VERSION ""

NS_ :

BS_:

BU_: Turbocharger OnBoardDataLogger OffBoardDiagnosticTool2 OffBoardDiagnosticTool1 FileServer ParkingBrakeController SeatControl2 FanDriveController SteeringColumnUnit CommunicationUnitRadio CommunicationUnitSatellite CommunicationUnitCellular PropulsionBatteryCharger ChassisController2 ChassisController1 EngineValveControl AuxiliaryHeater2 AuxiliaryHeater1 ClutchUnit RampControl InformationSystem1 SuspensionSystemController2 OilSensor VehicleDynamicStability ExhaustEmissionController TransmissionDisplay2 TransmissionDisplay1 ClimateControl2 WaterPumpController RearAxleSteeringController LightingOperatorControl SeatController1 IgnitionController2 IgnitionController1 TirePressureController CabController2 CabController1 PneumaticSystemController SuspensionSystemController1 HydraulicPumpController EnduranceBrakingSystem RetarderExhaustEngine2 OnBoardDiagnosticUnit HeadwayController RetarderExhaustEngine1 CabDisplay1 ManagementComputer VirtualTerminal OffVehicleGateway PowerTakeOffFront HitchControl AuxiliaryValveControl BodyController TractorTrailerBridge1 StarterSystem ElectricalSystem VehicleSecurity VehicleNavigation AerodynamicControl ElectricalChargingSystem ClimateControl1 TripRecorder InstrumentCluster SuspensionDriveAxle2 SuspensionDriveAxle1 SuspensionSteerAxle SteeringController FuelSystem CruiseControl RetarderDriveline RetarderEngine BrakesDriveAxle2 BrakesDriveAxle1 BrakesSystemController BrakesSteerAxle AxleDrive2 AxleDrive1 AxleSteering PowerTakeOff ShiftConsoleSecondary ShiftConsolePrimary Transmission2 Transmission1 Engine2 Engine1

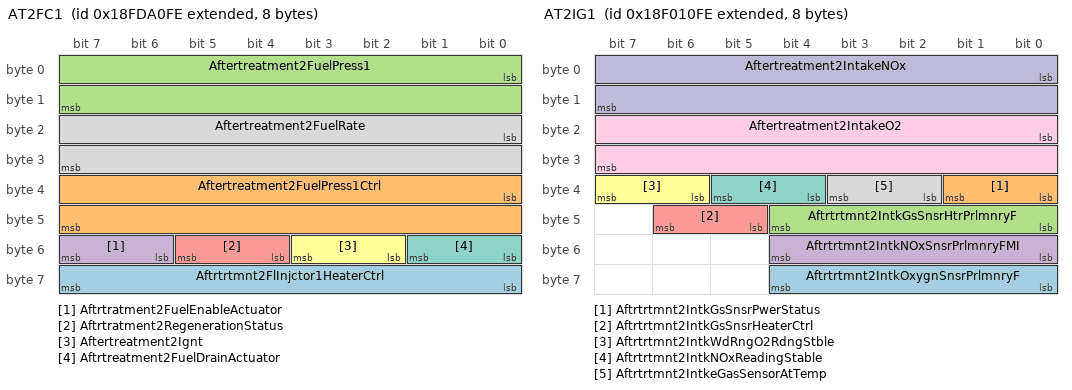
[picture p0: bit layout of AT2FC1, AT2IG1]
BO_ 2566758654 AT2FC1: 8 Vector__XXX
 SG_ Aftrtrtmnt2FlInjctor1HeaterCtrl : 56|8@1+ (0.4,0) [0|100] "%" Vector__XXX
 SG_ Aftertreatment2FuelPress1Ctrl : 32|16@1+ (0.0025,0) [0|160.6375] "%" Vector__XXX
 SG_ Aftertreatment2FuelPress1 : 0|16@1+ (0.1,0) [0|6425.5] "kPa" Vector__XXX
 SG_ Aftrtratment2FuelEnableActuator : 54|2@1+ (1,0) [0|3] "" Vector__XXX
 SG_ Aftrtratment2RegenerationStatus : 52|2@1+ (1,0) [0|3] "" Vector__XXX
 SG_ Aftertreatment2Ignt : 50|2@1+ (1,0) [0|3] "" Vector__XXX
 SG_ Aftrtreatment2FuelDrainActuator : 48|2@1+ (1,0) [0|3] "" Vector__XXX
 SG_ Aftertreatment2FuelRate : 16|16@1+ (0.05,0) [0|3212.75] "L/h" Vector__XXX

BO_ 2566753278 AT2GP: 8 Vector__XXX
 SG_ DslPrticulateFilterOutletPress2 : 16|16@1+ (0.1,0) [0|6425.5] "kPa" Vector__XXX
 SG_ DslPrticulateFilterIntakePress2 : 0|16@1+ (0.1,0) [0|6425.5] "kPa" Vector__XXX

BO_ 2566756862 AT2HI: 36 Vector__XXX
 SG_ Aftrtrtmnt2TtlNmbrOfActvRgnrtnMn : 224|32@1+ (1,0) [0|4294967295] "counts" Vector__XXX
 SG_ Aftrtrtmnt2TtlNmbrOfActvRgnrtnIn : 192|32@1+ (1,0) [0|4294967295] "counts" Vector__XXX
 SG_ Aftrtrtmnt2AvrgTmBtwnActvRgnrtns : 256|32@1+ (1,0) [0|4211081215] "s" Vector__XXX
 SG_ Aftrtrtmnt2TtlNmbrOfPssvRgnrtns : 160|32@1+ (1,0) [0|4294967295] "counts" Vector__XXX
 SG_ Aftrtrtmnt2TtlPssvRgnrationTime : 128|32@1+ (1,0) [0|4211081215] "s" Vector__XXX
 SG_ Aftrtrtmnt2TtlNmbrOfActvRgnrtns : 96|32@1+ (1,0) [0|4294967295] "counts" Vector__XXX
 SG_ Aftrtreatment2TotalDisabledTime : 64|32@1+ (1,0) [0|4211081215] "s" Vector__XXX
 SG_ Aftrtrtmnt2TtalRegenerationTime : 32|32@1+ (1,0) [0|4211081215] "s" Vector__XXX
 SG_ Aftertreatment2TotalFuelUsed : 0|32@1+ (0.5,0) [0|2105540607.5] "L" Vector__XXX

BO_ 2565869822 AT2IG1: 8 Vector__XXX
 SG_ Aftrtrtmnt2IntkOxygnSnsrPrlmnryF : 56|5@1+ (1,0) [0|31] "" Vector__XXX
 SG_ Aftrtrtmnt2IntkGsSnsrPwerStatus : 32|2@1+ (1,0) [0|3] "" Vector__XXX
 SG_ Aftrtrtmnt2IntkGsSnsrHtrPrlmnryF : 40|5@1+ (1,0) [0|31] "" Vector__XXX
 SG_ Aftrtrtmnt2IntkNOxSnsrPrlmnryFMI : 48|5@1+ (1,0) [0|31] "" Vector__XXX
 SG_ Aftrtrtmnt2IntkGsSnsrHeaterCtrl : 45|2@1+ (1,0) [0|3] "" Vector__XXX
 SG_ Aftrtrtmnt2IntkWdRngO2RdngStble : 38|2@1+ (1,0) [0|3] "" Vector__XXX
 SG_ Aftrtrtmnt2IntkNOxReadingStable : 36|2@1+ (1,0) [0|3] "" Vector__XXX
 SG_ Aftrtrtmnt2IntkeGasSensorAtTemp : 34|2@1+ (1,0) [0|3] "" Vector__XXX
 SG_ Aftertreatment2IntakeO2 : 16|16@1+ (0.000514,-12) [-12|21] "%" Vector__XXX
 SG_ Aftertreatment2IntakeNOx : 0|16@1+ (0.05,-200) [-200|3012.75] "ppm" Vector__XXX

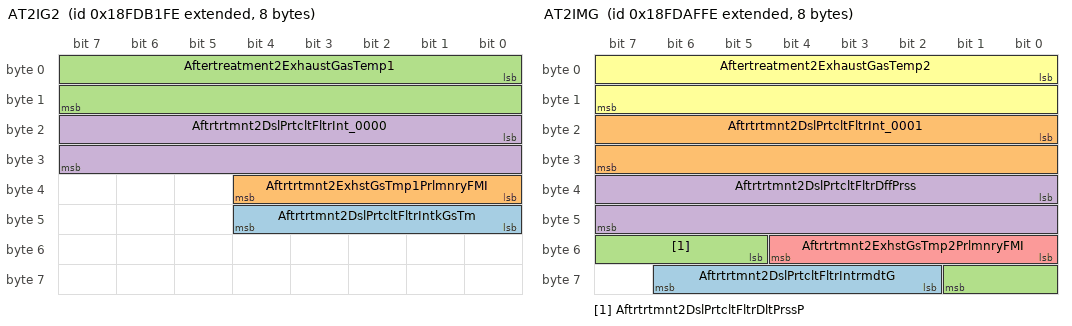
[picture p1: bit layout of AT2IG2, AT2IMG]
BO_ 2566763006 AT2IG2: 8 Vector__XXX
 SG_ Aftrtrtmnt2DslPrtcltFltrIntkGsTm : 40|5@1+ (1,0) [0|31] "" Vector__XXX
 SG_ Aftrtrtmnt2ExhstGsTmp1PrlmnryFMI : 32|5@1+ (1,0) [0|31] "" Vector__XXX
 SG_ Aftertreatment2ExhaustGasTemp1 : 0|16@1+ (0.03125,-273) [-273|1734.96875] "deg C" Vector__XXX
 SG_ Aftrtrtmnt2DslPrtcltFltrInt_0000 : 16|16@1+ (0.03125,-273) [-273|1734.96875] "deg C" Vector__XXX

BO_ 2566762494 AT2IMG: 8 Vector__XXX
 SG_ Aftrtrtmnt2DslPrtcltFltrIntrmdtG : 58|5@1+ (1,0) [0|31] "" Vector__XXX
 SG_ Aftrtrtmnt2DslPrtcltFltrInt_0001 : 16|16@1+ (0.03125,-273) [-273|1734.96875] "deg C" Vector__XXX
 SG_ Aftrtrtmnt2DslPrtcltFltrDltPrssP : 53|5@1+ (1,0) [0|31] "" Vector__XXX
 SG_ Aftrtrtmnt2DslPrtcltFltrDffPrss : 32|16@1+ (0.1,0) [0|6425.5] "kPa" Vector__XXX
 SG_ Aftrtrtmnt2ExhstGsTmp2PrlmnryFMI : 48|5@1+ (1,0) [0|31] "" Vector__XXX
 SG_ Aftertreatment2ExhaustGasTemp2 : 0|16@1+ (0.03125,-273) [-273|1734.96875] "deg C" Vector__XXX

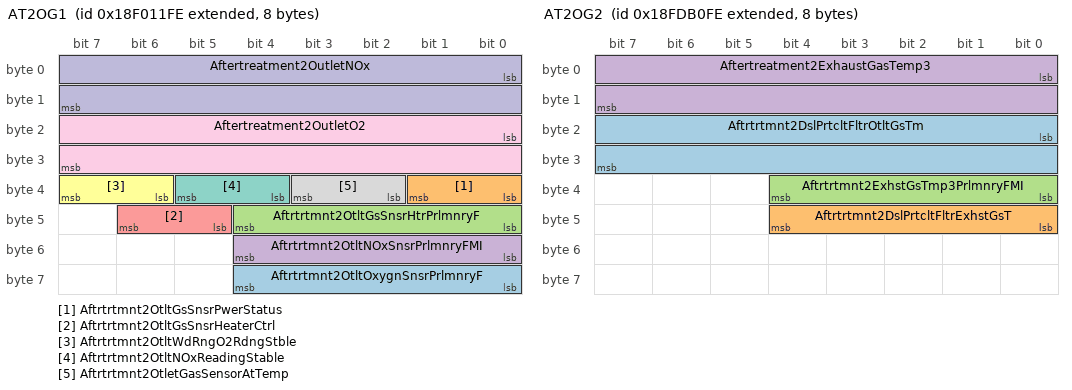
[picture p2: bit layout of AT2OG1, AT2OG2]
BO_ 2565870078 AT2OG1: 8 Vector__XXX
 SG_ Aftrtrtmnt2OtltOxygnSnsrPrlmnryF : 56|5@1+ (1,0) [0|31] "" Vector__XXX
 SG_ Aftrtrtmnt2OtltGsSnsrPwerStatus : 32|2@1+ (1,0) [0|3] "" Vector__XXX
 SG_ Aftrtrtmnt2OtltGsSnsrHtrPrlmnryF : 40|5@1+ (1,0) [0|31] "" Vector__XXX
 SG_ Aftrtrtmnt2OtltNOxSnsrPrlmnryFMI : 48|5@1+ (1,0) [0|31] "" Vector__XXX
 SG_ Aftrtrtmnt2OtltGsSnsrHeaterCtrl : 45|2@1+ (1,0) [0|3] "" Vector__XXX
 SG_ Aftrtrtmnt2OtltWdRngO2RdngStble : 38|2@1+ (1,0) [0|3] "" Vector__XXX
 SG_ Aftrtrtmnt2OtltNOxReadingStable : 36|2@1+ (1,0) [0|3] "" Vector__XXX
 SG_ Aftrtrtmnt2OtletGasSensorAtTemp : 34|2@1+ (1,0) [0|3] "" Vector__XXX
 SG_ Aftertreatment2OutletO2 : 16|16@1+ (0.000514,-12) [-12|21] "%" Vector__XXX
 SG_ Aftertreatment2OutletNOx : 0|16@1+ (0.05,-200) [-200|3012.75] "ppm" Vector__XXX

BO_ 2566762750 AT2OG2: 8 Vector__XXX
 SG_ Aftrtrtmnt2DslPrtcltFltrOtltGsTm : 16|16@1+ (0.03125,-273) [-273|1734.96875] "deg C" Vector__XXX
 SG_ Aftrtrtmnt2DslPrtcltFltrExhstGsT : 40|5@1+ (1,0) [0|31] "" Vector__XXX
 SG_ Aftrtrtmnt2ExhstGsTmp3PrlmnryFMI : 32|5@1+ (1,0) [0|31] "" Vector__XXX
 SG_ Aftertreatment2ExhaustGasTemp3 : 0|16@1+ (0.03125,-273) [-273|1734.96875] "deg C" Vector__XXX

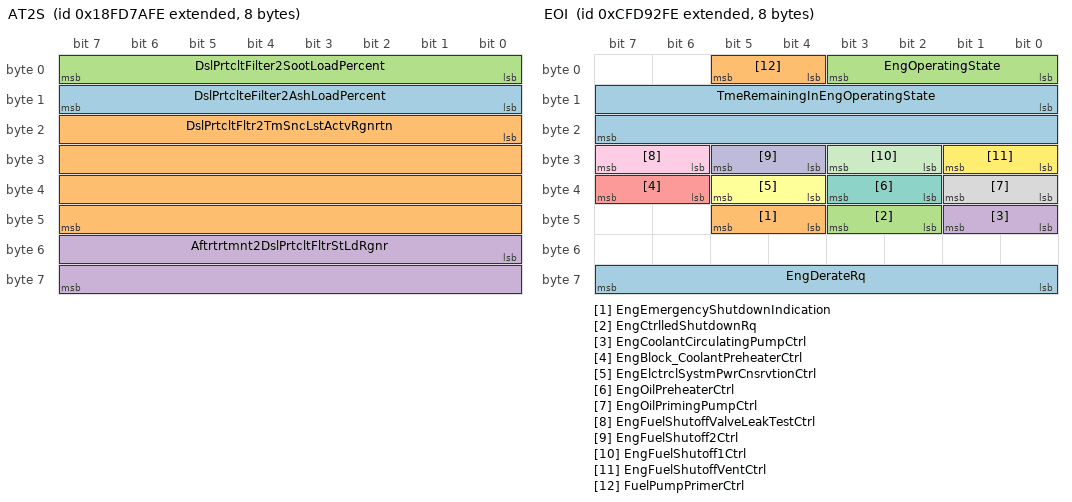
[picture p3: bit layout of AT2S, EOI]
BO_ 2566748926 AT2S: 8 Vector__XXX
 SG_ DslPrtclteFilter2AshLoadPercent : 8|8@1+ (1,0) [0|250] "%" Vector__XXX
 SG_ DslPrtcltFltr2TmSncLstActvRgnrtn : 16|32@1+ (1,0) [0|4211081215] "s" Vector__XXX
 SG_ DslPrtcltFilter2SootLoadPercent : 0|8@1+ (1,0) [0|250] "%" Vector__XXX
 SG_ Aftrtrtmnt2DslPrtcltFltrStLdRgnr : 48|16@1+ (0.0025,0) [0|160.6375] "%" Vector__XXX

BO_ 2566748414 AT2TI: 32 Vector__XXX
 SG_ Aftrtrtmnt2TrpNmbrOfActvRgnrtnMn : 224|32@1+ (1,0) [0|4294967295] "counts" Vector__XXX
 SG_ Aftrtrtmnt2TrpNmbrOfActvRgnrtnIn : 192|32@1+ (1,0) [0|4294967295] "counts" Vector__XXX
 SG_ Aftrtrtmnt2TrpNmbrOfPssvRgnrtns : 160|32@1+ (1,0) [0|4294967295] "counts" Vector__XXX
 SG_ Aftrtrtmnt2TrpPssvRgnrationTime : 128|32@1+ (1,0) [0|4211081215] "s" Vector__XXX
 SG_ Aftrtrtmnt2TrpNmbrOfActvRgnrtns : 96|32@1+ (1,0) [0|4294967295] "counts" Vector__XXX
 SG_ Aftertreatment2TripDisabledTime : 64|32@1+ (1,0) [0|4211081215] "s" Vector__XXX
 SG_ Aftrtrtmnt2TrpActvRgnrationTime : 32|32@1+ (1,0) [0|4211081215] "s" Vector__XXX
 SG_ Aftertreatment2TripFuelUsed : 0|32@1+ (0.5,0) [0|2105540607.5] "L" Vector__XXX

BO_ 2365428478 EOI: 8 Vector__XXX
 SG_ EngDerateRq : 56|8@1+ (0.4,0) [0|100] "%" Vector__XXX
 SG_ EngEmergencyShutdownIndication : 44|2@1+ (1,0) [0|3] "" Vector__XXX
 SG_ EngCtrlledShutdownRq : 42|2@1+ (1,0) [0|3] "" Vector__XXX
 SG_ EngCoolantCirculatingPumpCtrl : 40|2@1+ (1,0) [0|3] "" Vector__XXX
 SG_ EngBlock_CoolantPreheaterCtrl : 38|2@1+ (1,0) [0|3] "" Vector__XXX
 SG_ EngElctrclSystmPwrCnsrvtionCtrl : 36|2@1+ (1,0) [0|3] "" Vector__XXX
 SG_ EngOilPreheaterCtrl : 34|2@1+ (1,0) [0|3] "" Vector__XXX
 SG_ EngOilPrimingPumpCtrl : 32|2@1+ (1,0) [0|3] "" Vector__XXX
 SG_ EngFuelShutoffValveLeakTestCtrl : 30|2@1+ (1,0) [0|3] "" Vector__XXX
 SG_ EngFuelShutoff2Ctrl : 28|2@1+ (1,0) [0|3] "" Vector__XXX
 SG_ EngFuelShutoff1Ctrl : 26|2@1+ (1,0) [0|3] "" Vector__XXX
 SG_ EngFuelShutoffVentCtrl : 24|2@1+ (1,0) [0|3] "" Vector__XXX
 SG_ TmeRemainingInEngOperatingState : 8|16@1+ (1,0) [0|64255] "s" Vector__XXX
 SG_ FuelPumpPrimerCtrl : 4|2@1+ (1,0) [0|3] "" Vector__XXX
 SG_ EngOperatingState : 0|4@1+ (1,0) [0|15] "" Vector__XXX

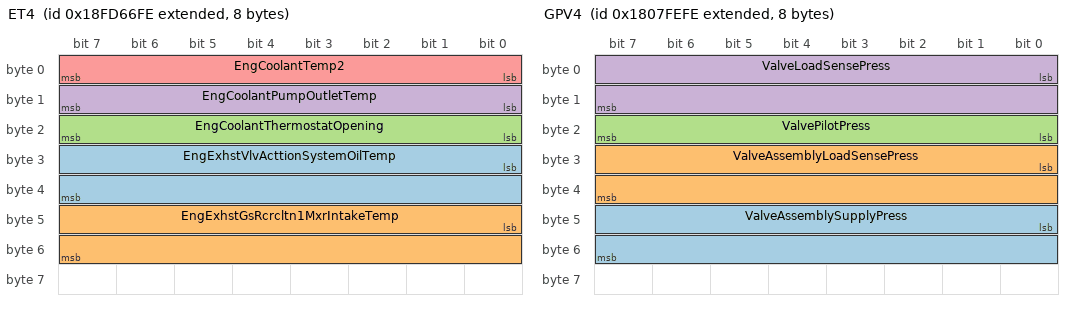
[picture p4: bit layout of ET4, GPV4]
BO_ 2566743806 ET4: 8 Vector__XXX
 SG_ EngExhstVlvActtionSystemOilTemp : 24|16@1+ (0.03125,-273) [-273|1734.96875] "deg C" Vector__XXX
 SG_ EngExhstGsRcrcltn1MxrIntakeTemp : 40|16@1+ (0.03125,-273) [-273|1734.96875] "deg C" Vector__XXX
 SG_ EngCoolantThermostatOpening : 16|8@1+ (0.4,0) [0|100] "%" Vector__XXX
 SG_ EngCoolantPumpOutletTemp : 8|8@1+ (1,-40) [-40|210] "deg C" Vector__XXX
 SG_ EngCoolantTemp2 : 0|8@1+ (1,-40) [-40|210] "deg C" Vector__XXX

BO_ 2499635454 GCVW: 8 Vector__XXX
 SG_ NetVehicleWeightChange : 24|24@1+ (2,-16449535) [-16449535|16449535] "kg" Vector__XXX
 SG_ GrossCombinationWeight : 0|24@1+ (2,0) [0|32899070] "kg" Vector__XXX

BO_ 2550660862 GPV4: 8 Vector__XXX
 SG_ ValveAssemblySupplyPress : 40|16@1+ (5,0) [0|321275] "kPa" Vector__XXX
 SG_ ValveAssemblyLoadSensePress : 24|16@1+ (5,0) [0|321275] "kPa" Vector__XXX
 SG_ ValvePilotPress : 16|8@1+ (16,0) [0|4000] "kPa" Vector__XXX
 SG_ ValveLoadSensePress : 0|16@1+ (5,0) [0|321275] "kPa" Vector__XXX

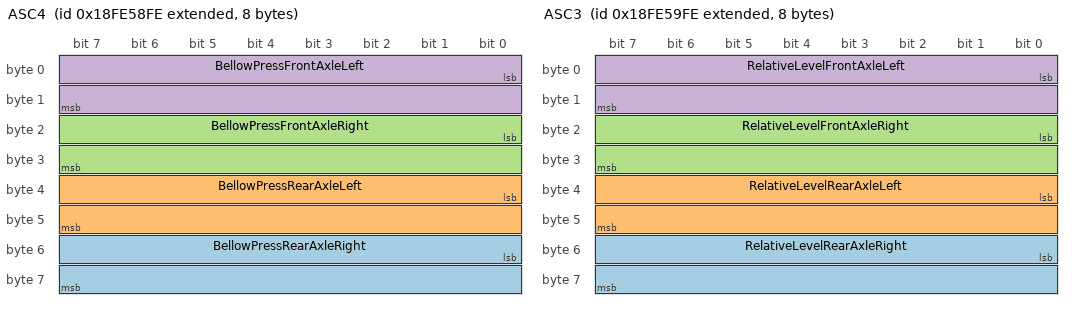
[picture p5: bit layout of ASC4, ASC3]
BO_ 2566805758 ASC4: 8 Vector__XXX
 SG_ BellowPressRearAxleRight : 48|16@1+ (0.1,0) [0|6425.5] "kPa" Vector__XXX
 SG_ BellowPressRearAxleLeft : 32|16@1+ (0.1,0) [0|6425.5] "kPa" Vector__XXX
 SG_ BellowPressFrontAxleRight : 16|16@1+ (0.1,0) [0|6425.5] "kPa" Vector__XXX
 SG_ BellowPressFrontAxleLeft : 0|16@1+ (0.1,0) [0|6425.5] "kPa" Vector__XXX

BO_ 2566806014 ASC3: 8 Vector__XXX
 SG_ RelativeLevelRearAxleRight : 48|16@1+ (0.1,-3200) [-3200|3225.5] "mm" Vector__XXX
 SG_ RelativeLevelRearAxleLeft : 32|16@1+ (0.1,-3200) [-3200|3225.5] "mm" Vector__XXX
 SG_ RelativeLevelFrontAxleRight : 16|16@1+ (0.1,-3200) [-3200|3225.5] "mm" Vector__XXX
 SG_ RelativeLevelFrontAxleLeft : 0|16@1+ (0.1,-3200) [-3200|3225.5] "mm" Vector__XXX

BO_ 2362638078 ASC2: 8 Vector__XXX
 SG_ SpeedDependentLevelCtrlRq : 56|2@1+ (1,0) [0|3] "" Vector__XXX
 SG_ PrhbtAutomaticAirSuspensionCtrl : 58|2@1+ (1,0) [0|3] "" Vector__XXX
 SG_ MemoryLevelRq : 60|4@1+ (1,0) [0|15] "" Vector__XXX
 SG_ AllowLevelCtrlDuringBrakingCmd : 54|2@1+ (1,0) [0|3] "" Vector__XXX
 SG_ ProhibitAirSuspensionCtrl : 52|2@1+ (1,0) [0|3] "" Vector__XXX
 SG_ KneelingCmdRearAxle : 50|2@1+ (1,0) [0|3] "" Vector__XXX
 SG_ KneelingCmdFrontAxle : 48|2@1+ (1,0) [0|3] "" Vector__XXX
 SG_ DamperStiffnessRqLift_TagAxle : 40|8@1+ (0.4,0) [0|100] "%" Vector__XXX
 SG_ DamperStiffnessRqRearAxle : 32|8@1+ (0.4,0) [0|100] "%" Vector__XXX
 SG_ DamperStiffnessRqFrontAxle : 24|8@1+ (0.4,0) [0|100] "%" Vector__XXX
 SG_ LevelCtrlModeRq : 16|4@1+ (1,0) [0|15] "" Vector__XXX
 SG_ NominalLevelRqRearAxle : 12|4@1+ (1,0) [0|15] "" Vector__XXX
 SG_ NominalLevelRqFrontAxle : 8|4@1+ (1,0) [0|15] "" Vector__XXX
 SG_ KneelingCtrlModeRq : 6|2@1+ (1,0) [0|3] "" Vector__XXX
 SG_ KneelingRqRightSide : 4|2@1+ (1,0) [0|3] "" Vector__XXX
 SG_ KneelingRqLeftSide : 2|2@1+ (1,0) [0|3] "" Vector__XXX
 SG_ AutomaticTractionHelp : 0|2@1+ (1,0) [0|3] "" Vector__XXX
 SG_ LiftAxle2PosCmd : 22|2@1+ (1,0) [0|3] "" Vector__XXX
 SG_ LiftAxle1PosCmd : 20|2@1+ (1,0) [0|3] "" Vector__XXX

BO_ 2365479678 ASC1: 8 Vector__XXX
 SG_ SpeedDependantLevelCtrlStatus : 54|2@1+ (1,0) [0|3] "" Vector__XXX
 SG_ MemoryLevel : 60|4@1+ (1,0) [0|15] "" Vector__XXX
 SG_ AllwLvelCtrlDuringBrakingStatus : 52|2@1+ (1,0) [0|3] "" Vector__XXX
 SG_ SspensionCtrlRefusalInformation : 56|4@1+ (1,0) [0|15] "" Vector__XXX
 SG_ SuspensionRemoteCtrl2 : 50|2@1+ (1,0) [0|3] "" Vector__XXX
 SG_ SuspensionRemoteCtrl1 : 48|2@1+ (1,0) [0|3] "" Vector__XXX
 SG_ RearAxleInBumperRange : 42|2@1+ (1,0) [0|3] "" Vector__XXX
 SG_ FrontAxleInBumperRange : 40|2@1+ (1,0) [0|3] "" Vector__XXX
 SG_ DoorRelease : 36|2@1+ (1,0) [0|3] "" Vector__XXX
 SG_ VehicleMotionInhibit : 34|2@1+ (1,0) [0|3] "" Vector__XXX
 SG_ SecurityDevice : 32|2@1+ (1,0) [0|3] "" Vector__XXX
 SG_ LevelCtrlMode : 28|4@1+ (1,0) [0|15] "" Vector__XXX
 SG_ KneelingInformation : 24|4@1+ (1,0) [0|15] "" Vector__XXX
 SG_ LiftingCtrlModeRearAxle : 22|2@1+ (1,0) [0|3] "" Vector__XXX
 SG_ LiftingCtrlModeFrontAxle : 20|2@1+ (1,0) [0|3] "" Vector__XXX
 SG_ LoweringCtrlModeRearAxle : 18|2@1+ (1,0) [0|3] "" Vector__XXX
 SG_ LoweringCtrlModeFrontAxle : 16|2@1+ (1,0) [0|3] "" Vector__XXX
 SG_ AboveNominalLevelRearAxle : 14|2@1+ (1,0) [0|3] "" Vector__XXX
 SG_ AboveNominalLevelFrontAxle : 12|2@1+ (1,0) [0|3] "" Vector__XXX
 SG_ BelowNominalLevelRearAxle : 10|2@1+ (1,0) [0|3] "" Vector__XXX
 SG_ BelowNominalLevelFrontAxle : 8|2@1+ (1,0) [0|3] "" Vector__XXX
 SG_ NominalLevelRearAxle : 4|4@1+ (1,0) [0|15] "" Vector__XXX
 SG_ NominalLevelFrontAxle : 0|4@1+ (1,0) [0|15] "" Vector__XXX
 SG_ LiftAxle2Pos : 46|2@1+ (1,0) [0|3] "" Vector__XXX
 SG_ LiftAxle1Pos : 38|2@1+ (1,0) [0|3] "" Vector__XXX

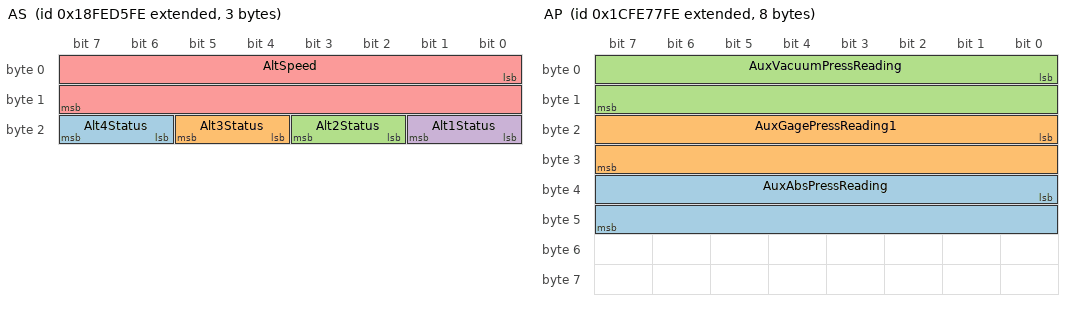
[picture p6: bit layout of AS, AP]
BO_ 2566837758 AS: 3 Vector__XXX
 SG_ Alt4Status : 22|2@1+ (1,0) [0|3] "" Vector__XXX
 SG_ Alt3Status : 20|2@1+ (1,0) [0|3] "" Vector__XXX
 SG_ Alt2Status : 18|2@1+ (1,0) [0|3] "" Vector__XXX
 SG_ Alt1Status : 16|2@1+ (1,0) [0|3] "" Vector__XXX
 SG_ AltSpeed : 0|16@1+ (0.5,0) [0|32127.5] "rpm" Vector__XXX

BO_ 2633922558 AP: 8 Vector__XXX
 SG_ AuxAbsPressReading : 32|16@1+ (0.5,0) [0|32127.5] "kPa" Vector__XXX
 SG_ AuxGagePressReading1 : 16|16@1+ (0.5,0) [0|32127.5] "kPa" Vector__XXX
 SG_ AuxVacuumPressReading : 0|16@1+ (0.5,0) [0|32127.5] "kPa" Vector__XXX

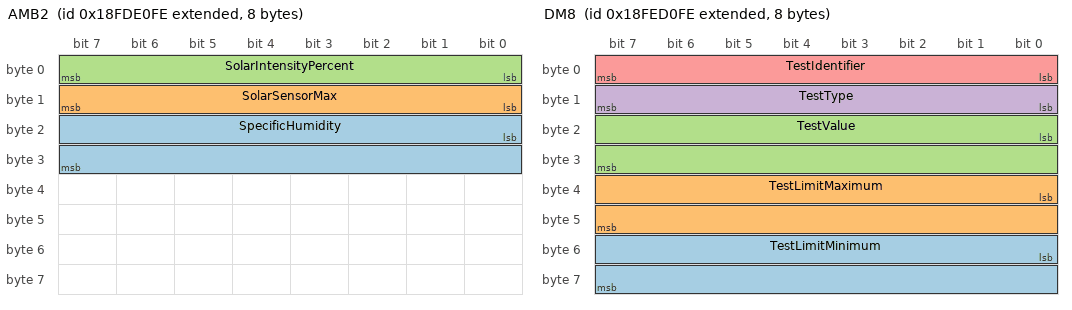
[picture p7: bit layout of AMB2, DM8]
BO_ 2566775038 AMB2: 8 Vector__XXX
 SG_ SpecificHumidity : 16|16@1+ (0.01,0) [0|642.55] "g/kg" Vector__XXX
 SG_ SolarSensorMax : 8|8@1+ (0.4,0) [0|100] "mW/cm/cm" Vector__XXX
 SG_ SolarIntensityPercent : 0|8@1+ (0.4,0) [0|100] "%" Vector__XXX

BO_ 2566836478 DM8: 8 Vector__XXX
 SG_ TestLimitMinimum : 48|16@1+ (1,0) [0|64255] "" Vector__XXX
 SG_ TestLimitMaximum : 32|16@1+ (1,0) [0|64255] "" Vector__XXX
 SG_ TestValue : 16|16@1+ (1,0) [0|64255] "" Vector__XXX
 SG_ TestType : 8|8@1+ (1,0) [1|64] "" Vector__XXX
 SG_ TestIdentifier : 0|8@1+ (1,0) [1|64] "" Vector__XXX

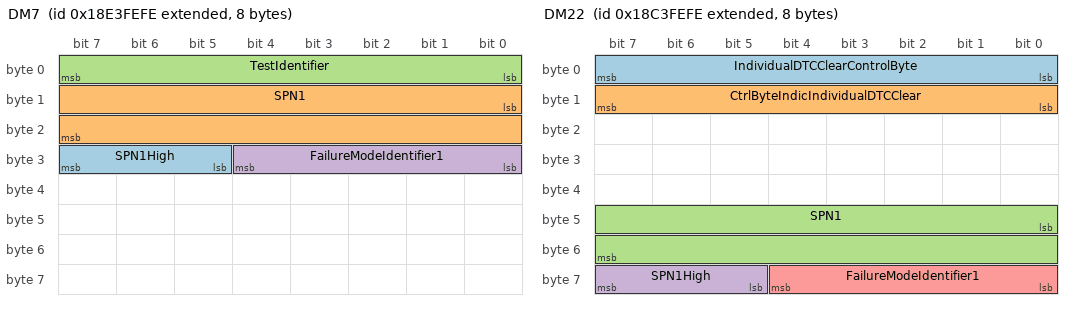
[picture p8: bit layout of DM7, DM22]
BO_ 2565078782 DM7: 8 Vector__XXX
 SG_ SPN1High : 29|3@1+ (1,0) [0|7] "" Vector__XXX
 SG_ SPN1 : 8|16@1+ (1,0) [0|65536] "" Vector__XXX
 SG_ TestIdentifier : 0|8@1+ (1,0) [1|64] "" Vector__XXX
 SG_ FailureModeIdentifier1 : 24|5@1+ (1,0) [0|0] "" Vector__XXX

BO_ 2566836222 DM6: 22 Vector__XXX
 SG_ FlashRedStopLamp : 12|2@1+ (1,0) [0|3] "" Vector__XXX
 SG_ FlashProtectLamp : 8|2@1+ (1,0) [0|3] "" Vector__XXX
 SG_ FlashMalfuncIndicatorLamp : 14|2@1+ (1,0) [0|3] "" Vector__XXX
 SG_ FlashAmberWarningLamp : 10|2@1+ (1,0) [0|3] "" Vector__XXX
 SG_ MalfunctionIndicatorLampStatus : 6|2@1+ (1,0) [0|3] "" Vector__XXX
 SG_ RedStopLampState : 4|2@1+ (1,0) [0|3] "" Vector__XXX
 SG_ AmberWarningLampStatus : 2|2@1+ (1,0) [0|3] "" Vector__XXX
 SG_ ProtectLampStatus : 0|2@1+ (1,0) [0|3] "" Vector__XXX
 SG_ DTC5 : 144|32@1+ (1,0) [0|4294967295] "" Vector__XXX
 SG_ DTC4 : 112|32@1+ (1,0) [0|4294967295] "" Vector__XXX
 SG_ DTC3 : 80|32@1+ (1,0) [0|4294967295] "" Vector__XXX
 SG_ DTC2 : 48|32@1+ (1,0) [0|4294967295] "" Vector__XXX
 SG_ DTC1 : 16|32@1+ (1,0) [0|4294967295] "" Vector__XXX

BO_ 2566835966 DM5: 8 Vector__XXX
 SG_ BoostPressureControlSystemStatus : 57|1@1- (1,0) [0|0] "" Vector__XXX
 SG_ DieselParticulateFilterStatus : 58|1@1- (1,0) [0|0] "" Vector__XXX
 SG_ NOxConvertingCatalystAdsorberSta : 59|1@1- (1,0) [0|0] "" Vector__XXX
 SG_ NMHCConvertingCatalystStatus : 60|1@1- (1,0) [0|0] "" Vector__XXX
 SG_ BoostPressureControlSystemSuppor : 41|1@1- (1,0) [0|0] "" Vector__XXX
 SG_ DieselParticulateFilterSupport : 42|1@1- (1,0) [0|0] "" Vector__XXX
 SG_ NOxConvertingCatalystAdsorberSup : 43|1@1- (1,0) [0|0] "" Vector__XXX
 SG_ NMHCConvertingCatalystSupport : 44|1@1- (1,0) [0|0] "" Vector__XXX
 SG_ MisfireMonitoringSupport : 24|1@1+ (1,0) [0|0] "" Vector__XXX
 SG_ OBDCompliance : 16|8@1+ (1,0) [0|240] "" Vector__XXX
 SG_ PreviouslyActiveTroubleCodes : 8|8@1+ (1,0) [0|240] "" Vector__XXX
 SG_ ActiveTroubleCodes : 0|8@1+ (1,0) [0|240] "" Vector__XXX
 SG_ SecondAirSystemMonStatus : 51|1@1+ (1,0) [0|1] "" Vector__XXX
 SG_ EvaporativeSystemMonStatus : 50|1@1+ (1,0) [0|1] "" Vector__XXX
 SG_ ACSystemRefrigerantMonStatus : 52|1@1+ (1,0) [0|1] "" Vector__XXX
 SG_ OxygenSensorHeaterMonStatus : 54|1@1+ (1,0) [0|1] "" Vector__XXX
 SG_ OxygenSensorMonStatus : 53|1@1+ (1,0) [0|1] "" Vector__XXX
 SG_ EGRSystemMonitoringStatus : 55|1@1+ (1,0) [0|1] "" Vector__XXX
 SG_ CatalystMonStatus : 48|1@1+ (1,0) [0|1] "" Vector__XXX
 SG_ ColdStartAidSystemMonStatus : 56|1@1+ (1,0) [0|1] "" Vector__XXX
 SG_ HeatedCatalystMonStatus : 49|1@1+ (1,0) [0|0] "" Vector__XXX
 SG_ CatalystMonSupp : 32|1@1+ (1,0) [0|1] "" Vector__XXX
 SG_ ColdStartAidSystemMonSupp : 40|1@1+ (1,0) [0|1] "" Vector__XXX
 SG_ HeatedCatalystMonSupp : 33|1@1+ (1,0) [0|0] "" Vector__XXX
 SG_ EvaporativeSystemMonSupp : 34|1@1+ (1,0) [0|1] "" Vector__XXX
 SG_ SecondAirSystemMonSupp : 35|1@1+ (1,0) [0|1] "" Vector__XXX
 SG_ ACSystemRefrigerantMonSupp : 36|1@1+ (1,0) [0|1] "" Vector__XXX
 SG_ OxygenSensorMonSupp : 37|1@1+ (1,0) [0|1] "" Vector__XXX
 SG_ OxygenSensorHeaterMonSupp : 38|1@1+ (1,0) [0|1] "" Vector__XXX
 SG_ EGRSystemMonitoringSupp : 39|1@1+ (1,0) [0|1] "" Vector__XXX
 SG_ MisfireMonitoringStatus : 28|1@1+ (1,0) [0|0] "" Vector__XXX
 SG_ ComprehensiveCompMonStatus : 30|1@1+ (1,0) [0|1] "" Vector__XXX
 SG_ FuelSystemMonitoringStatus : 29|1@1+ (1,0) [0|1] "" Vector__XXX
 SG_ ComprehensiveComponentMonSupp : 26|1@1+ (1,0) [0|0] "" Vector__XXX
 SG_ FuelSystemMonitoringSupport : 25|1@1+ (1,0) [0|1] "" Vector__XXX

BO_ 2566835710 DM4: 13 Vector__XXX
 SG_ EngIntakeManifold1Press : 48|8@1+ (2,0) [0|500] "kPa" Vector__XXX
 SG_ FreezeFrameLength : 0|8@1+ (1,0) [0|255] "Byte" Vector__XXX
 SG_ EngSpeed : 56|16@1+ (0.125,0) [0|8031.875] "rpm" Vector__XXX
 SG_ EngTorqueMode : 40|4@1+ (1,0) [0|15] "" Vector__XXX
 SG_ WheelBasedVehicleSpeed : 88|16@1+ (0.00390625,0) [0|250.996] "km/h" Vector__XXX
 SG_ EngPercentLoadAtCurrentSpeed : 72|8@1+ (1,0) [0|250] "%" Vector__XXX
 SG_ EngineCoolantTemperature : 80|8@1+ (1,-40) [-40|210] "deg C" Vector__XXX
 SG_ DTC1 : 8|32@1+ (1,0) [0|4294967295] "" Vector__XXX

BO_ 2566835454 DM3: 0 Vector__XXX

BO_ 2566764542 DM25: 13 Vector__XXX
 SG_ ExpandedFreezeFrameLength : 0|8@1+ (1,0) [0|255] "Byte" Vector__XXX
 SG_ DTC1 : 8|32@1+ (1,0) [0|4294967295] "" Vector__XXX

BO_ 2566764286 DM24: 12 Vector__XXX
 SG_ SPNSupported1High : 21|3@1+ (1,0) [0|7] "" Vector__XXX
 SG_ SPNSupportTypeSTR3 : 82|1@1+ (1,0) [0|1] "" Vector__XXX
 SG_ SPNSupportTypeSTR2 : 81|1@1+ (1,0) [0|1] "" Vector__XXX
 SG_ SPNSupportTypeEFF3 : 80|1@1+ (1,0) [0|1] "" Vector__XXX
 SG_ SPNSupportTypeEFF2 : 48|1@1+ (1,0) [0|1] "" Vector__XXX
 SG_ SPNSupportTypeDS3 : 50|1@1+ (1,0) [0|1] "" Vector__XXX
 SG_ SPNSupportTypeDS2 : 49|1@1+ (1,0) [0|1] "" Vector__XXX
 SG_ SPNSupported3High : 85|3@1+ (1,0) [0|7] "" Vector__XXX
 SG_ SPNSupported2High : 53|3@1+ (1,0) [0|7] "" Vector__XXX
 SG_ SPNSupported3 : 64|16@1+ (1,0) [0|65535] "" Vector__XXX
 SG_ SPNSupported2 : 32|16@1+ (1,0) [0|65535] "" Vector__XXX
 SG_ SPNDataLength3 : 88|8@1+ (1,0) [0|240] "" Vector__XXX
 SG_ SPNSupportTypeSTR1 : 18|1@1+ (1,0) [0|1] "" Vector__XXX
 SG_ SPNSupportTypeDS1 : 17|1@1+ (1,0) [0|1] "" Vector__XXX
 SG_ SPNSupportTypeEFF1 : 16|1@1+ (1,0) [0|1] "" Vector__XXX
 SG_ SPNDataLength2 : 56|8@1+ (1,0) [0|240] "" Vector__XXX
 SG_ SPNDataLength1 : 24|8@1+ (1,0) [0|240] "" Vector__XXX
 SG_ SPNSupported1 : 0|16@1+ (1,0) [0|65535] "" Vector__XXX

BO_ 2566764030 DM23: 22 Vector__XXX
 SG_ FlashRedStopLamp : 12|2@1+ (1,0) [0|3] "" Vector__XXX
 SG_ FlashProtectLamp : 8|2@1+ (1,0) [0|3] "" Vector__XXX
 SG_ FlashMalfuncIndicatorLamp : 14|2@1+ (1,0) [0|3] "" Vector__XXX
 SG_ FlashAmberWarningLamp : 10|2@1+ (1,0) [0|3] "" Vector__XXX
 SG_ MalfunctionIndicatorLampStatus : 6|2@1+ (1,0) [0|3] "" Vector__XXX
 SG_ RedStopLampState : 4|2@1+ (1,0) [0|3] "" Vector__XXX
 SG_ AmberWarningLampStatus : 2|2@1+ (1,0) [0|3] "" Vector__XXX
 SG_ ProtectLampStatus : 0|2@1+ (1,0) [0|3] "" Vector__XXX
 SG_ DTC5 : 144|32@1+ (1,0) [0|4294967295] "" Vector__XXX
 SG_ DTC4 : 112|32@1+ (1,0) [0|4294967295] "" Vector__XXX
 SG_ DTC3 : 80|32@1+ (1,0) [0|4294967295] "" Vector__XXX
 SG_ DTC2 : 48|32@1+ (1,0) [0|4294967295] "" Vector__XXX
 SG_ DTC1 : 16|32@1+ (1,0) [0|4294967295] "" Vector__XXX

BO_ 2562981630 DM22: 8 Vector__XXX
 SG_ IndividualDTCClearControlByte : 0|8@1+ (1,0) [0|255] "" Vector__XXX
 SG_ CtrlByteIndicIndividualDTCClear : 8|8@1+ (1,0) [0|255] "" Vector__XXX
 SG_ SPN1 : 40|16@1+ (1,0) [0|65536] "" Vector__XXX
 SG_ SPN1High : 61|3@1+ (1,0) [0|7] "" Vector__XXX
 SG_ FailureModeIdentifier1 : 56|5@1+ (1,0) [0|0] "" Vector__XXX

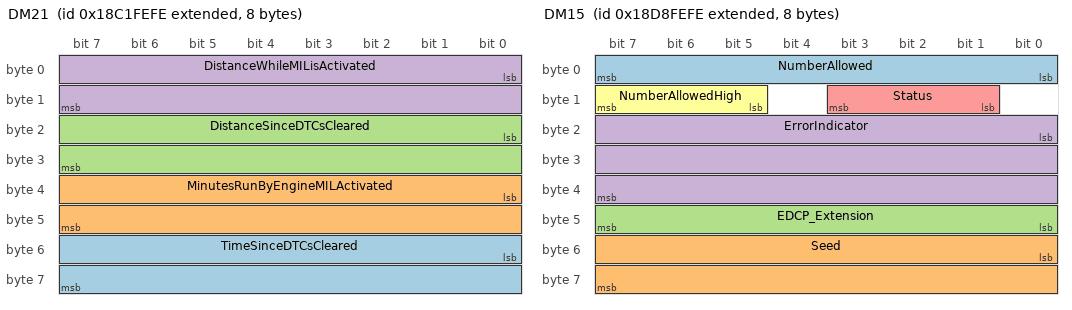
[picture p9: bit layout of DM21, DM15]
BO_ 2562850558 DM21: 8 Vector__XXX
 SG_ TimeSinceDTCsCleared : 48|16@1+ (1,0) [0|64255] "mins" Vector__XXX
 SG_ MinutesRunByEngineMILActivated : 32|16@1+ (1,0) [0|64255] "mins" Vector__XXX
 SG_ DistanceSinceDTCsCleared : 16|16@1+ (1,0) [0|64255] "km" Vector__XXX
 SG_ DistanceWhileMILisActivated : 0|16@1+ (1,0) [0|64255] "km" Vector__XXX

BO_ 2562916094 DM20: 11 Vector__XXX
 SG_ ApplSysMonitorDenominator : 72|16@1+ (1,0) [0|65535] "" Vector__XXX
 SG_ ApplSysMonitorNumerator : 56|16@1+ (1,0) [0|65535] "" Vector__XXX
 SG_ SPNofApplSysMonitor : 32|24@1+ (1,0) [0|524287] "" Vector__XXX
 SG_ OBDMonitoringCondEncountered : 16|16@1+ (1,0) [0|65535] "" Vector__XXX
 SG_ IgnitionCycleCounter : 0|16@1+ (1,0) [0|65535] "" Vector__XXX

BO_ 2566835198 DM2: 22 Vector__XXX
 SG_ MalfunctionIndicatorLampStatus : 6|2@1+ (1,0) [0|3] "" Vector__XXX
 SG_ RedStopLampState : 4|2@1+ (1,0) [0|3] "" Vector__XXX
 SG_ AmberWarningLampStatus : 2|2@1+ (1,0) [0|3] "" Vector__XXX
 SG_ ProtectLampStatus : 0|2@1+ (1,0) [0|3] "" Vector__XXX
 SG_ FlashRedStopLamp : 12|2@1+ (1,0) [0|3] "" Vector__XXX
 SG_ FlashProtectLamp : 8|2@1+ (1,0) [0|3] "" Vector__XXX
 SG_ FlashMalfuncIndicatorLamp : 14|2@1+ (1,0) [0|3] "" Vector__XXX
 SG_ FlashAmberWarningLamp : 10|2@1+ (1,0) [0|3] "" Vector__XXX
 SG_ DTC5 : 144|32@1+ (1,0) [0|4294967295] "" Vector__XXX
 SG_ DTC4 : 112|32@1+ (1,0) [0|4294967295] "" Vector__XXX
 SG_ DTC3 : 80|32@1+ (1,0) [0|4294967295] "" Vector__XXX
 SG_ DTC2 : 48|32@1+ (1,0) [0|4294967295] "" Vector__XXX
 SG_ DTC1 : 16|32@1+ (1,0) [0|4294967295] "" Vector__XXX

BO_ 2564030206 DM19: 20 Vector__XXX
 SG_ CalibrationID4 : 128|32@1+ (1,0) [0|4294967295] "" Vector__XXX
 SG_ CalibrationID3 : 96|32@1+ (1,0) [0|4294967295] "" Vector__XXX
 SG_ CalibrationID2 : 64|32@1+ (1,0) [0|4294967295] "" Vector__XXX
 SG_ CalibrationID1 : 32|32@1+ (1,0) [0|4294967295] "" Vector__XXX
 SG_ CalibrationVerificationNumber : 0|32@1+ (1,0) [0|4294967295] "" Vector__XXX

BO_ 2564226814 DM17: 1 Vector__XXX
 SG_ BootLoadData : 0|8@1- (1,0) [0|0] "" Vector__XXX

BO_ 2564292350 DM16: 2 Vector__XXX
 SG_ RawBinaryData : 8|8@1- (1,0) [0|0] "" Vector__XXX
 SG_ NumberOfOccurance : 0|8@1+ (1,0) [0|0] "" Vector__XXX

BO_ 2564357886 DM15: 8 Vector__XXX
 SG_ NumberAllowed : 0|8@1+ (1,0) [0|2047] "" Vector__XXX
 SG_ Seed : 48|16@1+ (1,0) [0|65535] "" Vector__XXX
 SG_ EDCP_Extension : 40|8@1+ (1,0) [0|255] "" Vector__XXX
 SG_ ErrorIndicator : 16|24@1+ (1,0) [0|16777215] "" Vector__XXX
 SG_ Status : 9|3@1+ (1,0) [0|7] "" Vector__XXX
 SG_ NumberAllowedHigh : 13|3@1+ (1,0) [0|7] "" Vector__XXX

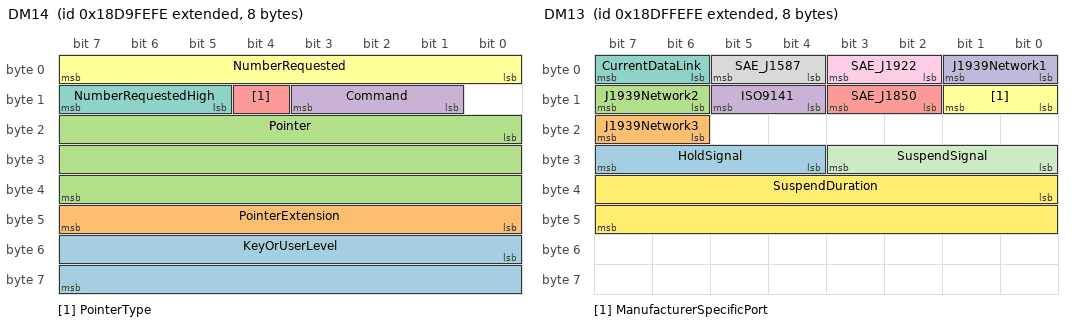
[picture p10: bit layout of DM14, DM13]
BO_ 2564423422 DM14: 8 Vector__XXX
 SG_ KeyOrUserLevel : 48|16@1+ (1,0) [0|65535] "" Vector__XXX
 SG_ PointerExtension : 40|8@1+ (1,0) [0|255] "" Vector__XXX
 SG_ Pointer : 16|24@1+ (1,0) [0|16777215] "" Vector__XXX
 SG_ Command : 9|3@1+ (1,0) [0|7] "" Vector__XXX
 SG_ PointerType : 12|1@1+ (1,0) [0|1] "" Vector__XXX
 SG_ NumberRequested : 0|8@1+ (1,0) [0|2047] "" Vector__XXX
 SG_ NumberRequestedHigh : 13|3@1+ (1,0) [0|7] "" Vector__XXX

BO_ 2564816638 DM13: 8 Vector__XXX
 SG_ HoldSignal : 28|4@1+ (1,0) [0|15] "" Vector__XXX
 SG_ J1939Network3 : 22|2@1+ (1,0) [0|3] "" Vector__XXX
 SG_ J1939Network2 : 14|2@1+ (1,0) [0|3] "" Vector__XXX
 SG_ ISO9141 : 12|2@1+ (1,0) [0|3] "" Vector__XXX
 SG_ SAE_J1850 : 10|2@1+ (1,0) [0|3] "" Vector__XXX
 SG_ ManufacturerSpecificPort : 8|2@1+ (1,0) [0|3] "" Vector__XXX
 SG_ CurrentDataLink : 6|2@1+ (1,0) [0|3] "" Vector__XXX
 SG_ SAE_J1587 : 4|2@1+ (1,0) [0|3] "" Vector__XXX
 SG_ SAE_J1922 : 2|2@1+ (1,0) [0|3] "" Vector__XXX
 SG_ J1939Network1 : 0|2@1+ (1,0) [0|3] "" Vector__XXX
 SG_ SuspendSignal : 24|4@1+ (1,0) [0|15] "" Vector__XXX
 SG_ SuspendDuration : 32|16@1+ (1,0) [0|64255] "sec" Vector__XXX

BO_ 2566837502 DM12: 22 Vector__XXX
 SG_ FlashRedStopLamp : 12|2@1+ (1,0) [0|3] "" Vector__XXX
 SG_ FlashProtectLamp : 8|2@1+ (1,0) [0|3] "" Vector__XXX
 SG_ MalfunctionIndicatorLampStatus : 6|2@1+ (1,0) [0|3] "" Vector__XXX
 SG_ RedStopLampState : 4|2@1+ (1,0) [0|3] "" Vector__XXX
 SG_ AmberWarningLampStatus : 2|2@1+ (1,0) [0|3] "" Vector__XXX
 SG_ ProtectLampStatus : 0|2@1+ (1,0) [0|3] "" Vector__XXX
 SG_ FlashMalfuncIndicatorLamp : 14|2@1+ (1,0) [0|3] "" Vector__XXX
 SG_ FlashAmberWarningLamp : 10|2@1+ (1,0) [0|3] "" Vector__XXX
 SG_ DTC5 : 144|32@1+ (1,0) [0|4294967295] "" Vector__XXX
 SG_ DTC4 : 112|32@1+ (1,0) [0|4294967295] "" Vector__XXX
 SG_ DTC3 : 80|32@1+ (1,0) [0|4294967295] "" Vector__XXX
 SG_ DTC2 : 48|32@1+ (1,0) [0|4294967295] "" Vector__XXX
 SG_ DTC1 : 16|32@1+ (1,0) [0|4294967295] "" Vector__XXX

BO_ 2566837246 DM11: 0 Vector__XXX

BO_ 2566836990 DM10: 8 Vector__XXX
 SG_ TestIdentifierSupported : 0|64@1+ (1,0) [1|1.844674407371E+019] "" Vector__XXX

BO_ 2566834942 DM1: 22 Vector__XXX
 SG_ FlashRedStopLamp : 12|2@1+ (1,0) [0|3] "" Vector__XXX
 SG_ FlashProtectLamp : 8|2@1+ (1,0) [0|3] "" Vector__XXX
 SG_ FlashMalfuncIndicatorLamp : 14|2@1+ (1,0) [0|3] "" Vector__XXX
 SG_ FlashAmberWarningLamp : 10|2@1+ (1,0) [0|3] "" Vector__XXX
 SG_ MalfunctionIndicatorLampStatus : 6|2@1+ (1,0) [0|3] "" Vector__XXX
 SG_ AmberWarningLampStatus : 2|2@1+ (1,0) [0|3] "" Vector__XXX
 SG_ RedStopLampState : 4|2@1+ (1,0) [0|3] "" Vector__XXX
 SG_ ProtectLampStatus : 0|2@1+ (1,0) [0|3] "" Vector__XXX
 SG_ DTC5 : 144|32@1+ (1,0) [0|4294967295] "" Vector__XXX
 SG_ DTC4 : 112|32@1+ (1,0) [0|4294967295] "" Vector__XXX
 SG_ DTC3 : 80|32@1+ (1,0) [0|4294967295] "" Vector__XXX
 SG_ DTC2 : 48|32@1+ (1,0) [0|4294967295] "" Vector__XXX
 SG_ DTC1 : 16|32@1+ (1,0) [0|4294967295] "" Vector__XXX

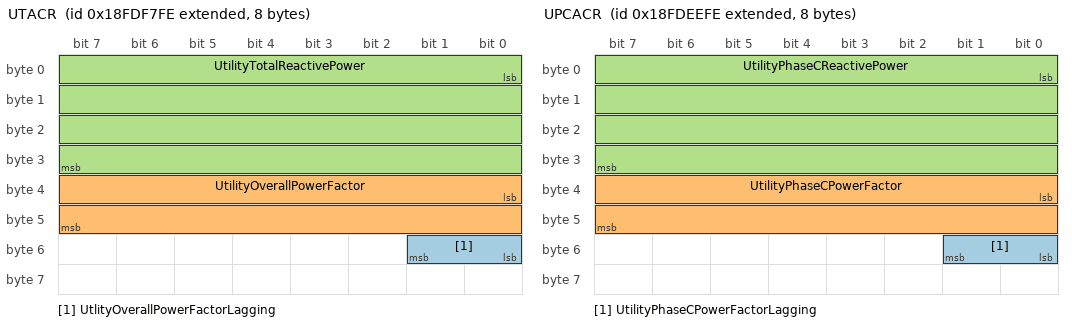
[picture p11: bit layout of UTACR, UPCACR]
BO_ 2566780926 UTACR: 8 Vector__XXX
 SG_ UtlityOverallPowerFactorLagging : 48|2@1+ (1,0) [0|3] "" Vector__XXX
 SG_ UtilityOverallPowerFactor : 32|16@1+ (1,-1) [-1|2.92181] "" Vector__XXX
 SG_ UtilityTotalReactivePower : 0|32@1+ (1,-2000000000) [-2000000000|2211081215] "VAr" Vector__XXX

BO_ 2566781182 UTACP: 8 Vector__XXX
 SG_ UtilityTotalApparentPower : 32|32@1+ (1,-2000000000) [-2000000000|2211081215] "VA" Vector__XXX
 SG_ UtilityTotalRealPower : 0|32@1+ (1,-2000000000) [-2000000000|2211081215] "W" Vector__XXX

BO_ 2566778366 UTACE: 8 Vector__XXX
 SG_ UtilityTotalKWHoursImport : 32|32@1+ (1,0) [0|4211081215] "kWh" Vector__XXX
 SG_ UtilityTotalKWHoursExport : 0|32@1+ (1,0) [0|4211081215] "kWh" Vector__XXX

BO_ 2566778622 UPCACR: 8 Vector__XXX
 SG_ UtilityPhaseCPowerFactorLagging : 48|2@1+ (1,0) [0|3] "" Vector__XXX
 SG_ UtilityPhaseCPowerFactor : 32|16@1+ (1,-1) [-1|2.92181] "" Vector__XXX
 SG_ UtilityPhaseCReactivePower : 0|32@1+ (1,-2000000000) [-2000000000|2211081215] "VAr" Vector__XXX

BO_ 2566778878 UPCACP: 8 Vector__XXX
 SG_ UtilityPhaseCApparentPower : 32|32@1+ (1,-2000000000) [-2000000000|2211081215] "VA" Vector__XXX
 SG_ UtilityPhaseCRealPower : 0|32@1+ (1,-2000000000) [-2000000000|2211081215] "W" Vector__XXX

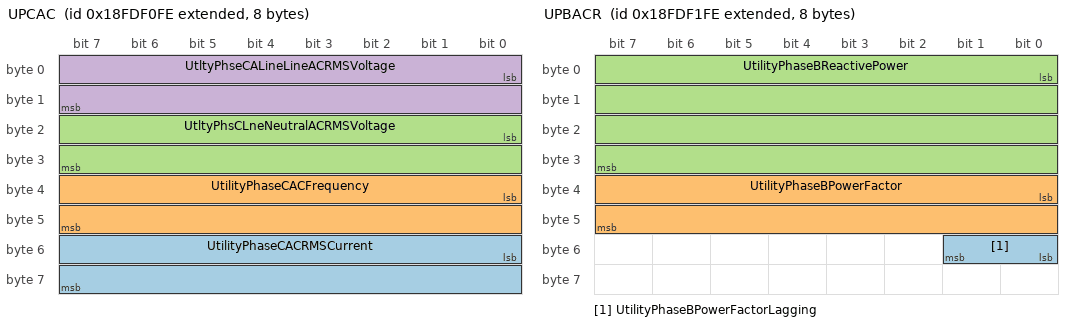
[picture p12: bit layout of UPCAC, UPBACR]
BO_ 2566779134 UPCAC: 8 Vector__XXX
 SG_ UtilityPhaseCACRMSCurrent : 48|16@1+ (1,0) [0|64255] "A" Vector__XXX
 SG_ UtilityPhaseCACFrequency : 32|16@1+ (1,0) [0|501.9921875] "Hz" Vector__XXX
 SG_ UtltyPhsCLneNeutralACRMSVoltage : 16|16@1+ (1,0) [0|64255] "V" Vector__XXX
 SG_ UtltyPhseCALineLineACRMSVoltage : 0|16@1+ (1,0) [0|64255] "V" Vector__XXX

BO_ 2566779390 UPBACR: 8 Vector__XXX
 SG_ UtilityPhaseBPowerFactorLagging : 48|2@1+ (1,0) [0|3] "" Vector__XXX
 SG_ UtilityPhaseBPowerFactor : 32|16@1+ (1,-1) [-1|2.92181] "" Vector__XXX
 SG_ UtilityPhaseBReactivePower : 0|32@1+ (1,-2000000000) [-2000000000|2211081215] "VAr" Vector__XXX

BO_ 2566779646 UPBACP: 8 Vector__XXX
 SG_ UtilityPhaseBApparentPower : 32|32@1+ (1,-2000000000) [-2000000000|2211081215] "VA" Vector__XXX
 SG_ UtilityPhaseBRealPower : 0|32@1+ (1,-2000000000) [-2000000000|2211081215] "W" Vector__XXX

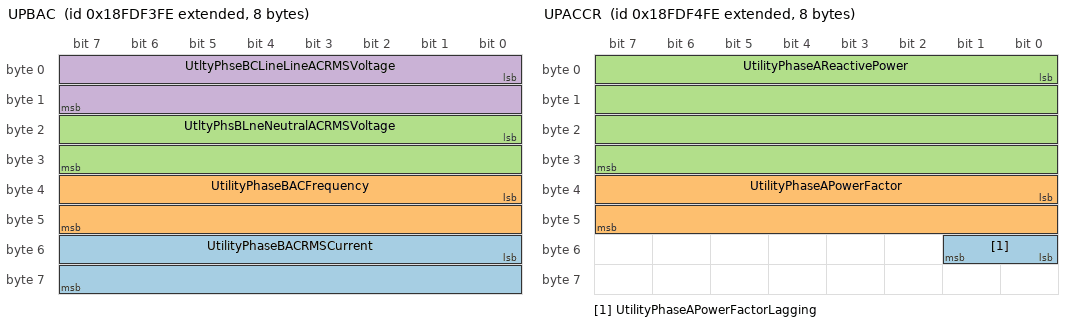
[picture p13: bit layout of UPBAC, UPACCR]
BO_ 2566779902 UPBAC: 8 Vector__XXX
 SG_ UtilityPhaseBACRMSCurrent : 48|16@1+ (1,0) [0|64255] "A" Vector__XXX
 SG_ UtilityPhaseBACFrequency : 32|16@1+ (1,0) [0|501.9921875] "Hz" Vector__XXX
 SG_ UtltyPhsBLneNeutralACRMSVoltage : 16|16@1+ (1,0) [0|64255] "V" Vector__XXX
 SG_ UtltyPhseBCLineLineACRMSVoltage : 0|16@1+ (1,0) [0|64255] "V" Vector__XXX

BO_ 2566780158 UPACCR: 8 Vector__XXX
 SG_ UtilityPhaseAPowerFactorLagging : 48|2@1+ (1,0) [0|3] "" Vector__XXX
 SG_ UtilityPhaseAPowerFactor : 32|16@1+ (1,-1) [-1|2.92181] "" Vector__XXX
 SG_ UtilityPhaseAReactivePower : 0|32@1+ (1,-2000000000) [-2000000000|2211081215] "VAr" Vector__XXX

BO_ 2566780414 UPAACP: 8 Vector__XXX
 SG_ UtilityPhaseAApparentPower : 32|32@1+ (1,-2000000000) [-2000000000|2211081215] "VA" Vector__XXX
 SG_ UtilityPhaseARealPower : 0|32@1+ (1,-2000000000) [-2000000000|2211081215] "W" Vector__XXX

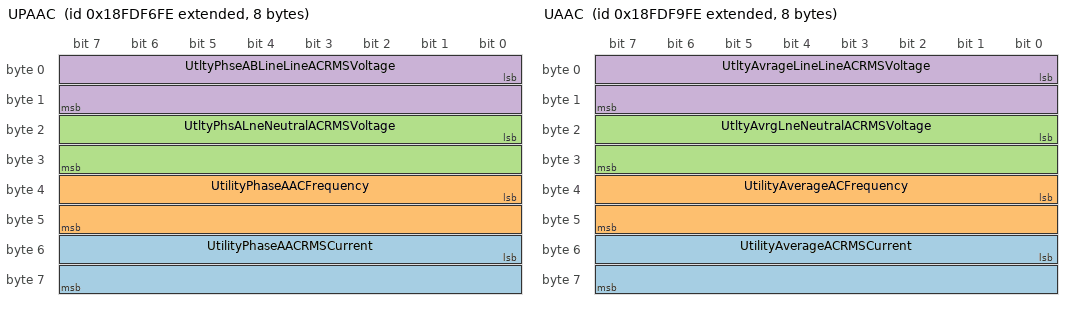
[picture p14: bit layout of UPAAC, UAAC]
BO_ 2566780670 UPAAC: 8 Vector__XXX
 SG_ UtilityPhaseAACRMSCurrent : 48|16@1+ (1,0) [0|64255] "A" Vector__XXX
 SG_ UtilityPhaseAACFrequency : 32|16@1+ (1,0) [0|501.9921875] "Hz" Vector__XXX
 SG_ UtltyPhsALneNeutralACRMSVoltage : 16|16@1+ (1,0) [0|64255] "V" Vector__XXX
 SG_ UtltyPhseABLineLineACRMSVoltage : 0|16@1+ (1,0) [0|64255] "V" Vector__XXX

BO_ 2566781438 UAAC: 8 Vector__XXX
 SG_ UtilityAverageACRMSCurrent : 48|16@1+ (1,0) [0|64255] "A" Vector__XXX
 SG_ UtilityAverageACFrequency : 32|16@1+ (1,0) [0|501.9921875] "Hz" Vector__XXX
 SG_ UtltyAvrgLneNeutralACRMSVoltage : 16|16@1+ (1,0) [0|64255] "V" Vector__XXX
 SG_ UtltyAvrageLineLineACRMSVoltage : 0|16@1+ (1,0) [0|64255] "V" Vector__XXX

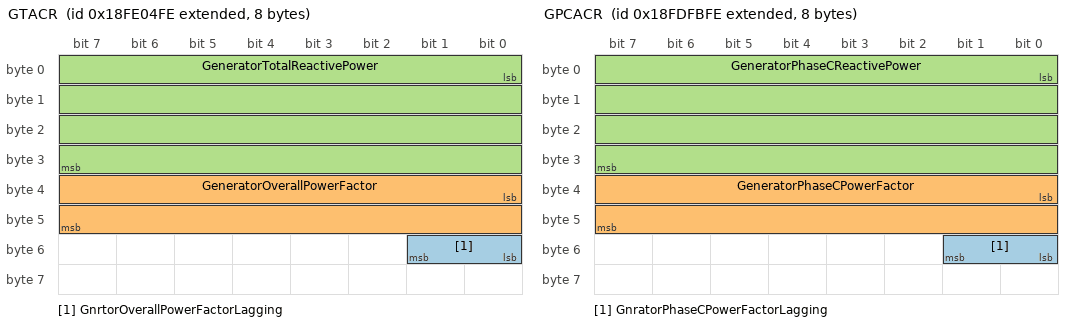
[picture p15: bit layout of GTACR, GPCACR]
BO_ 2566784254 GTACR: 8 Vector__XXX
 SG_ GnrtorOverallPowerFactorLagging : 48|2@1+ (1,0) [0|3] "" Vector__XXX
 SG_ GeneratorOverallPowerFactor : 32|16@1+ (1,-1) [-1|2.92181] "" Vector__XXX
 SG_ GeneratorTotalReactivePower : 0|32@1+ (1,-2000000000) [-2000000000|2211081215] "VAr" Vector__XXX

BO_ 2566784510 GTACP: 8 Vector__XXX
 SG_ GeneratorTotalApparentPower : 32|32@1+ (1,-2000000000) [-2000000000|2211081215] "VA" Vector__XXX
 SG_ GeneratorTotalRealPower : 0|32@1+ (1,-2000000000) [-2000000000|2211081215] "W" Vector__XXX

BO_ 2566781694 GTACE: 8 Vector__XXX
 SG_ GeneratorTotalKWHoursImport : 32|32@1+ (1,0) [0|4211081215] "kWh" Vector__XXX
 SG_ GeneratorTotalKWHoursExport : 0|32@1+ (1,0) [0|4211081215] "kWh" Vector__XXX

BO_ 2566781950 GPCACR: 8 Vector__XXX
 SG_ GnratorPhaseCPowerFactorLagging : 48|2@1+ (1,0) [0|3] "" Vector__XXX
 SG_ GeneratorPhaseCPowerFactor : 32|16@1+ (1,-1) [-1|2.92181] "" Vector__XXX
 SG_ GeneratorPhaseCReactivePower : 0|32@1+ (1,-2000000000) [-2000000000|2211081215] "VAr" Vector__XXX

BO_ 2566782206 GPCACP: 8 Vector__XXX
 SG_ GeneratorPhaseCApparentPower : 32|32@1+ (1,-2000000000) [-2000000000|2211081215] "VA" Vector__XXX
 SG_ GeneratorPhaseCRealPower : 0|32@1+ (1,-2000000000) [-2000000000|2211081215] "W" Vector__XXX

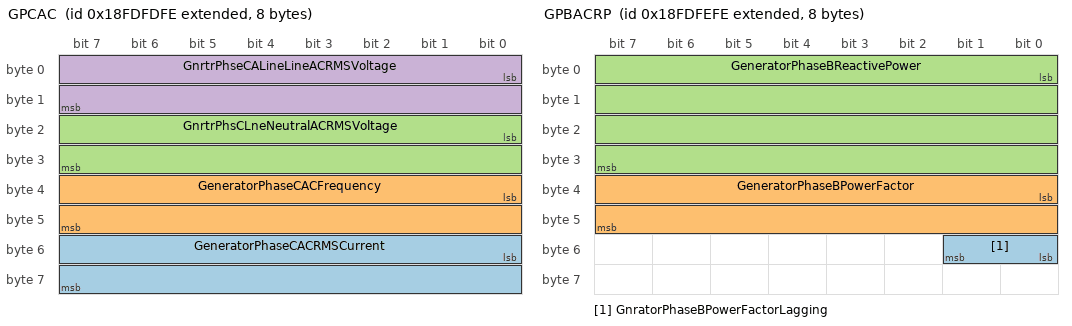
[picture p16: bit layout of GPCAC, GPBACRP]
BO_ 2566782462 GPCAC: 8 Vector__XXX
 SG_ GeneratorPhaseCACRMSCurrent : 48|16@1+ (1,0) [0|64255] "A" Vector__XXX
 SG_ GeneratorPhaseCACFrequency : 32|16@1+ (1,0) [0|501.9921875] "Hz" Vector__XXX
 SG_ GnrtrPhsCLneNeutralACRMSVoltage : 16|16@1+ (1,0) [0|64255] "V" Vector__XXX
 SG_ GnrtrPhseCALineLineACRMSVoltage : 0|16@1+ (1,0) [0|64255] "V" Vector__XXX

BO_ 2566782718 GPBACRP: 8 Vector__XXX
 SG_ GnratorPhaseBPowerFactorLagging : 48|2@1+ (1,0) [0|3] "" Vector__XXX
 SG_ GeneratorPhaseBPowerFactor : 32|16@1+ (1,-1) [-1|2.92181] "" Vector__XXX
 SG_ GeneratorPhaseBReactivePower : 0|32@1+ (1,-2000000000) [-2000000000|2211081215] "VAr" Vector__XXX

BO_ 2566782974 GPBACP: 8 Vector__XXX
 SG_ GeneratorPhaseBApparentPower : 32|32@1+ (1,-2000000000) [-2000000000|2211081215] "VA" Vector__XXX
 SG_ GeneratorPhaseBRealPower : 0|32@1+ (1,-2000000000) [-2000000000|2211081215] "W" Vector__XXX

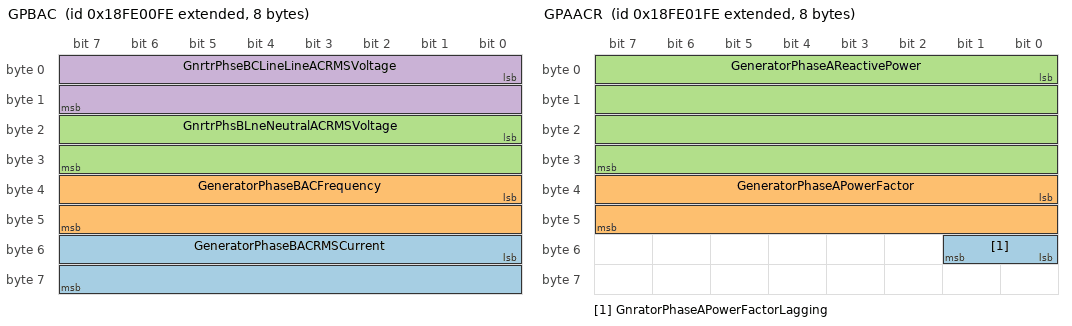
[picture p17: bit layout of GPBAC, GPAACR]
BO_ 2566783230 GPBAC: 8 Vector__XXX
 SG_ GeneratorPhaseBACRMSCurrent : 48|16@1+ (1,0) [0|64255] "A" Vector__XXX
 SG_ GeneratorPhaseBACFrequency : 32|16@1+ (1,0) [0|501.9921875] "Hz" Vector__XXX
 SG_ GnrtrPhsBLneNeutralACRMSVoltage : 16|16@1+ (1,0) [0|64255] "V" Vector__XXX
 SG_ GnrtrPhseBCLineLineACRMSVoltage : 0|16@1+ (1,0) [0|64255] "V" Vector__XXX

BO_ 2566783486 GPAACR: 8 Vector__XXX
 SG_ GnratorPhaseAPowerFactorLagging : 48|2@1+ (1,0) [0|3] "" Vector__XXX
 SG_ GeneratorPhaseAPowerFactor : 32|16@1+ (1,-1) [-1|2.92181] "" Vector__XXX
 SG_ GeneratorPhaseAReactivePower : 0|32@1+ (1,-2000000000) [-2000000000|2211081215] "VAr" Vector__XXX

BO_ 2566783742 GPAACP: 8 Vector__XXX
 SG_ GeneratorPhaseAApparentPower : 32|32@1+ (1,-2000000000) [-2000000000|2211081215] "VA" Vector__XXX
 SG_ GeneratorPhaseARealPower : 0|32@1+ (1,-2000000000) [-2000000000|2211081215] "W" Vector__XXX

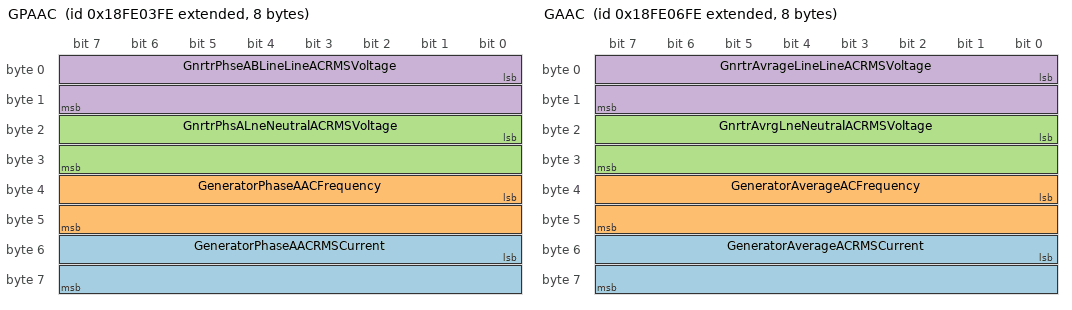
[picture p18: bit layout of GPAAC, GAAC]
BO_ 2566783998 GPAAC: 8 Vector__XXX
 SG_ GeneratorPhaseAACRMSCurrent : 48|16@1+ (1,0) [0|64255] "A" Vector__XXX
 SG_ GeneratorPhaseAACFrequency : 32|16@1+ (1,0) [0|501.9921875] "Hz" Vector__XXX
 SG_ GnrtrPhsALneNeutralACRMSVoltage : 16|16@1+ (1,0) [0|64255] "V" Vector__XXX
 SG_ GnrtrPhseABLineLineACRMSVoltage : 0|16@1+ (1,0) [0|64255] "V" Vector__XXX

BO_ 2566784766 GAAC: 8 Vector__XXX
 SG_ GeneratorAverageACRMSCurrent : 48|16@1+ (1,0) [0|64255] "A" Vector__XXX
 SG_ GeneratorAverageACFrequency : 32|16@1+ (1,0) [0|501.9921875] "Hz" Vector__XXX
 SG_ GnrtrAvrgLneNeutralACRMSVoltage : 16|16@1+ (1,0) [0|64255] "V" Vector__XXX
 SG_ GnrtrAvrageLineLineACRMSVoltage : 0|16@1+ (1,0) [0|64255] "V" Vector__XXX

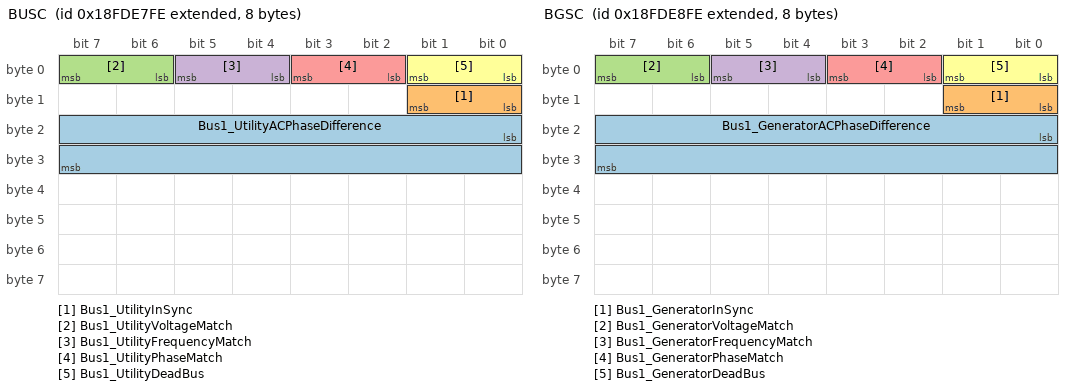
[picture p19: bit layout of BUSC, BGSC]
BO_ 2566776830 BUSC: 8 Vector__XXX
 SG_ Bus1_UtilityACPhaseDifference : 16|16@1+ (1,-200) [-200|301.99] "deg" Vector__XXX
 SG_ Bus1_UtilityInSync : 8|2@1+ (1,0) [0|3] "" Vector__XXX
 SG_ Bus1_UtilityVoltageMatch : 6|2@1+ (1,0) [0|3] "" Vector__XXX
 SG_ Bus1_UtilityFrequencyMatch : 4|2@1+ (1,0) [0|3] "" Vector__XXX
 SG_ Bus1_UtilityPhaseMatch : 2|2@1+ (1,0) [0|3] "" Vector__XXX
 SG_ Bus1_UtilityDeadBus : 0|2@1+ (1,0) [0|3] "" Vector__XXX

BO_ 2566777342 BPCAC: 8 Vector__XXX
 SG_ Bus1PhaseCACFrequency : 32|16@1+ (1,0) [0|501.9921875] "Hz" Vector__XXX
 SG_ Bs1PhseCLineNeutralACRMSVoltage : 16|16@1+ (1,0) [0|64255] "V" Vector__XXX
 SG_ Bus1PhaseCALineLineACRMSVoltage : 0|16@1+ (1,0) [0|64255] "V" Vector__XXX

BO_ 2566777598 BPBAC: 8 Vector__XXX
 SG_ Bus1PhaseBACFrequency : 32|16@1+ (1,0) [0|501.9921875] "Hz" Vector__XXX
 SG_ Bs1PhseBLineNeutralACRMSVoltage : 16|16@1+ (1,0) [0|64255] "V" Vector__XXX
 SG_ Bus1PhaseBCLineLineACRMSVoltage : 0|16@1+ (1,0) [0|64255] "V" Vector__XXX

BO_ 2566777854 BPAAC: 8 Vector__XXX
 SG_ Bus1PhaseAACFrequency : 32|16@1+ (1,0) [0|501.9921875] "Hz" Vector__XXX
 SG_ Bs1PhseALineNeutralACRMSVoltage : 16|16@1+ (1,0) [0|64255] "V" Vector__XXX
 SG_ Bus1PhaseABLineLineACRMSVoltage : 0|16@1+ (1,0) [0|64255] "V" Vector__XXX

BO_ 2566777086 BGSC: 8 Vector__XXX
 SG_ Bus1_GeneratorACPhaseDifference : 16|16@1+ (1,-200) [-200|301.99] "deg" Vector__XXX
 SG_ Bus1_GeneratorInSync : 8|2@1+ (1,0) [0|3] "" Vector__XXX
 SG_ Bus1_GeneratorVoltageMatch : 6|2@1+ (1,0) [0|3] "" Vector__XXX
 SG_ Bus1_GeneratorFrequencyMatch : 4|2@1+ (1,0) [0|3] "" Vector__XXX
 SG_ Bus1_GeneratorPhaseMatch : 2|2@1+ (1,0) [0|3] "" Vector__XXX
 SG_ Bus1_GeneratorDeadBus : 0|2@1+ (1,0) [0|3] "" Vector__XXX

BO_ 2566778110 BAAC: 8 Vector__XXX
 SG_ Bus1AverageACFrequency : 32|16@1+ (1,0) [0|501.9921875] "Hz" Vector__XXX
 SG_ Bs1AvrgeLineNeutralACRMSVoltage : 16|16@1+ (1,0) [0|64255] "V" Vector__XXX
 SG_ Bus1AverageLineLineACRMSVoltage : 0|16@1+ (1,0) [0|64255] "V" Vector__XXX

BO_ 2633895422 WSMSTR: 8 Vector__XXX
 SG_ NumberOfMembers : 0|8@1+ (1,0) [0|0] "" Vector__XXX

BO_ 2566838526 CA: 9 Vector__XXX
 SG_ AddressAssignment : 64|8@1+ (1,0) [0|255] "" Vector__XXX
 SG_ ArbitraryAddressCapable : 63|1@1+ (1,0) [0|1] "" Vector__XXX
 SG_ IndustryGroup M : 60|3@1+ (1,0) [0|7] "" Vector__XXX
 SG_ VehicleSystemInstance : 56|4@1+ (1,0) [0|15] "" Vector__XXX
 SG_ Function : 40|8@1+ (1,0) [0|255] "" Vector__XXX
 SG_ VehicleSystem m0 : 49|7@1+ (1,0) [0|127] "" Vector__XXX
 SG_ FunctionInstance : 35|5@1+ (1,0) [0|31] "" Vector__XXX
 SG_ ECUInstance : 32|3@1+ (1,0) [0|7] "" Vector__XXX
 SG_ ManufacturerCode : 21|11@1+ (1,0) [0|2047] "" Vector__XXX
 SG_ IdentityNumber : 0|21@1+ (1,0) [0|2097152] "" Vector__XXX
 SG_ VehicleSystem5 m5 : 49|7@1+ (1,0) [0|127] "" Vector__XXX
 SG_ VehicleSystem4 m4 : 49|7@1+ (1,0) [0|127] "" Vector__XXX
 SG_ VehicleSystem3 m3 : 49|7@1+ (1,0) [0|127] "" Vector__XXX
 SG_ VehicleSystem2 m2 : 49|7@1+ (1,0) [0|127] "" Vector__XXX
 SG_ VehicleSystem1 m1 : 49|7@1+ (1,0) [0|127] "" Vector__XXX

BO_ 2565799678 ACL: 8 Vector__XXX
 SG_ ArbitraryAddressCapable : 63|1@1+ (1,0) [0|1] "" Vector__XXX
 SG_ IndustryGroup M : 60|3@1+ (1,0) [0|7] "" Vector__XXX
 SG_ VehicleSystemInstance : 56|4@1+ (1,0) [0|15] "" Vector__XXX
 SG_ Function : 40|8@1+ (1,0) [0|255] "" Vector__XXX
 SG_ FunctionInstance : 35|5@1+ (1,0) [0|31] "" Vector__XXX
 SG_ ECUInstance : 32|3@1+ (1,0) [0|7] "" Vector__XXX
 SG_ ManufacturerCode : 21|11@1+ (1,0) [0|2047] "" Vector__XXX
 SG_ IdentityNumber : 0|21@1+ (1,0) [0|2097152] "" Vector__XXX
 SG_ VehicleSystem m0 : 49|7@1+ (1,0) [0|127] "" Vector__XXX
 SG_ VehicleSystem5 m5 : 49|7@1+ (1,0) [0|127] "" Vector__XXX
 SG_ VehicleSystem4 m4 : 49|7@1+ (1,0) [0|127] "" Vector__XXX
 SG_ VehicleSystem3 m3 : 49|7@1+ (1,0) [0|127] "" Vector__XXX
 SG_ VehicleSystem2 m2 : 49|7@1+ (1,0) [0|127] "" Vector__XXX
 SG_ VehicleSystem1 m1 : 49|7@1+ (1,0) [0|127] "" Vector__XXX

BO_ 2563440382 XFER: 8 Vector__XXX
 SG_ ShrtNameOfActualReportingDevice : 32|32@1+ (1,0) [0|0] "(2^32 - 1)" Vector__XXX
 SG_ LengthOfDataForTheReportedPGN : 24|8@1+ (1,0) [0|255] "" Vector__XXX
 SG_ PGNofRequstedInformation : 0|24@1+ (1,0) [0|16777215] "" Vector__XXX

BO_ 2632711934 TPDT: 8 Vector__XXX
 SG_ SequenceNumber : 0|8@1+ (1,0) [0|255] "" Vector__XXX

BO_ 2632777470 TPCM: 8 Vector__XXX
 SG_ TotalNumberOfPacketsEoMA m19 : 24|8@1+ (1,0) [0|255] "" Vector__XXX
 SG_ TotalMessageSizeEoMA m19 : 8|16@1+ (1,0) [0|64255] "counts" Vector__XXX
 SG_ TotalMessageSizeBAM m32 : 8|16@1+ (1,0) [0|64255] "counts" Vector__XXX
 SG_ TotalNumberOfPacketsBAM m32 : 24|8@1+ (1,0) [0|255] "" Vector__XXX
 SG_ ConnectionAbortReason m255 : 8|8@1+ (1,0) [0|255] "" Vector__XXX
 SG_ NextPacketNumberToBeSent m17 : 16|8@1+ (1,0) [0|255] "" Vector__XXX
 SG_ NumberOfPacketsThatCanBeSent m17 : 8|8@1+ (1,0) [0|255] "" Vector__XXX
 SG_ PGNumber : 40|24@1+ (1,0) [0|16777200] "" Vector__XXX
 SG_ MaximumNumberOfPackets m16 : 32|8@1+ (1,0) [0|255] "" Vector__XXX
 SG_ TotalNumberOfPackets m16 : 24|8@1+ (1,0) [0|255] "" Vector__XXX
 SG_ TotalMessageSize m16 : 8|16@1+ (1,0) [0|64255] "counts" Vector__XXX
 SG_ ControlByte M : 0|8@1+ (1,0) [0|255] "" Vector__XXX

BO_ 2563374846 RQST2: 8 Vector__XXX
 SG_ UseTransferMode : 24|2@1+ (1,0) [0|3] "" Vector__XXX
 SG_ ParameterGroupNumber : 0|24@1+ (1,0) [0|16777215] "" Vector__XXX

CM_ BO_ 2566758654 "Aftertreatment 2 Fuel Control 1";
CM_ SG_ 2566758654 Aftrtrtmnt2FlInjctor1HeaterCtrl "Heating level that the controller is commanding the aftertreatment 2 fuel injector 1 heater control to maintain.";
CM_ SG_ 2566758654 Aftertreatment2FuelPress1Ctrl "Position that the controller is commanding the aftertreatment 2 fuel pressure control to maintain.";
CM_ SG_ 2566758654 Aftertreatment2FuelPress1 "Pressure of the fuel for Aftertreatment 2.";
CM_ SG_ 2566758654 Aftrtratment2FuelEnableActuator "Indicates whether aftertreatment 2 fuel enable actuator is on or off";
CM_ SG_ 2566758654 Aftrtratment2RegenerationStatus "Indicates whether regeneration is active or inactive in aftertreatment 2.";
CM_ SG_ 2566758654 Aftertreatment2Ignt "Indicates whether aftertreatment 2 ignition circuit is energized by the ECM.";
CM_ SG_ 2566758654 Aftrtreatment2FuelDrainActuator "Indicates whether aftertreatment 2 fuel drain actuator is on or off";
CM_ SG_ 2566758654 Aftertreatment2FuelRate "Rate of fuel being delivered to aftertreatment 2 for regeneration";
CM_ BO_ 2566753278 "Aftertreatment 2 Gas Parameters";
CM_ SG_ 2566753278 DslPrticulateFilterOutletPress2 "This parameter indicates the diesel particulate filter outlet gage pressure 2 (bank 2).";
CM_ SG_ 2566753278 DslPrticulateFilterIntakePress2 "This parameter indicates the diesel particulate filter intake gage pressure 2 (bank 2).";
CM_ BO_ 2566756862 "Aftertreatment 2 Historical information";
CM_ SG_ 2566756862 Aftrtrtmnt2TtlNmbrOfActvRgnrtnMn "Total number of Aftertreatment device 2 active regeneration manual requests by the operator over the lifetime of the";
CM_ SG_ 2566756862 Aftrtrtmnt2TtlNmbrOfActvRgnrtnIn "Total number of Aftertreatment device 2 active regeneration inhibit requests by the operator over the lifetime of the";
CM_ SG_ 2566756862 Aftrtrtmnt2AvrgTmBtwnActvRgnrtns "Indicates the average time since last reset between active regenerations, that have not been forced to occur by manual";
CM_ SG_ 2566756862 Aftrtrtmnt2TtlNmbrOfPssvRgnrtns "Total number of passive regenerations by Aftertreatment device 2 over the lifetime of the device.";
CM_ SG_ 2566756862 Aftrtrtmnt2TtlPssvRgnrationTime "Total amount of time that Aftertreatment device 2 has been in passive regeneration over the lifetime of the device.";
CM_ SG_ 2566756862 Aftrtrtmnt2TtlNmbrOfActvRgnrtns "Total number of active regenerations by aftertreatment device 2 over the lifetime of the device.";
CM_ SG_ 2566756862 Aftrtreatment2TotalDisabledTime "Total amount of time that aftertreatment 2 regeneration has been manually disabled.";
CM_ SG_ 2566756862 Aftrtrtmnt2TtalRegenerationTime "Total amount of time that aftertreatment device 2 has been regenerating over the lifetime of the device.";
CM_ SG_ 2566756862 Aftertreatment2TotalFuelUsed "Total amount of fuel used by aftertreatment device 2 over the lifetime of the device.";
CM_ BO_ 2565869822 "Aftertreatment 2 Intake Gas 1";
CM_ SG_ 2565869822 Aftrtrtmnt2IntkOxygnSnsrPrlmnryF "Used to identify the applicable J1939-73 FMI detected in the aftertreatment intake oxygen sensor by the manufacturer's";
CM_ SG_ 2565869822 Aftrtrtmnt2IntkGsSnsrPwerStatus "Indicates that the power supplied to the aftertreatment intake gas sensor, either NOx or O2, is within the manufacturer's";
CM_ SG_ 2565869822 Aftrtrtmnt2IntkGsSnsrHtrPrlmnryF "Used to identify the applicable J1939-73 FMI detected in the heater of the intake exhaust gas sensor, either NOx or O2,";
CM_ SG_ 2565869822 Aftrtrtmnt2IntkNOxSnsrPrlmnryFMI "Used to identify the applicable J1939-73 FMI detected in the aftertreatment intake NOx sensor by the manufacturer's";
CM_ SG_ 2565869822 Aftrtrtmnt2IntkGsSnsrHeaterCtrl "Indicates the heater status in the warm-up process.";
CM_ SG_ 2565869822 Aftrtrtmnt2IntkWdRngO2RdngStble "Indicates that the %O2 reading of the aftertreatment intake gas sensor, either NOx or O2, is stable as determined by the";
CM_ SG_ 2565869822 Aftrtrtmnt2IntkNOxReadingStable "Indicates that the NOx reading of the aftertreatment intake NOx sensor is stable as determined by the manufacturer's";
CM_ SG_ 2565869822 Aftrtrtmnt2IntkeGasSensorAtTemp "Indicates that the heater element of the aftertreatment intake gas sensor, either NOx or O2, is within the manufacturer's";
CM_ SG_ 2565869822 Aftertreatment2IntakeO2 "The actual oxidation factor (%O2) of the gas within the exhaust stream.";
CM_ SG_ 2565869822 Aftertreatment2IntakeNOx "The amount of combined NO and NO2 in the exhaust entering the aftertreatment system measured by a NOx sensor at";
CM_ BO_ 2566763006 "Aftertreatment 2 Intake Gas 2";
CM_ SG_ 2566763006 Aftrtrtmnt2DslPrtcltFltrIntkGsTm "Used to identify the applicable J1939-73 FMI detected in the diesel particulate filter intake gas temperature sensor by the";
CM_ SG_ 2566763006 Aftrtrtmnt2ExhstGsTmp1PrlmnryFMI "Used to identify the applicable J1939-73 FMI detected in the exhaust gas temperature 1 sensor by the manufacturer's";
CM_ SG_ 2566763006 Aftertreatment2ExhaustGasTemp1 "The reading from the exhaust gas temperature sensor located farthest upstream in the aftertreatment system in exhaust bank 2.";
CM_ SG_ 2566763006 Aftrtrtmnt2DslPrtcltFltrInt_0000 "Temperature of engine combustion byproducts entering the diesel particulate filter in exhaust bank 2.";
CM_ BO_ 2566762494 "Aftertreatment 2 Intermediate Gas";
CM_ SG_ 2566762494 Aftrtrtmnt2DslPrtcltFltrIntrmdtG "Used to identify the applicable J1939-73 FMI detected in the diesel particulate filter intermediate gas temperature sensor";
CM_ SG_ 2566762494 Aftrtrtmnt2DslPrtcltFltrInt_0001 "Temperature of engine combustion byproducts at a mid-point in the diesel particulate filter in exhaust bank 2.";
CM_ SG_ 2566762494 Aftrtrtmnt2DslPrtcltFltrDltPrssP "Used to identify the applicable J1939-73 FMI detected in the diesel particulate filter differential pressure sensor by the";
CM_ SG_ 2566762494 Aftrtrtmnt2DslPrtcltFltrDffPrss "Exhaust differential pressure measured between the intake and exhaust of a diesel particulate filter in exhaust bank 2.";
CM_ SG_ 2566762494 Aftrtrtmnt2ExhstGsTmp2PrlmnryFMI "Used to identify the applicable J1939-73 FMI detected in the exhaust gas temperature 2 sensor by the manufacturer's";
CM_ SG_ 2566762494 Aftertreatment2ExhaustGasTemp2 "The reading from the exhaust gas temperature sensor located midstream of the other two temperature sensors in the";
CM_ BO_ 2565870078 "Aftertreatment 2 Outlet Gas 1";
CM_ SG_ 2565870078 Aftrtrtmnt2OtltOxygnSnsrPrlmnryF "Used to identify the applicable J1939-73 FMI detected in the aftertreatment outlet oxygen sensor by the manufacturer's";
CM_ SG_ 2565870078 Aftrtrtmnt2OtltGsSnsrPwerStatus "Indicates that the power supplied to the aftertreatment outlet gas sensor, either NOx or O2, is within the manufacturer's";
CM_ SG_ 2565870078 Aftrtrtmnt2OtltGsSnsrHtrPrlmnryF "Used to identify the applicable J1939-73 FMI detected in the heater of the outlet exhaust gas sensor, either NOx or O2, by";
CM_ SG_ 2565870078 Aftrtrtmnt2OtltNOxSnsrPrlmnryFMI "Used to identify the applicable J1939-73 FMI detected in the aftertreatment outlet NOx sensor by the manufacturer's";
CM_ SG_ 2565870078 Aftrtrtmnt2OtltGsSnsrHeaterCtrl "Indicates the heater status in the warm-up process.";
CM_ SG_ 2565870078 Aftrtrtmnt2OtltWdRngO2RdngStble "Indicates that the %O2 reading of the aftertreatment outlet gas sensor, either NOx or O2, is stable as determined by the";
CM_ SG_ 2565870078 Aftrtrtmnt2OtltNOxReadingStable "Indicates that the NOx reading of the aftertreatment outlet NOx sensor is stable as determined by the manufacturer's";
CM_ SG_ 2565870078 Aftrtrtmnt2OtletGasSensorAtTemp "Indicates that the heater element of the aftertreatment outlet gas sensor, either NOx or O2, is within the manufacturer's";
CM_ SG_ 2565870078 Aftertreatment2OutletO2 "The actual oxidation factor (%O2) of the gas within the exhaust stream.";
CM_ SG_ 2565870078 Aftertreatment2OutletNOx "The amount of combined NO and NO2 in the exhaust entering the aftertreatment system measured by a NOx sensor at";
CM_ BO_ 2566762750 "Aftertreatment 2 Outlet Gas 2";
CM_ SG_ 2566762750 Aftrtrtmnt2DslPrtcltFltrOtltGsTm "Temperature of engine combustion byproducts leaving the diesel particulate filter exhaust in exhaust bank 2.";
CM_ SG_ 2566762750 Aftrtrtmnt2DslPrtcltFltrExhstGsT "Used to identify the applicable J1939-73 FMI detected in the diesel particulate filter outlet gas temperature sensor by the";
CM_ SG_ 2566762750 Aftrtrtmnt2ExhstGsTmp3PrlmnryFMI "Used to identify the applicable J1939-73 FMI detected in the exhaust gas temperature 3 sensor by the manufacturer's";
CM_ SG_ 2566762750 Aftertreatment2ExhaustGasTemp3 "The reading from the exhaust gas temperature sensor located farthest downstream in the aftertreatment system in";
CM_ BO_ 2566748926 "Aftertreatment 2 Service";
CM_ SG_ 2566748926 DslPrtclteFilter2AshLoadPercent "Indicates the ash load percent of diesel particulate filter 2.";
CM_ SG_ 2566748926 DslPrtcltFltr2TmSncLstActvRgnrtn "Indicates the time since the last active regeneration event of diesel particulate filter 2.";
CM_ SG_ 2566748926 DslPrtcltFilter2SootLoadPercent "Indicates the soot load percent of diesel particulate filter 2.";
CM_ SG_ 2566748926 Aftrtrtmnt2DslPrtcltFltrStLdRgnr "This parameter indicates the value that will first cause DPF regeneration in aftertreatment 2.";
CM_ BO_ 2566748414 "Aftertreatment 2 Trip Information";
CM_ SG_ 2566748414 Aftrtrtmnt2TrpNmbrOfActvRgnrtnMn "Total number of aftertreatment device 2 active regeneration manual requests by the operator during the current trip";
CM_ SG_ 2566748414 Aftrtrtmnt2TrpNmbrOfActvRgnrtnIn "Total number of aftertreatment device 2 active regeneration inhibit requests by the operator during the current trip period.";
CM_ SG_ 2566748414 Aftrtrtmnt2TrpNmbrOfPssvRgnrtns "Total number of passive regenerations by aftertreatment device 2 during the current trip period.";
CM_ SG_ 2566748414 Aftrtrtmnt2TrpPssvRgnrationTime "Total amount of time that aftertreatment device 2 has been in passive regeneration during the current trip period.";
CM_ SG_ 2566748414 Aftrtrtmnt2TrpNmbrOfActvRgnrtns "Total number of active regenerations by aftertreatment device 2 during the current trip period.";
CM_ SG_ 2566748414 Aftertreatment2TripDisabledTime "Total amount of time that aftertreatment 2 regeneration has been manually disabled during the current trip period.";
CM_ SG_ 2566748414 Aftrtrtmnt2TrpActvRgnrationTime "Total amount of time that aftertreatment device 2 has been in active regeneration during the current trip period.";
CM_ SG_ 2566748414 Aftertreatment2TripFuelUsed "Total amount of fuel used by aftertreatment device 2 during the current trip period.";
CM_ BO_ 2365428478 "Engine Operating Information";
CM_ SG_ 2365428478 EngDerateRq "This parameter is a derate request made from the engine control system to an external system, where the engine is";
CM_ SG_ 2365428478 EngEmergencyShutdownIndication "A signal issued by the engine control system to a user or external system indicating that it is immediately shutting the engine";
CM_ SG_ 2365428478 EngCtrlledShutdownRq "A signal issued by the engine control system to a user or external system requesting for a controlled shutdown.";
CM_ SG_ 2365428478 EngCoolantCirculatingPumpCtrl "Control setting for an electrically actuated engine coolant circulating pump.";
CM_ SG_ 2365428478 EngBlock_CoolantPreheaterCtrl "Control setting for an electrically actuated engine block or coolant pre-heating device.";
CM_ SG_ 2365428478 EngElctrclSystmPwrCnsrvtionCtrl "Control setting for cutting power to various devices when the engine is not in use.";
CM_ SG_ 2365428478 EngOilPreheaterCtrl "Control setting for an electrically actuated oil pre-heating device.";
CM_ SG_ 2365428478 EngOilPrimingPumpCtrl "This control is used to activate a pump that lubricates the engine, particularly prior to initial engine startup.";
CM_ SG_ 2365428478 EngFuelShutoffValveLeakTestCtrl "Control setting for fuel shutoff valve proving system test.";
CM_ SG_ 2365428478 EngFuelShutoff2Ctrl "Control setting for fuel shutoff 2.";
CM_ SG_ 2365428478 EngFuelShutoff1Ctrl "Control setting for fuel shutoff 1.";
CM_ SG_ 2365428478 EngFuelShutoffVentCtrl "Control setting for a fuel shutoff vent.";
CM_ SG_ 2365428478 TmeRemainingInEngOperatingState "This parameter is used to indicate the time remaining in the current engine operating state, based on the state defined in";
CM_ SG_ 2365428478 FuelPumpPrimerCtrl "Parameter used to activate or deactivate a priming system on the fuel transfer system.";
CM_ SG_ 2365428478 EngOperatingState "This parameter is used to indicate the current state, or mode, of operation by the engine.";
CM_ BO_ 2566743806 "Engine Temperature 4";
CM_ SG_ 2566743806 EngExhstVlvActtionSystemOilTemp "The temperature of the oil in the hydraulic system that powers the engine exhaust valve actuation system";
CM_ SG_ 2566743806 EngExhstGsRcrcltn1MxrIntakeTemp "The temperature of the EGR gas entering the intake mixer, measured after the intake throttle when provided.";
CM_ SG_ 2566743806 EngCoolantThermostatOpening "The current position of the Thermostat used to regulate the temperature of the engine coolant.";
CM_ SG_ 2566743806 EngCoolantPumpOutletTemp "The actual value of engine coolant temperature at the coolant pump outlet";
CM_ SG_ 2566743806 EngCoolantTemp2 "Second temperature of liquid found in the engine cooling system.";
CM_ BO_ 2499635454 "Gross Combination Vehicle Weight";
CM_ SG_ 2499635454 NetVehicleWeightChange "Identifies the net vehicle weight change from the time of last vehicle net weight zeroing.";
CM_ SG_ 2499635454 GrossCombinationWeight "Total weight of the truck and all the trailers with on-board scales.";
CM_ BO_ 2550660862 "General Purpose Valve Pressure";
CM_ SG_ 2550660862 ValveAssemblySupplyPress "Pressure of the hydraulic supply port to a valve assembly.";
CM_ SG_ 2550660862 ValveAssemblyLoadSensePress "The maximum pressure of a valve assembly's current collective load sense pressures where a valve assembly can";
CM_ SG_ 2550660862 ValvePilotPress "Pressure of a valve's pilot supply port.";
CM_ SG_ 2550660862 ValveLoadSensePress "The maximum of the currently measured pressures of a valve's work port A and work port B.";
CM_ BO_ 2566805758 "Air Suspension Control 4";
CM_ SG_ 2566805758 BellowPressRearAxleRight "Information of the pressure of the air suspension bellow at the right side of the rear axle";
CM_ SG_ 2566805758 BellowPressRearAxleLeft "Information of the pressure of the air suspension bellow at the left side of the rear axle";
CM_ SG_ 2566805758 BellowPressFrontAxleRight "Information of the pressure of the air suspension bellow at the right side of the front axle";
CM_ SG_ 2566805758 BellowPressFrontAxleLeft "Information of the pressure of the air suspension bellow at the left side of the front axle";
CM_ BO_ 2566806014 "Air Suspension Control 3";
CM_ SG_ 2566806014 RelativeLevelRearAxleRight "Information of the height at the left side of the rear axle referred to normal level 1.";
CM_ SG_ 2566806014 RelativeLevelRearAxleLeft "Information of the height at the left side of the rear axle referred to normal level 1.";
CM_ SG_ 2566806014 RelativeLevelFrontAxleRight "Information of the height at the right side of the front axle referred to normal level 1.";
CM_ SG_ 2566806014 RelativeLevelFrontAxleLeft "Information of the height at the left side of the front axle referred to normal level 1.";
CM_ BO_ 2362638078 "Air Suspension Control 2";
CM_ SG_ 2362638078 SpeedDependentLevelCtrlRq "This parameter activates speed dependent level control in suspension system.";
CM_ SG_ 2362638078 PrhbtAutomaticAirSuspensionCtrl "[Ed note - description needs to be reviewed and adjusted as necessary]";
CM_ SG_ 2362638078 MemoryLevelRq "Signal which indicates that the air suspension control requests a memory level or a memory level shall be stored.";
CM_ SG_ 2362638078 AllowLevelCtrlDuringBrakingCmd "This parameter overides the inhibit of level control during braking.";
CM_ SG_ 2362638078 ProhibitAirSuspensionCtrl "This parameter is an external request to the air suspension control system to prohibit all air suspension control.";
CM_ SG_ 2362638078 KneelingCmdRearAxle "Command signal to activate the kneeling functionality at the rear axle of the vehicle.";
CM_ SG_ 2362638078 KneelingCmdFrontAxle "Command signal to activate the kneeling functionality at the front axle of the vehicle";
CM_ SG_ 2362638078 DamperStiffnessRqLift_TagAxle "Demand value for the shock absorber control at the lift or tag axle";
CM_ SG_ 2362638078 DamperStiffnessRqRearAxle "Demand value for the shock absorber control at the rear axle.";
CM_ SG_ 2362638078 DamperStiffnessRqFrontAxle "Demand value for the shock absorber control at the front axle.";
CM_ SG_ 2362638078 LevelCtrlModeRq "Command signal to activate a level control mode";
CM_ SG_ 2362638078 NominalLevelRqRearAxle "Command signal to activate a level of the rear axle programmed and/or memorized in the ECU.";
CM_ SG_ 2362638078 NominalLevelRqFrontAxle "Command signal to activate a level of the front axle programmed and/or memorized in the ECU For explanations of";
CM_ SG_ 2362638078 KneelingCtrlModeRq "Command signal to select the kneeling functionality";
CM_ SG_ 2362638078 KneelingRqRightSide "Command signal to activate the kneeling functionality on the right side of the vehicle";
CM_ SG_ 2362638078 KneelingRqLeftSide "Command signal to activate the kneeling functionality on the left side of the vehicle";
CM_ SG_ 2362638078 AutomaticTractionHelp "This signal enables the traction help (load transfer) in case of an active ASR function";
CM_ SG_ 2362638078 LiftAxle2PosCmd "Signal to command the position / load condition of lift / tag axle #2.";
CM_ SG_ 2362638078 LiftAxle1PosCmd "Signal to command the position/load condition of lift/tag axle #1.";
CM_ BO_ 2365479678 "Air Suspension Control 1";
CM_ SG_ 2365479678 SpeedDependantLevelCtrlStatus "This parameter indicates if the function Speed Dependant Level Control is active.";
CM_ SG_ 2365479678 MemoryLevel "Signal which indicates that the air suspension control has memory levels selected or stored.";
CM_ SG_ 2365479678 AllwLvelCtrlDuringBrakingStatus "This parameter indicates if the function Allow Level Control During Braking is active.";
CM_ SG_ 2365479678 SspensionCtrlRefusalInformation "Signal which indicates that the air suspension control cannot perform a request due to the operating conditions.";
CM_ SG_ 2365479678 SuspensionRemoteCtrl2 "Signal which indicates that the suspension system is controlled by remote control #2.";
CM_ SG_ 2365479678 SuspensionRemoteCtrl1 "Signal which indicates that the suspension system is controlled by remote control #1.";
CM_ SG_ 2365479678 RearAxleInBumperRange "Signal which indicates that the vehicle height at the rear axle (SPNs 1723 and 1724) is within the bumper range.";
CM_ SG_ 2365479678 FrontAxleInBumperRange "Signal which indicates that the vehicle height at the front axle (SPNs 1721 and 1722) is within the bumper range.";
CM_ SG_ 2365479678 DoorRelease "Signal which indicates that the doors may be opened.";
CM_ SG_ 2365479678 VehicleMotionInhibit "Signal which indicates whether vehicle motion is inhibited.";
CM_ SG_ 2365479678 SecurityDevice "The signal which indicates the status of the security device.";
CM_ SG_ 2365479678 LevelCtrlMode "Signal which indicates the actual control mode of the air suspension system";
CM_ SG_ 2365479678 KneelingInformation "Signal which indicates the actual level change in case of kneeling function";
CM_ SG_ 2365479678 LiftingCtrlModeRearAxle "Signal which indicates the actual lifting level change at the rear axle";
CM_ SG_ 2365479678 LiftingCtrlModeFrontAxle "Signal which indicates the actual lifting level change at the front axle";
CM_ SG_ 2365479678 LoweringCtrlModeRearAxle "Signal which indicates the actual lowering level change at the rear axle";
CM_ SG_ 2365479678 LoweringCtrlModeFrontAxle "Signal which indicates the actual lowering level change at the front axle";
CM_ SG_ 2365479678 AboveNominalLevelRearAxle "Signal which indicates whether the actual height of the rear axle is above the nominal (desired) level of the rear axle.";
CM_ SG_ 2365479678 AboveNominalLevelFrontAxle "Signal which indicates whether the actual height of the front axle is above the nominal (desired) level of the front axle.";
CM_ SG_ 2365479678 BelowNominalLevelRearAxle "Signal which indicates whether the actual height of the rear axle is below the nominal (desired) level for the rear axle.";
CM_ SG_ 2365479678 BelowNominalLevelFrontAxle "Signal which indicates whether the actual height of the front axle is below the nominal (desired) level for the front axle.";
CM_ SG_ 2365479678 NominalLevelRearAxle "Signal which indicates the nominal (desired) height of the rear axle to be controlled by the suspension system.";
CM_ SG_ 2365479678 NominalLevelFrontAxle "Signal which indicates the nominal (desired) height of the front axle to be controlled by the suspension system.";
CM_ SG_ 2365479678 LiftAxle2Pos "Signal which indicates the position / load condition of lift axle / tag axle #2.";
CM_ SG_ 2365479678 LiftAxle1Pos "Signal which indicates the position / load condition of lift axle / tag axle #1.";
CM_ BO_ 2566837758 "Alternator Information";
CM_ SG_ 2566837758 Alt4Status "Alternator 4 operating status.";
CM_ SG_ 2566837758 Alt3Status "Alternator 3 operating status.";
CM_ SG_ 2566837758 Alt2Status "Alternator 2 operating status.";
CM_ SG_ 2566837758 Alt1Status "Alternator 1 operating status.";
CM_ SG_ 2566837758 AltSpeed "Actual rotation speed of the alternator.";
CM_ BO_ 2633922558 "Auxiliary Pressures";
CM_ SG_ 2633922558 AuxAbsPressReading "Identifies the current absolute pressure (relative to 0 pressure) that is configured uniquely per application.";
CM_ SG_ 2633922558 AuxGagePressReading1 "Identifies the current gage pressure (relative to atmosphere) that is configured uniquely per application.";
CM_ SG_ 2633922558 AuxVacuumPressReading "Identifies the current vacuum pressure (relative to atmosphere) that is configured uniquely per application.";
CM_ BO_ 2566775038 "Ambient Conditions 2";
CM_ SG_ 2566775038 SpecificHumidity "Specific humidity of the ambient intake air.";
CM_ SG_ 2566775038 SolarSensorMax "This is the maximum value which can be reported by the sensor for the solar intensity.";
CM_ SG_ 2566775038 SolarIntensityPercent "This is the solar radiation (power density) falling on the vehicle in percent of the maximum sensor value (SPN 2611).";
CM_ BO_ 2566836478 "Test results for non-continously monitored systems.";
CM_ SG_ 2566836478 TestLimitMinimum "The threshold which the test value must be above to pass the test.";
CM_ SG_ 2566836478 TestLimitMaximum "The threshold which the test value must be below to pass the test.";
CM_ SG_ 2566836478 TestValue "The test value collected during the test.";
CM_ SG_ 2566836478 TestType "Identifies the non-continously monitored component identifier that was tested.";
CM_ SG_ 2566836478 TestIdentifier "Designates the test to be run.";
CM_ BO_ 2565078782 "Command non-continously monitored test";
CM_ SG_ 2565078782 SPN1High "SPN #1 (Conversion Version 4)";
CM_ SG_ 2565078782 SPN1 "SPN #1 (Conversion Version 4)";
CM_ SG_ 2565078782 TestIdentifier "Designates the test to be run.";
CM_ SG_ 2565078782 FailureModeIdentifier1 "The FMI defines the type of failure detected in the subsystem identified by an SPN.";
CM_ BO_ 2566836222 "Pending DTCs";
CM_ SG_ 2566836222 FlashRedStopLamp "This parameter provides the capability to flash the RSL (SPN 3039).";
CM_ SG_ 2566836222 FlashProtectLamp "This parameter provides the capability to flash the engine protect lamp (SPN 3041).";
CM_ SG_ 2566836222 FlashMalfuncIndicatorLamp "This parameter provides the capability to flash the MIL (SPN 3038).";
CM_ SG_ 2566836222 FlashAmberWarningLamp "This parameter provides the capability to flash the AWL (SPN 3040). ";
CM_ SG_ 2566836222 MalfunctionIndicatorLampStatus "A lamp used to relay only emissions-related trouble code information.";
CM_ SG_ 2566836222 RedStopLampState "This lamp is uesed to relay trouble code information that is of a severe enought condition that it warrants stopping the vehicle.";
CM_ SG_ 2566836222 AmberWarningLampStatus "This lamp is used to relay trouble code information that is reporting a problem with the vehicle system but the vehicle need
not be immediately stopped.";
CM_ SG_ 2566836222 ProtectLampStatus "This lamp is used to relay trouble code informatio that is reporting a problem with a vehicle system that is most
probably not electronic subsystem related.";
CM_ SG_ 2566836222 DTC5 "Diagnostic Trouble Code";
CM_ SG_ 2566836222 DTC4 "Diagnostic Trouble Code";
CM_ SG_ 2566836222 DTC3 "Diagnostic Trouble Code";
CM_ SG_ 2566836222 DTC2 "Diagnostic Trouble Code";
CM_ SG_ 2566836222 DTC1 "Diagnostic Trouble Code";
CM_ BO_ 2566835966 "Diagnostic readiness 1";
CM_ SG_ 2566835966 OBDCompliance "Identifies the OBD compliance capabilityof the responding controller.";
CM_ SG_ 2566835966 PreviouslyActiveTroubleCodes "Identifies the number of previously active trouble codes that are present in a specific controller.";
CM_ SG_ 2566835966 ActiveTroubleCodes "Identifies the number of active trouble codes that are present in a specific controller.";
CM_ BO_ 2566835710 "Freeze frame parameters";
CM_ SG_ 2566835710 EngIntakeManifold1Press "The gage pressure measurement of the air intake manifold.";
CM_ SG_ 2566835710 FreezeFrameLength "The freeze frame length shall be equal to the number of bytes in the required parameters plus the number of bytes in the
manufacturer specific parameters.";
CM_ SG_ 2566835710 EngSpeed "Actual engine speed which is calculated over a minimum crankshaft angle of 720 degrees divided by the number of cylinders.";
CM_ SG_ 2566835710 EngTorqueMode "State signal which indicates which engine torque mode is currently generating, limiting, or controlling the torque.";
CM_ SG_ 2566835710 WheelBasedVehicleSpeed "Speed of the vehicle as calculated from wheel or tailshaft speed.";
CM_ SG_ 2566835710 EngPercentLoadAtCurrentSpeed "The ratio of actual engine percent torque (indicated) to maximum indicated torque available at the current engine speed,";
CM_ SG_ 2566835710 DTC1 "Diagnostic Trouble Code";
CM_ BO_ 2566835454 "Diagnostic data clear/reset of previously active DTCs.";
CM_ BO_ 2566764542 "Expanded freeze frame.";
CM_ SG_ 2566764542 ExpandedFreezeFrameLength "The freeze frame length shall be equal to the number of bytes in the required parameters plus the number of bytes in the
manufacturer specific parameters.";
CM_ SG_ 2566764542 DTC1 "Diagnostic Trouble Code";
CM_ BO_ 2566764286 "SPN Support. This message is used to identify those SPNs supported by the product for freeze frames and data stream messages.";
CM_ SG_ 2566764286 SPNSupported1High "This parameter defines the SPN(s) that is/are supported for the freeze frame and/or data stream information.";
CM_ SG_ 2566764286 SPNSupportTypeSTR3 "This parameter defines whether the applicable parameter (that is the SPN) is supported in the freeze frame, the data stream or both the freeze frame and data stream.";
CM_ SG_ 2566764286 SPNSupportTypeSTR2 "This parameter defines whether the applicable parameter (that is the SPN) is supported in the freeze frame, the data stream or both the freeze frame and data stream.";
CM_ SG_ 2566764286 SPNSupportTypeEFF3 "This parameter defines whether the applicable parameter (that is the SPN) is supported in the freeze frame, the data stream or both the freeze frame and data stream.";
CM_ SG_ 2566764286 SPNSupportTypeEFF2 "This parameter defines whether the applicable parameter (that is the SPN) is supported in the freeze frame, the data stream or both the freeze frame and data stream.";
CM_ SG_ 2566764286 SPNSupportTypeDS3 "This parameter defines whether the applicable parameter (that is the SPN) is supported in the freeze frame, the data stream or both the freeze frame and data stream.";
CM_ SG_ 2566764286 SPNSupportTypeDS2 "This parameter defines whether the applicable parameter (that is the SPN) is supported in the freeze frame, the data stream or both the freeze frame and data stream.";
CM_ SG_ 2566764286 SPNSupported3High "This parameter defines the SPN(s) that is/are supported for the freeze frame and/or data stream information.";
CM_ SG_ 2566764286 SPNSupported2High "This parameter defines the SPN(s) that is/are supported for the freeze frame and/or data stream information.";
CM_ SG_ 2566764286 SPNSupported3 "This parameter defines the SPN(s) that is/are supported for the freeze frame and/or data stream information.";
CM_ SG_ 2566764286 SPNSupported2 "This parameter defines the SPN(s) that is/are supported for the freeze frame and/or data stream information.";
CM_ SG_ 2566764286 SPNDataLength3 "The number of data bytes associated with the SPN in the Freeze Frame.";
CM_ SG_ 2566764286 SPNSupportTypeSTR1 "This parameter defines whether the applicable parameter (that is the SPN) is supported in the freeze frame, the data stream or both the freeze frame and data stream.";
CM_ SG_ 2566764286 SPNSupportTypeDS1 "This parameter defines whether the applicable parameter (that is the SPN) is supported in the freeze frame, the data stream or both the freeze frame and data stream.";
CM_ SG_ 2566764286 SPNSupportTypeEFF1 "This parameter defines whether the applicable parameter (that is the SPN) is supported in the freeze frame, the data stream or both the freeze frame and data stream.";
CM_ SG_ 2566764286 SPNDataLength2 "The number of data bytes associated with the SPN in the Freeze Frame.";
CM_ SG_ 2566764286 SPNDataLength1 "The number of data bytes associated with the SPN in the Freeze Frame.";
CM_ SG_ 2566764286 SPNSupported1 "This parameter defines the SPN(s) that is/are supported for the freeze frame and/or data stream information.";
CM_ BO_ 2566764030 "Previously active emission related faults.";
CM_ SG_ 2566764030 FlashRedStopLamp "This parameter provides the capability to flash the RSL (SPN 3039).";
CM_ SG_ 2566764030 FlashProtectLamp "This parameter provides the capability to flash the engine protect lamp (SPN 3041).";
CM_ SG_ 2566764030 FlashMalfuncIndicatorLamp "This parameter provides the capability to flash the MIL (SPN 3038).";
CM_ SG_ 2566764030 FlashAmberWarningLamp "This parameter provides the capability to flash the AWL (SPN 3040). ";
CM_ SG_ 2566764030 MalfunctionIndicatorLampStatus "A lamp used to relay only emissions-related trouble code information.";
CM_ SG_ 2566764030 RedStopLampState "This lamp is uesed to relay trouble code information that is of a severe enought condition that it warrants stopping the vehicle.";
CM_ SG_ 2566764030 AmberWarningLampStatus "This lamp is used to relay trouble code information that is reporting a problem with the vehicle system but the vehicle need
not be immediately stopped.";
CM_ SG_ 2566764030 ProtectLampStatus "This lamp is used to relay trouble code informatio that is reporting a problem with a vehicle system that is most
probably not electronic subsystem related.";
CM_ SG_ 2566764030 DTC5 "Diagnostic Trouble Code";
CM_ SG_ 2566764030 DTC4 "Diagnostic Trouble Code";
CM_ SG_ 2566764030 DTC3 "Diagnostic Trouble Code";
CM_ SG_ 2566764030 DTC2 "Diagnostic Trouble Code";
CM_ SG_ 2566764030 DTC1 "Diagnostic Trouble Code";
CM_ BO_ 2562981630 "Individual Clear/Reset of active and previously active DTC.";
CM_ SG_ 2562981630 SPN1 "SPN #1 (Conversion Version 4)";
CM_ SG_ 2562981630 SPN1High "SPN #1 (Conversion Version 4)";
CM_ SG_ 2562981630 FailureModeIdentifier1 "The FMI defines the type of failure detected in the subsystem identified by an SPN.";
CM_ BO_ 2562850558 "Diagnostic readiness 2";
CM_ SG_ 2562850558 TimeSinceDTCsCleared "Time accumulated since DTCs were cleared (via an external test equipment or possibly, a battery disconnect) (SPN=?).";
CM_ SG_ 2562850558 MinutesRunByEngineMILActivated "Accumulated count (in minutes) while the MIL is activated (on) (SPN=?).";
CM_ SG_ 2562850558 DistanceSinceDTCsCleared "Distance accumulated since DTCs were cleared (SPN=?).";
CM_ SG_ 2562850558 DistanceWhileMILisActivated "The kilometers accumulated while the MIL is activated (SPN 3060).";
CM_ BO_ 2562916094 "Monitor Performance Ratio";
CM_ SG_ 2562916094 ApplSysMonitorDenominator "The number of times a vehicle has been operated that constitutes a driving cycle where this Applicable System Monitor could be operated per regulatory requirements (SPN 3068).";
CM_ SG_ 2562916094 ApplSysMonitorNumerator "The number of times a vehicle has been operated such that all conditions necessary for the Applicable System Monitor to detect a malfunction have been encountered (SPN 3067).";
CM_ SG_ 2562916094 SPNofApplSysMonitor "Contain the SPN of the system monitor for which Monitor ratio is being reported (SPN 3066).";
CM_ SG_ 2562916094 OBDMonitoringCondEncountered "Displays the number of times that the vehicle has been operated in the specified OBD monitoring conditions (SPN 3049).";
CM_ SG_ 2562916094 IgnitionCycleCounter "A single counter that defines the number of ignition cycles (SPN 3048).";
CM_ BO_ 2566835198 "Previously active diagnostic trouble codes";
CM_ SG_ 2566835198 MalfunctionIndicatorLampStatus "A lamp used to relay only emissions-related trouble code information.";
CM_ SG_ 2566835198 RedStopLampState "This lamp is uesed to relay trouble code information that is of a severe enought condition that it warrants stopping the vehicle.";
CM_ SG_ 2566835198 AmberWarningLampStatus "This lamp is used to relay trouble code information that is reporting a problem with the vehicle system but the vehicle need
not be immediately stopped.";
CM_ SG_ 2566835198 ProtectLampStatus "This lamp is used to relay trouble code informatio that is reporting a problem with a vehicle system that is most
probably not electronic subsystem related.";
CM_ SG_ 2566835198 FlashRedStopLamp "This parameter provides the capability to flash the RSL (SPN 3039).";
CM_ SG_ 2566835198 FlashProtectLamp "This parameter provides the capability to flash the engine protect lamp (SPN 3041).";
CM_ SG_ 2566835198 FlashMalfuncIndicatorLamp "This parameter provides the capability to flash the MIL (SPN 3038).";
CM_ SG_ 2566835198 FlashAmberWarningLamp "This parameter provides the capability to flash the AWL (SPN 3040). ";
CM_ SG_ 2566835198 DTC5 "Diagnostic Trouble Code";
CM_ SG_ 2566835198 DTC4 "Diagnostic Trouble Code";
CM_ SG_ 2566835198 DTC3 "Diagnostic Trouble Code";
CM_ SG_ 2566835198 DTC2 "Diagnostic Trouble Code";
CM_ SG_ 2566835198 DTC1 "Diagnostic Trouble Code";
CM_ BO_ 2564030206 "Calibration Information";
CM_ BO_ 2564226814 "Boot Load Data";
CM_ BO_ 2564292350 "Binary Data Transfer";
CM_ SG_ 2564292350 NumberOfOccurance "Number of occurance of raw binary data";
CM_ BO_ 2564357886 "Memory Access Response";
CM_ SG_ 2564357886 ErrorIndicator "Error Indicator/EDC Parameter";
CM_ BO_ 2564423422 "Memory Access Request";
CM_ SG_ 2564423422 KeyOrUserLevel "Key/User Level";
CM_ SG_ 2564423422 NumberRequested "Length/Number Requested";
CM_ SG_ 2564423422 NumberRequestedHigh "Length/Number Requested";
CM_ BO_ 2564816638 "Stop start broadcast";
CM_ SG_ 2564816638 HoldSignal "Indicator to all nodes that the communication ports that have been acted upon by the 'Stop start broadcast'
PGN are remaining in the modified state.";
CM_ SG_ 2564816638 J1939Network3 "Identifies the action to be performed on the SAE J1939 Network #3.";
CM_ SG_ 2564816638 J1939Network2 "Identifies the action to be performed on the SAE J1939 Network #2.";
CM_ SG_ 2564816638 ISO9141 "Identifies the action to be performed on the ISO9141 communications port.";
CM_ SG_ 2564816638 SAE_J1850 "Identifies the action to be performed on the SAE J1850 communications port.";
CM_ SG_ 2564816638 ManufacturerSpecificPort "Identifies the action to be performed on 'Other, manufacturer specific port' communications port.";
CM_ SG_ 2564816638 CurrentDataLink "Identifies the action to be performed on the communications port that this parameter was received.";
CM_ SG_ 2564816638 SAE_J1587 "Identifies the action to be performed on the SAE J1587 communications port.";
CM_ SG_ 2564816638 SAE_J1922 "Identifies the action to be performed on the SAE J1922 communications port.";
CM_ SG_ 2564816638 J1939Network1 "Identifies the action to be performed on the SAE J1939 Network #1, Primary vehicle communications port.";
CM_ BO_ 2566837502 "Emissions-related active diagnostic trouble codes.";
CM_ SG_ 2566837502 FlashRedStopLamp "This parameter provides the capability to flash the RSL (SPN 3039).";
CM_ SG_ 2566837502 FlashProtectLamp "This parameter provides the capability to flash the engine protect lamp (SPN 3041).";
CM_ SG_ 2566837502 MalfunctionIndicatorLampStatus "A lamp used to relay only emissions-related trouble code information.";
CM_ SG_ 2566837502 RedStopLampState "This lamp is uesed to relay trouble code information that is of a severe enought condition that it warrants stopping the vehicle.";
CM_ SG_ 2566837502 AmberWarningLampStatus "This lamp is used to relay trouble code information that is reporting a problem with the vehicle system but the vehicle need
not be immediately stopped.";
CM_ SG_ 2566837502 ProtectLampStatus "This lamp is used to relay trouble code informatio that is reporting a problem with a vehicle system that is most
probably not electronic subsystem related.";
CM_ SG_ 2566837502 FlashMalfuncIndicatorLamp "This parameter provides the capability to flash the MIL (SPN 3038).";
CM_ SG_ 2566837502 FlashAmberWarningLamp "This parameter provides the capability to flash the AWL (SPN 3040). ";
CM_ SG_ 2566837502 DTC5 "Diagnostic Trouble Code";
CM_ SG_ 2566837502 DTC4 "Diagnostic Trouble Code";
CM_ SG_ 2566837502 DTC3 "Diagnostic Trouble Code";
CM_ SG_ 2566837502 DTC2 "Diagnostic Trouble Code";
CM_ SG_ 2566837502 DTC1 "Diagnostic Trouble Code";
CM_ BO_ 2566837246 "Diagnostic data clear/Reset for active DTCs";
CM_ BO_ 2566836990 "Non-continously monitored systems test identifiers support";
CM_ SG_ 2566836990 TestIdentifierSupported "Indicates the test identifiers that the controller supports.";
CM_ BO_ 2566834942 "Active diagnostic trouble codes";
CM_ SG_ 2566834942 FlashRedStopLamp "This parameter provides the capability to flash the RSL (SPN 3039).";
CM_ SG_ 2566834942 FlashProtectLamp "This parameter provides the capability to flash the engine protect lamp (SPN 3041).";
CM_ SG_ 2566834942 FlashMalfuncIndicatorLamp "This parameter provides the capability to flash the MIL (SPN 3038).";
CM_ SG_ 2566834942 FlashAmberWarningLamp "This parameter provides the capability to flash the AWL (SPN 3040). ";
CM_ SG_ 2566834942 MalfunctionIndicatorLampStatus "A lamp used to relay only emissions-related trouble code information.";
CM_ SG_ 2566834942 AmberWarningLampStatus "This lamp is used to relay trouble code information that is reporting a problem with the vehicle system but the vehicle need
not be immediately stopped.";
CM_ SG_ 2566834942 RedStopLampState "This lamp is uesed to relay trouble code information that is of a severe enought condition that it warrants stopping the vehicle.";
CM_ SG_ 2566834942 ProtectLampStatus "This lamp is used to relay trouble code informatio that is reporting a problem with a vehicle system that is most
probably not electronic subsystem related.";
CM_ SG_ 2566834942 DTC5 "Diagnostic Trouble Code";
CM_ SG_ 2566834942 DTC4 "Diagnostic Trouble Code";
CM_ SG_ 2566834942 DTC3 "Diagnostic Trouble Code";
CM_ SG_ 2566834942 DTC2 "Diagnostic Trouble Code";
CM_ SG_ 2566834942 DTC1 "Diagnostic Trouble Code";
CM_ BO_ 2566780926 "Utility Total AC Reactive Power";
CM_ SG_ 2566780926 UtlityOverallPowerFactorLagging "Lead/lag status for utility incomer average power factor.";
CM_ SG_ 2566780926 UtilityOverallPowerFactor "The average power factor of the utility incomer.";
CM_ SG_ 2566780926 UtilityTotalReactivePower "The total reactive power delivered by the utility incomer";
CM_ BO_ 2566781182 "Utility Total AC Power";
CM_ SG_ 2566781182 UtilityTotalApparentPower "The total apparent power delivered by the utility incomer.";
CM_ SG_ 2566781182 UtilityTotalRealPower "Total real power delivered by the utility incomer.";
CM_ BO_ 2566778366 "Utility Total AC Energy";
CM_ SG_ 2566778366 UtilityTotalKWHoursImport "The total kilowatt-hours that have been imported by the utility incomer.";
CM_ SG_ 2566778366 UtilityTotalKWHoursExport "The total kilowatt-hours that have been exported by the utility incomer.";
CM_ BO_ 2566778622 "Utility Phase C AC Reactive Power";
CM_ SG_ 2566778622 UtilityPhaseCPowerFactorLagging "Lead/lag status for utility incomer phase C power factor.";
CM_ SG_ 2566778622 UtilityPhaseCPowerFactor "The power factor of phases C of the utility incomer.";
CM_ SG_ 2566778622 UtilityPhaseCReactivePower "The reactive power delivered by phase C of the utility incomer";
CM_ BO_ 2566778878 "Utility Phase C AC Power";
CM_ SG_ 2566778878 UtilityPhaseCApparentPower "The apparent power delivered by phase C of the utility incomer.";
CM_ SG_ 2566778878 UtilityPhaseCRealPower "The real power delivered by phase C of the utility incomer.";
CM_ BO_ 2566779134 "Utility Phase C AC Basic Quantities";
CM_ SG_ 2566779134 UtilityPhaseCACRMSCurrent "RMS current measured at the utility incomer phase C.";
CM_ SG_ 2566779134 UtilityPhaseCACFrequency "AC frequency measured at the utility incomer phase C.";
CM_ SG_ 2566779134 UtltyPhsCLneNeutralACRMSVoltage "Line to Neutral RMS voltage measured at the utility incomer phase C.";
CM_ SG_ 2566779134 UtltyPhseCALineLineACRMSVoltage "Line to Line RMS voltage measured at the utility incomer phase CA.";
CM_ BO_ 2566779390 "Utility Phase B AC Reactive Power";
CM_ SG_ 2566779390 UtilityPhaseBPowerFactorLagging "Lead/lag status for utility incomer phase B power factor.";
CM_ SG_ 2566779390 UtilityPhaseBPowerFactor "The power factor of phases B of the utility incomer.";
CM_ SG_ 2566779390 UtilityPhaseBReactivePower "The reactive power delivered by phase B of the utility incomer";
CM_ BO_ 2566779646 "Utility Phase B AC Power";
CM_ SG_ 2566779646 UtilityPhaseBApparentPower "The apparent power delivered by phase B of the utility incomer.";
CM_ SG_ 2566779646 UtilityPhaseBRealPower "The real power delivered by phase B of the utility incomer.";
CM_ BO_ 2566779902 "Utility Phase B AC Basic Quantities";
CM_ SG_ 2566779902 UtilityPhaseBACRMSCurrent "RMS current measured at the utility incomer phase B.";
CM_ SG_ 2566779902 UtilityPhaseBACFrequency "AC frequency measured at the utility incomer phase B.";
CM_ SG_ 2566779902 UtltyPhsBLneNeutralACRMSVoltage "Line to Neutral RMS voltage measured at the utility incomer phase B.";
CM_ SG_ 2566779902 UtltyPhseBCLineLineACRMSVoltage "Line to Line RMS voltage measured at the utility incomer phase BC.";
CM_ BO_ 2566780158 "Utility Phase A  AC Reactive Power";
CM_ SG_ 2566780158 UtilityPhaseAPowerFactorLagging "Lead/lag status for utility incomer phase A power factor.";
CM_ SG_ 2566780158 UtilityPhaseAPowerFactor "The power factor of phase A of the utility incomer.";
CM_ SG_ 2566780158 UtilityPhaseAReactivePower "The reactive power delivered by phase A of the utility incomer";
CM_ BO_ 2566780414 "Utility Phase A  AC Power";
CM_ SG_ 2566780414 UtilityPhaseAApparentPower "The apparent power delivered by phase A of the utility incomer.";
CM_ SG_ 2566780414 UtilityPhaseARealPower "The real power delivered by phase A of the utility incomer.";
CM_ BO_ 2566780670 "Utility Phase A Basic AC Quantities";
CM_ SG_ 2566780670 UtilityPhaseAACRMSCurrent "RMS current measured at the utility incomer phase A.";
CM_ SG_ 2566780670 UtilityPhaseAACFrequency "AC frequency measured at the utility incomer phase A.";
CM_ SG_ 2566780670 UtltyPhsALneNeutralACRMSVoltage "Line to Neutral RMS voltage measured at the utility incomer phase A.";
CM_ SG_ 2566780670 UtltyPhseABLineLineACRMSVoltage "Line to Line RMS voltage measured at the utility incomer phase AB.";
CM_ BO_ 2566781438 "Utility Average Basic AC Quantities";
CM_ SG_ 2566781438 UtilityAverageACRMSCurrent "Average RMS current measured at the utility incomer.";
CM_ SG_ 2566781438 UtilityAverageACFrequency "Average AC frequency measured at the utility incomer.";
CM_ SG_ 2566781438 UtltyAvrgLneNeutralACRMSVoltage "The average Line to Neutral AC RMS voltage measured at the utility incomer .";
CM_ SG_ 2566781438 UtltyAvrageLineLineACRMSVoltage "Average Line to Line RMS voltage measured at the utility incomer .";
CM_ BO_ 2566784254 "Generator Total AC Reactive Power";
CM_ SG_ 2566784254 GnrtorOverallPowerFactorLagging "Lead/lag status for generator average power factor.";
CM_ SG_ 2566784254 GeneratorOverallPowerFactor "The average power factor of the generator.";
CM_ SG_ 2566784254 GeneratorTotalReactivePower "The total reactive power delivered by the generator";
CM_ BO_ 2566784510 "Generator Total AC Power";
CM_ SG_ 2566784510 GeneratorTotalApparentPower "The total apparent power delivered by the generator.";
CM_ SG_ 2566784510 GeneratorTotalRealPower "Total real power delivered by the generator.";
CM_ BO_ 2566781694 "Generator Total AC Energy";
CM_ SG_ 2566781694 GeneratorTotalKWHoursImport "The total kilowatt-hours that have been imported by the generator.";
CM_ SG_ 2566781694 GeneratorTotalKWHoursExport "The total kilowatt-hours that have been exported by the generator.";
CM_ BO_ 2566781950 "Generator Phase C AC Reactive Power";
CM_ SG_ 2566781950 GnratorPhaseCPowerFactorLagging "Lead/lag status for generator phase C power factor.";
CM_ SG_ 2566781950 GeneratorPhaseCPowerFactor "The power factor of phases C of the generator.";
CM_ SG_ 2566781950 GeneratorPhaseCReactivePower "The reactive power delivered by phase C of the generator";
CM_ BO_ 2566782206 "Generator Phase C AC Power";
CM_ SG_ 2566782206 GeneratorPhaseCApparentPower "The apparent power delivered by phase C of the generator.";
CM_ SG_ 2566782206 GeneratorPhaseCRealPower "The real power delivered by phase C of the generator.";
CM_ BO_ 2566782462 "Generator Phase C Basic AC Quantities";
CM_ SG_ 2566782462 GeneratorPhaseCACRMSCurrent "RMS current measured at the generator phase C output.";
CM_ SG_ 2566782462 GeneratorPhaseCACFrequency "AC frequency measured at the generator phase C output.";
CM_ SG_ 2566782462 GnrtrPhsCLneNeutralACRMSVoltage "Line to Neutral RMS voltage measured at the generator phase C output.";
CM_ SG_ 2566782462 GnrtrPhseCALineLineACRMSVoltage "Line to Line RMS voltage measured at the generator phase CA output.";
CM_ BO_ 2566782718 "Generator Phase B AC Reactive Power";
CM_ SG_ 2566782718 GnratorPhaseBPowerFactorLagging "Lead/lag status for generator phase B power factor.";
CM_ SG_ 2566782718 GeneratorPhaseBPowerFactor "The power factor of phases B of the generator.";
CM_ SG_ 2566782718 GeneratorPhaseBReactivePower "The reactive power delivered by phase B of the generator";
CM_ BO_ 2566782974 "Generator Phase B AC Power";
CM_ SG_ 2566782974 GeneratorPhaseBApparentPower "The apparent power delivered by phase B of the generator.";
CM_ SG_ 2566782974 GeneratorPhaseBRealPower "The real power delivered by phase B of the generator.";
CM_ BO_ 2566783230 "Generator Phase B Basic AC Quantities";
CM_ SG_ 2566783230 GeneratorPhaseBACRMSCurrent "RMS current measured at the generator phase B output.";
CM_ SG_ 2566783230 GeneratorPhaseBACFrequency "AC frequency measured at the generator phase B output.";
CM_ SG_ 2566783230 GnrtrPhsBLneNeutralACRMSVoltage "Line to Neutral RMS voltage measured at the generator phase B output.";
CM_ SG_ 2566783230 GnrtrPhseBCLineLineACRMSVoltage "Line to Line RMS voltage measured at the generator phase BC output.";
CM_ BO_ 2566783486 "Generator Phase A AC Reactive Power";
CM_ SG_ 2566783486 GnratorPhaseAPowerFactorLagging "Lead/lag status for generator phase A power factor.";
CM_ SG_ 2566783486 GeneratorPhaseAPowerFactor "The power factor of phase A of the generator.";
CM_ SG_ 2566783486 GeneratorPhaseAReactivePower "The reactive power delivered by phase A of the generator";
CM_ BO_ 2566783742 "Generator Phase A AC Power";
CM_ SG_ 2566783742 GeneratorPhaseAApparentPower "The apparent power delivered by phase A of the generator.";
CM_ SG_ 2566783742 GeneratorPhaseARealPower "The real power delivered by phase A of the generator.";
CM_ BO_ 2566783998 "Generator Phase A Basic AC Quantities";
CM_ SG_ 2566783998 GeneratorPhaseAACRMSCurrent "RMS current measured at the generator phase A output.";
CM_ SG_ 2566783998 GeneratorPhaseAACFrequency "AC frequency measured at the generator phase A output.";
CM_ SG_ 2566783998 GnrtrPhsALneNeutralACRMSVoltage "Line to Neutral RMS voltage measured at the generator phase A output.";
CM_ SG_ 2566783998 GnrtrPhseABLineLineACRMSVoltage "Line to Line RMS voltage measured at the generator phase AB output.";
CM_ BO_ 2566784766 "Generator Average Basic AC Quantities";
CM_ SG_ 2566784766 GeneratorAverageACRMSCurrent "Average RMS current measured at the generator output.";
CM_ SG_ 2566784766 GeneratorAverageACFrequency "Average AC frequency measured at the generator output.";
CM_ SG_ 2566784766 GnrtrAvrgLneNeutralACRMSVoltage "The average Line to Neutral AC RMS voltage measured at the Generator output.";
CM_ SG_ 2566784766 GnrtrAvrageLineLineACRMSVoltage "Average Line to Line RMS voltage measured at the generator output.";
CM_ BO_ 2566776830 "Bus #1/Utility Sync Check Status";
CM_ SG_ 2566776830 Bus1_UtilityACPhaseDifference "The phase difference between the Bus #1 voltage and Utility voltage.";
CM_ SG_ 2566776830 Bus1_UtilityInSync "Indicator of whether Bus #1 and Utility are properly synchronized for paralleling. This indicator will be based on parameters such as Voltage Match, Frequency Match, and Phase Match.";
CM_ SG_ 2566776830 Bus1_UtilityVoltageMatch "Indicator of whether voltage difference between Bus #1 and Utility is adequate for paralleling. This indicator will be based on the measured AC voltages qualified using parameters such as Voltage Tolerance.";
CM_ SG_ 2566776830 Bus1_UtilityFrequencyMatch "Indicator of whether frequency difference between Bus #1 and Utility is adequate for paralleling. This indicator will be based on the measured AC frequencies qualified using parameters such as Frequency Tolerance, Phase Tolerance, and Dwell Time.";
CM_ SG_ 2566776830 Bus1_UtilityPhaseMatch "Indicator of whether phase difference between Bus #1 and Utility is adequate for paralleling. This indicator will be based on the measured AC phase difference qualified using parameters such as Phase Tolerance and Dwell Time.";
CM_ SG_ 2566776830 Bus1_UtilityDeadBus "Indicator of whether Bus #1 is considered dead for closing to the utility. This indicator will be based on parameters such as Bus #1 Voltage and dead bus threshold values.";
CM_ BO_ 2566777342 "Bus #1 Phase C  Basic AC Quantities";
CM_ SG_ 2566777342 Bus1PhaseCACFrequency "AC frequency measured at bus #1 phase C.";
CM_ SG_ 2566777342 Bs1PhseCLineNeutralACRMSVoltage "Line to Neutral RMS voltage measured at bus #1 phase C.";
CM_ SG_ 2566777342 Bus1PhaseCALineLineACRMSVoltage "Line to Line RMS voltage measured at bus #1 phase CA.";
CM_ BO_ 2566777598 "Bus #1 Phase B  Basic AC Quantities";
CM_ SG_ 2566777598 Bus1PhaseBACFrequency "AC frequency measured at bus #1 phase B.";
CM_ SG_ 2566777598 Bs1PhseBLineNeutralACRMSVoltage "Line to Neutral RMS voltage measured at bus #1 phase B.";
CM_ SG_ 2566777598 Bus1PhaseBCLineLineACRMSVoltage "Line to Line RMS voltage measured at bus #1 phase BC.";
CM_ BO_ 2566777854 "Bus #1 Phase A  Basic AC Quantities";
CM_ SG_ 2566777854 Bus1PhaseAACFrequency "AC frequency measured at bus #1 phase A.";
CM_ SG_ 2566777854 Bs1PhseALineNeutralACRMSVoltage "Line to Neutral RMS voltage measured at bus #1 phase A.";
CM_ SG_ 2566777854 Bus1PhaseABLineLineACRMSVoltage "Line to Line RMS voltage measured at bus #1 phase AB.";
CM_ BO_ 2566777086 "Bus #1/Generator Sync Check Status";
CM_ SG_ 2566777086 Bus1_GeneratorACPhaseDifference "The phase difference between the Bus #1 voltage and Generator voltage.";
CM_ SG_ 2566777086 Bus1_GeneratorInSync "Indicator of whether Bus #1 and Generator are properly synchronized for paralleling. This indicator will be based on parameters such as Voltage Match, Frequency Match, and Phase Match.";
CM_ SG_ 2566777086 Bus1_GeneratorVoltageMatch "Indicator of whether voltage difference between Bus #1 and Generator is adequate for paralleling. This indicator will be based on the measured AC voltages qualified using parameters such as Voltage Tolerance.";
CM_ SG_ 2566777086 Bus1_GeneratorFrequencyMatch "Indicator of whether frequency difference between Bus #1 and Generator is adequate for paralleling. This indicator will be based on the measured AC frequencies qualified using parameters such as Frequency Tolerance, Phase Tolerance, and Dwell Time.";
CM_ SG_ 2566777086 Bus1_GeneratorPhaseMatch "Indicator of whether phase difference between Bus #1 and Generator is adequate for paralleling. This indicator will be based on the measured AC phase difference qualified using parameters such as Phase Tolerance and Dwell Time.";
CM_ SG_ 2566777086 Bus1_GeneratorDeadBus "Indicator of whether Bus #1 is considered dead for closing to the generator. This indicator will be based on parameters such as Bus #1 Voltage and dead bus threshold values.";
CM_ BO_ 2566778110 "Bus #1 Average Basic AC Quantities";
CM_ SG_ 2566778110 Bus1AverageACFrequency "Average AC frequency measured at bus #1.";
CM_ SG_ 2566778110 Bs1AvrgeLineNeutralACRMSVoltage "The average Line to Neutral AC RMS voltage measured at bus #1 .";
CM_ SG_ 2566778110 Bus1AverageLineLineACRMSVoltage "Average Line to Line RMS voltage measured at bus #1 .";
CM_ BO_ 2633895422 "Working Set Master";
CM_ BO_ 2566838526 "Commanded Address";
CM_ SG_ 2566838526 AddressAssignment "The source address that is to be assigned to the CA that has the NAME corresponding to the one conveyed in the first eight bytes of this Commanded Address message.";
CM_ SG_ 2566838526 IndustryGroup "0 = Global; 
   1  = On-Highway; 
   2  = Agricultural and Forestry; 
   3  = Construction; 
   4  = Marine;
   5  = Industrial - Process
          Control - Stationary (Gen-Sets)
   6  = Reserve for SAE
   7  = Reserve for SAE";
CM_ SG_ 2566838526 ManufacturerCode "Assigned by NMEA 2000 Committee";
CM_ BO_ 2565799678 "Address Claimed";
CM_ SG_ 2565799678 IndustryGroup "0 = Global; 
   1  = On-Highway; 
   2  = Agricultural and Forestry; 
   3  = Construction; 
   4  = Marine;
   5  = Industrial - Process
          Control - Stationary (Gen-Sets)
   6  = Reserve for SAE
   7  = Reserve for SAE";
CM_ SG_ 2565799678 ManufacturerCode "Assigned by NMEA 2000 Committee";
CM_ BO_ 2563440382 "Transfer";
CM_ SG_ 2563440382 ShrtNameOfActualReportingDevice "Short name of reporting device of the requested PGN via the Transfer PGN.";
CM_ SG_ 2563440382 LengthOfDataForTheReportedPGN "Length of data reported with the associated PGN via the Transfer PGN.";
CM_ SG_ 2563440382 PGNofRequstedInformation "PGN associated with this transfer message";
CM_ BO_ 2632711934 "Transport Protocol - Data Transfer";
CM_ BO_ 2632777470 "Transport Protocol - Connection Management";
CM_ SG_ 2632777470 TotalNumberOfPacketsEoMA "Total number of packets for BAM message.Total number of packets received for RTS/CTS message.Total number of packets for RTS/CTS message.";
CM_ SG_ 2632777470 TotalMessageSizeEoMA "Total message size (in bytes) for BAM message.Total message size (in bytes) for RTS/CTS message.Total message size (in bytes) for RTS/CTS message.";
CM_ SG_ 2632777470 TotalMessageSizeBAM "Total message size (in bytes) for BAM message.Total message size (in bytes) for RTS/CTS message.Total message size (in bytes) for RTS/CTS message.";
CM_ SG_ 2632777470 TotalNumberOfPacketsBAM "Total number of packets for BAM message.Total number of packets received for RTS/CTS message.Total number of packets for RTS/CTS message.";
CM_ SG_ 2632777470 ConnectionAbortReason "Reason for connection abort message.";
CM_ SG_ 2632777470 NextPacketNumberToBeSent "Next Packet Number to be sent (TP.CM_CTS)";
CM_ SG_ 2632777470 NumberOfPacketsThatCanBeSent "Number of Packets that can be sent (TP.CM_CTS)";
CM_ SG_ 2632777470 MaximumNumberOfPackets "Maximum number of packets for RTS/CTS message.";
CM_ SG_ 2632777470 TotalNumberOfPackets "Total number of packets for BAM message.Total number of packets received for RTS/CTS message.Total number of packets for RTS/CTS message.";
CM_ SG_ 2632777470 TotalMessageSize "Total message size (in bytes) for BAM message.Total message size (in bytes) for RTS/CTS message.Total message size (in bytes) for RTS/CTS message.";
CM_ BO_ 2563374846 "Request 2";
CM_ SG_ 2563374846 UseTransferMode "Requester is to respond via the Transfer PGN";
CM_ SG_ 2563374846 ParameterGroupNumber "PGN which is requested by Request2 message";
BA_DEF_ SG_  "SigType" ENUM  "Default","Range","RangeSigned","ASCII","Discrete","Control","ReferencePGN","DTC","StringDelimiter","StringLength","StringLengthControl";
BA_DEF_ SG_  "GenSigStartValue" INT 0 10000;
BA_DEF_ SG_  "GenSigSendType" ENUM  "Cyclic","OnWrite","reserved","OnChange","reserved","reserved","reserved","NoSigSendType";
BA_DEF_ SG_  "GenSigILSupport" ENUM  "Yes","No";
BA_DEF_ SG_  "GenSigEVName" STRING ;
BA_DEF_ SG_  "SPN" INT 0 524287;
BA_DEF_ BO_  "GenMsgStartDelayTime" INT 0 100000;
BA_DEF_ BO_  "GenMsgILSupport" ENUM  "Yes","No";
BA_DEF_ BO_  "GenMsgRequestable" INT 0 1;
BA_DEF_ BO_  "GenMsgSendType" ENUM  "cyclic","reserved","cyclicIfActive","reserved","reserved","reserved","reserved","reserved","noMsgSendType";
BA_DEF_ BO_  "VFrameFormat" ENUM  "StandardCAN","ExtendedCAN","reserved","J1939PG";
BA_DEF_ BO_  "GenMsgCycleTime" INT 0 3600000;
BA_DEF_ SG_  "SystemSignalLongSymbol" STRING ;
BA_DEF_DEF_  "SigType" "Default";
BA_DEF_DEF_  "GenSigStartValue" 0;
BA_DEF_DEF_  "GenSigSendType" "NoSigSendType";
BA_DEF_DEF_  "GenSigILSupport" "Yes";
BA_DEF_DEF_  "GenSigEVName" "Env@Nodename_@Signame";
BA_DEF_DEF_  "SPN" 0;
BA_DEF_DEF_  "GenMsgStartDelayTime" 0;
BA_DEF_DEF_  "GenMsgILSupport" "Yes";
BA_DEF_DEF_  "GenMsgRequestable" 1;
BA_DEF_DEF_  "GenMsgSendType" "noMsgSendType";
BA_DEF_DEF_  "VFrameFormat" "J1939PG";
BA_DEF_DEF_  "GenMsgCycleTime" 0;
BA_DEF_DEF_  "SystemSignalLongSymbol" "";
BA_ "GenMsgCycleTime" BO_ 2566758654 500;
BA_ "GenMsgSendType" BO_ 2566758654 0;
BA_ "GenMsgCycleTime" BO_ 2566753278 500;
BA_ "GenMsgSendType" BO_ 2566753278 0;
BA_ "GenMsgCycleTime" BO_ 2565869822 50;
BA_ "GenMsgSendType" BO_ 2565869822 0;
BA_ "GenMsgCycleTime" BO_ 2566763006 500;
BA_ "GenMsgSendType" BO_ 2566763006 0;
BA_ "GenMsgCycleTime" BO_ 2566762494 500;
BA_ "GenMsgSendType" BO_ 2566762494 0;
BA_ "GenMsgCycleTime" BO_ 2565870078 50;
BA_ "GenMsgSendType" BO_ 2565870078 0;
BA_ "GenMsgCycleTime" BO_ 2566762750 500;
BA_ "GenMsgSendType" BO_ 2566762750 0;
BA_ "GenMsgCycleTime" BO_ 2365428478 250;
BA_ "GenMsgCycleTime" BO_ 2566743806 1000;
BA_ "GenMsgSendType" BO_ 2566743806 0;
BA_ "GenMsgCycleTime" BO_ 2550660862 100;
BA_ "GenMsgCycleTime" BO_ 2566805758 100;
BA_ "GenMsgSendType" BO_ 2566805758 0;
BA_ "GenMsgCycleTime" BO_ 2566806014 100;
BA_ "GenMsgSendType" BO_ 2566806014 0;
BA_ "GenMsgCycleTime" BO_ 2362638078 100;
BA_ "GenMsgSendType" BO_ 2362638078 0;
BA_ "GenMsgCycleTime" BO_ 2365479678 100;
BA_ "GenMsgSendType" BO_ 2365479678 0;
BA_ "GenMsgCycleTime" BO_ 2566837758 1000;
BA_ "GenMsgSendType" BO_ 2566837758 0;
BA_ "GenMsgCycleTime" BO_ 2566775038 1000;
BA_ "GenMsgSendType" BO_ 2566775038 0;
BA_ "SPN" SG_ 2566758654 Aftrtrtmnt2FlInjctor1HeaterCtrl 4302;
BA_ "SigType" SG_ 2566758654 Aftrtrtmnt2FlInjctor1HeaterCtrl 1;
BA_ "SPN" SG_ 2566758654 Aftertreatment2FuelPress1Ctrl 3493;
BA_ "SigType" SG_ 2566758654 Aftertreatment2FuelPress1Ctrl 1;
BA_ "SPN" SG_ 2566758654 Aftertreatment2FuelPress1 3494;
BA_ "SigType" SG_ 2566758654 Aftertreatment2FuelPress1 1;
BA_ "SPN" SG_ 2566758654 Aftrtratment2FuelEnableActuator 3496;
BA_ "SigType" SG_ 2566758654 Aftrtratment2FuelEnableActuator 4;
BA_ "SPN" SG_ 2566758654 Aftrtratment2RegenerationStatus 3497;
BA_ "SigType" SG_ 2566758654 Aftrtratment2RegenerationStatus 4;
BA_ "SPN" SG_ 2566758654 Aftertreatment2Ignt 3498;
BA_ "SigType" SG_ 2566758654 Aftertreatment2Ignt 4;
BA_ "SPN" SG_ 2566758654 Aftrtreatment2FuelDrainActuator 4098;
BA_ "SigType" SG_ 2566758654 Aftrtreatment2FuelDrainActuator 4;
BA_ "SPN" SG_ 2566758654 Aftertreatment2FuelRate 3495;
BA_ "SigType" SG_ 2566758654 Aftertreatment2FuelRate 1;
BA_ "SPN" SG_ 2566753278 DslPrticulateFilterOutletPress2 3612;
BA_ "SigType" SG_ 2566753278 DslPrticulateFilterOutletPress2 1;
BA_ "SPN" SG_ 2566753278 DslPrticulateFilterIntakePress2 3611;
BA_ "SigType" SG_ 2566753278 DslPrticulateFilterIntakePress2 1;
BA_ "SPN" SG_ 2566756862 Aftrtrtmnt2TtlNmbrOfActvRgnrtnMn 3732;
BA_ "SigType" SG_ 2566756862 Aftrtrtmnt2TtlNmbrOfActvRgnrtnMn 1;
BA_ "SystemSignalLongSymbol" SG_ 2566756862 Aftrtrtmnt2TtlNmbrOfActvRgnrtnMn "Aftrtrtmnt2TtlNmbrOfActvRgnrtnMnlRqs";
BA_ "SPN" SG_ 2566756862 Aftrtrtmnt2TtlNmbrOfActvRgnrtnIn 3731;
BA_ "SigType" SG_ 2566756862 Aftrtrtmnt2TtlNmbrOfActvRgnrtnIn 1;
BA_ "SystemSignalLongSymbol" SG_ 2566756862 Aftrtrtmnt2TtlNmbrOfActvRgnrtnIn "Aftrtrtmnt2TtlNmbrOfActvRgnrtnInhbtRqs";
BA_ "SPN" SG_ 2566756862 Aftrtrtmnt2AvrgTmBtwnActvRgnrtns 5455;
BA_ "SigType" SG_ 2566756862 Aftrtrtmnt2AvrgTmBtwnActvRgnrtns 1;
BA_ "SPN" SG_ 2566756862 Aftrtrtmnt2TtlNmbrOfPssvRgnrtns 3730;
BA_ "SigType" SG_ 2566756862 Aftrtrtmnt2TtlNmbrOfPssvRgnrtns 1;
BA_ "SPN" SG_ 2566756862 Aftrtrtmnt2TtlPssvRgnrationTime 3729;
BA_ "SigType" SG_ 2566756862 Aftrtrtmnt2TtlPssvRgnrationTime 1;
BA_ "SPN" SG_ 2566756862 Aftrtrtmnt2TtlNmbrOfActvRgnrtns 3529;
BA_ "SigType" SG_ 2566756862 Aftrtrtmnt2TtlNmbrOfActvRgnrtns 1;
BA_ "SPN" SG_ 2566756862 Aftrtreatment2TotalDisabledTime 3528;
BA_ "SigType" SG_ 2566756862 Aftrtreatment2TotalDisabledTime 1;
BA_ "SPN" SG_ 2566756862 Aftrtrtmnt2TtalRegenerationTime 3527;
BA_ "SigType" SG_ 2566756862 Aftrtrtmnt2TtalRegenerationTime 1;
BA_ "SPN" SG_ 2566756862 Aftertreatment2TotalFuelUsed 3526;
BA_ "SigType" SG_ 2566756862 Aftertreatment2TotalFuelUsed 1;
BA_ "SPN" SG_ 2565869822 Aftrtrtmnt2IntkOxygnSnsrPrlmnryF 3264;
BA_ "SigType" SG_ 2565869822 Aftrtrtmnt2IntkOxygnSnsrPrlmnryF 1;
BA_ "SystemSignalLongSymbol" SG_ 2565869822 Aftrtrtmnt2IntkOxygnSnsrPrlmnryF "Aftrtrtmnt2IntkOxygnSnsrPrlmnryFMI";
BA_ "SPN" SG_ 2565869822 Aftrtrtmnt2IntkGsSnsrPwerStatus 3257;
BA_ "SigType" SG_ 2565869822 Aftrtrtmnt2IntkGsSnsrPwerStatus 4;
BA_ "SPN" SG_ 2565869822 Aftrtrtmnt2IntkGsSnsrHtrPrlmnryF 3261;
BA_ "SigType" SG_ 2565869822 Aftrtrtmnt2IntkGsSnsrHtrPrlmnryF 1;
BA_ "SystemSignalLongSymbol" SG_ 2565869822 Aftrtrtmnt2IntkGsSnsrHtrPrlmnryF "Aftrtrtmnt2IntkGsSnsrHtrPrlmnryFMI";
BA_ "SPN" SG_ 2565869822 Aftrtrtmnt2IntkNOxSnsrPrlmnryFMI 3263;
BA_ "SPN" SG_ 2565869822 Aftrtrtmnt2IntkGsSnsrHeaterCtrl 3262;
BA_ "SigType" SG_ 2565869822 Aftrtrtmnt2IntkGsSnsrHeaterCtrl 4;
BA_ "SPN" SG_ 2565869822 Aftrtrtmnt2IntkWdRngO2RdngStble 3260;
BA_ "SigType" SG_ 2565869822 Aftrtrtmnt2IntkWdRngO2RdngStble 4;
BA_ "SPN" SG_ 2565869822 Aftrtrtmnt2IntkNOxReadingStable 3259;
BA_ "SigType" SG_ 2565869822 Aftrtrtmnt2IntkNOxReadingStable 4;
BA_ "SPN" SG_ 2565869822 Aftrtrtmnt2IntkeGasSensorAtTemp 3258;
BA_ "SigType" SG_ 2565869822 Aftrtrtmnt2IntkeGasSensorAtTemp 4;
BA_ "SPN" SG_ 2565869822 Aftertreatment2IntakeO2 3256;
BA_ "SigType" SG_ 2565869822 Aftertreatment2IntakeO2 1;
BA_ "SPN" SG_ 2565869822 Aftertreatment2IntakeNOx 3255;
BA_ "SigType" SG_ 2565869822 Aftertreatment2IntakeNOx 1;
BA_ "SPN" SG_ 2566763006 Aftrtrtmnt2DslPrtcltFltrIntkGsTm 3278;
BA_ "SigType" SG_ 2566763006 Aftrtrtmnt2DslPrtcltFltrIntkGsTm 1;
BA_ "SystemSignalLongSymbol" SG_ 2566763006 Aftrtrtmnt2DslPrtcltFltrIntkGsTm "Aftrtrtmnt2DslPrtcltFltrIntkGsTmpPrlmnryFMI";
BA_ "SPN" SG_ 2566763006 Aftrtrtmnt2ExhstGsTmp1PrlmnryFMI 3277;
BA_ "SPN" SG_ 2566763006 Aftertreatment2ExhaustGasTemp1 3275;
BA_ "SigType" SG_ 2566763006 Aftertreatment2ExhaustGasTemp1 1;
BA_ "SPN" SG_ 2566763006 Aftrtrtmnt2DslPrtcltFltrInt_0000 3276;
BA_ "SigType" SG_ 2566763006 Aftrtrtmnt2DslPrtcltFltrInt_0000 1;
BA_ "SystemSignalLongSymbol" SG_ 2566763006 Aftrtrtmnt2DslPrtcltFltrInt_0000 "Aftrtrtmnt2DslPrtcltFltrIntkGsTmp";
BA_ "SPN" SG_ 2566762494 Aftrtrtmnt2DslPrtcltFltrIntrmdtG 3288;
BA_ "SigType" SG_ 2566762494 Aftrtrtmnt2DslPrtcltFltrIntrmdtG 1;
BA_ "SystemSignalLongSymbol" SG_ 2566762494 Aftrtrtmnt2DslPrtcltFltrIntrmdtG "Aftrtrtmnt2DslPrtcltFltrIntrmdtGsTmpPrlmnryFMI";
BA_ "SPN" SG_ 2566762494 Aftrtrtmnt2DslPrtcltFltrInt_0001 3284;
BA_ "SigType" SG_ 2566762494 Aftrtrtmnt2DslPrtcltFltrInt_0001 1;
BA_ "SystemSignalLongSymbol" SG_ 2566762494 Aftrtrtmnt2DslPrtcltFltrInt_0001 "Aftrtrtmnt2DslPrtcltFltrIntrmdtGsTmp";
BA_ "SPN" SG_ 2566762494 Aftrtrtmnt2DslPrtcltFltrDltPrssP 3287;
BA_ "SigType" SG_ 2566762494 Aftrtrtmnt2DslPrtcltFltrDltPrssP 1;
BA_ "SystemSignalLongSymbol" SG_ 2566762494 Aftrtrtmnt2DslPrtcltFltrDltPrssP "Aftrtrtmnt2DslPrtcltFltrDltPrssPrlmnryFMI";
BA_ "SPN" SG_ 2566762494 Aftrtrtmnt2DslPrtcltFltrDffPrss 3285;
BA_ "SigType" SG_ 2566762494 Aftrtrtmnt2DslPrtcltFltrDffPrss 1;
BA_ "SPN" SG_ 2566762494 Aftrtrtmnt2ExhstGsTmp2PrlmnryFMI 3286;
BA_ "SPN" SG_ 2566762494 Aftertreatment2ExhaustGasTemp2 3283;
BA_ "SigType" SG_ 2566762494 Aftertreatment2ExhaustGasTemp2 1;
BA_ "SPN" SG_ 2565870078 Aftrtrtmnt2OtltOxygnSnsrPrlmnryF 3274;
BA_ "SigType" SG_ 2565870078 Aftrtrtmnt2OtltOxygnSnsrPrlmnryF 1;
BA_ "SystemSignalLongSymbol" SG_ 2565870078 Aftrtrtmnt2OtltOxygnSnsrPrlmnryF "Aftrtrtmnt2OtltOxygnSnsrPrlmnryFMI";
BA_ "SPN" SG_ 2565870078 Aftrtrtmnt2OtltGsSnsrPwerStatus 3267;
BA_ "SigType" SG_ 2565870078 Aftrtrtmnt2OtltGsSnsrPwerStatus 4;
BA_ "SPN" SG_ 2565870078 Aftrtrtmnt2OtltGsSnsrHtrPrlmnryF 3271;
BA_ "SigType" SG_ 2565870078 Aftrtrtmnt2OtltGsSnsrHtrPrlmnryF 1;
BA_ "SystemSignalLongSymbol" SG_ 2565870078 Aftrtrtmnt2OtltGsSnsrHtrPrlmnryF "Aftrtrtmnt2OtltGsSnsrHtrPrlmnryFMI";
BA_ "SPN" SG_ 2565870078 Aftrtrtmnt2OtltNOxSnsrPrlmnryFMI 3273;
BA_ "SPN" SG_ 2565870078 Aftrtrtmnt2OtltGsSnsrHeaterCtrl 3272;
BA_ "SigType" SG_ 2565870078 Aftrtrtmnt2OtltGsSnsrHeaterCtrl 4;
BA_ "SPN" SG_ 2565870078 Aftrtrtmnt2OtltWdRngO2RdngStble 3270;
BA_ "SigType" SG_ 2565870078 Aftrtrtmnt2OtltWdRngO2RdngStble 4;
BA_ "SPN" SG_ 2565870078 Aftrtrtmnt2OtltNOxReadingStable 3269;
BA_ "SigType" SG_ 2565870078 Aftrtrtmnt2OtltNOxReadingStable 4;
BA_ "SPN" SG_ 2565870078 Aftrtrtmnt2OtletGasSensorAtTemp 3268;
BA_ "SigType" SG_ 2565870078 Aftrtrtmnt2OtletGasSensorAtTemp 4;
BA_ "SPN" SG_ 2565870078 Aftertreatment2OutletO2 3266;
BA_ "SigType" SG_ 2565870078 Aftertreatment2OutletO2 1;
BA_ "SPN" SG_ 2565870078 Aftertreatment2OutletNOx 3265;
BA_ "SigType" SG_ 2565870078 Aftertreatment2OutletNOx 1;
BA_ "SPN" SG_ 2566762750 Aftrtrtmnt2DslPrtcltFltrOtltGsTm 3280;
BA_ "SigType" SG_ 2566762750 Aftrtrtmnt2DslPrtcltFltrOtltGsTm 1;
BA_ "SystemSignalLongSymbol" SG_ 2566762750 Aftrtrtmnt2DslPrtcltFltrOtltGsTm "Aftrtrtmnt2DslPrtcltFltrOtltGsTmp";
BA_ "SPN" SG_ 2566762750 Aftrtrtmnt2DslPrtcltFltrExhstGsT 3282;
BA_ "SigType" SG_ 2566762750 Aftrtrtmnt2DslPrtcltFltrExhstGsT 1;
BA_ "SystemSignalLongSymbol" SG_ 2566762750 Aftrtrtmnt2DslPrtcltFltrExhstGsT "Aftrtrtmnt2DslPrtcltFltrExhstGsTmpPrlmnryFMI";
BA_ "SPN" SG_ 2566762750 Aftrtrtmnt2ExhstGsTmp3PrlmnryFMI 3281;
BA_ "SPN" SG_ 2566762750 Aftertreatment2ExhaustGasTemp3 3279;
BA_ "SigType" SG_ 2566762750 Aftertreatment2ExhaustGasTemp3 1;
BA_ "SPN" SG_ 2566748926 DslPrtclteFilter2AshLoadPercent 3723;
BA_ "SigType" SG_ 2566748926 DslPrtclteFilter2AshLoadPercent 1;
BA_ "SPN" SG_ 2566748926 DslPrtcltFltr2TmSncLstActvRgnrtn 3724;
BA_ "SigType" SG_ 2566748926 DslPrtcltFltr2TmSncLstActvRgnrtn 1;
BA_ "SPN" SG_ 2566748926 DslPrtcltFilter2SootLoadPercent 3722;
BA_ "SigType" SG_ 2566748926 DslPrtcltFilter2SootLoadPercent 1;
BA_ "SPN" SG_ 2566748926 Aftrtrtmnt2DslPrtcltFltrStLdRgnr 5467;
BA_ "SigType" SG_ 2566748926 Aftrtrtmnt2DslPrtcltFltrStLdRgnr 1;
BA_ "SystemSignalLongSymbol" SG_ 2566748926 Aftrtrtmnt2DslPrtcltFltrStLdRgnr "Aftrtrtmnt2DslPrtcltFltrStLdRgnrtnThrshld";
BA_ "SPN" SG_ 2566748414 Aftrtrtmnt2TrpNmbrOfActvRgnrtnMn 3748;
BA_ "SigType" SG_ 2566748414 Aftrtrtmnt2TrpNmbrOfActvRgnrtnMn 1;
BA_ "SystemSignalLongSymbol" SG_ 2566748414 Aftrtrtmnt2TrpNmbrOfActvRgnrtnMn "Aftrtrtmnt2TrpNmbrOfActvRgnrtnMnlRqs";
BA_ "SPN" SG_ 2566748414 Aftrtrtmnt2TrpNmbrOfActvRgnrtnIn 3747;
BA_ "SigType" SG_ 2566748414 Aftrtrtmnt2TrpNmbrOfActvRgnrtnIn 1;
BA_ "SystemSignalLongSymbol" SG_ 2566748414 Aftrtrtmnt2TrpNmbrOfActvRgnrtnIn "Aftrtrtmnt2TrpNmbrOfActvRgnrtnInhbtRqs";
BA_ "SPN" SG_ 2566748414 Aftrtrtmnt2TrpNmbrOfPssvRgnrtns 3746;
BA_ "SigType" SG_ 2566748414 Aftrtrtmnt2TrpNmbrOfPssvRgnrtns 1;
BA_ "SPN" SG_ 2566748414 Aftrtrtmnt2TrpPssvRgnrationTime 3745;
BA_ "SigType" SG_ 2566748414 Aftrtrtmnt2TrpPssvRgnrationTime 1;
BA_ "SPN" SG_ 2566748414 Aftrtrtmnt2TrpNmbrOfActvRgnrtns 3744;
BA_ "SigType" SG_ 2566748414 Aftrtrtmnt2TrpNmbrOfActvRgnrtns 1;
BA_ "SPN" SG_ 2566748414 Aftertreatment2TripDisabledTime 3743;
BA_ "SigType" SG_ 2566748414 Aftertreatment2TripDisabledTime 1;
BA_ "SPN" SG_ 2566748414 Aftrtrtmnt2TrpActvRgnrationTime 3742;
BA_ "SigType" SG_ 2566748414 Aftrtrtmnt2TrpActvRgnrationTime 1;
BA_ "SPN" SG_ 2566748414 Aftertreatment2TripFuelUsed 3741;
BA_ "SigType" SG_ 2566748414 Aftertreatment2TripFuelUsed 1;
BA_ "SPN" SG_ 2365428478 EngDerateRq 3644;
BA_ "SigType" SG_ 2365428478 EngDerateRq 1;
BA_ "SPN" SG_ 2365428478 EngEmergencyShutdownIndication 3607;
BA_ "SigType" SG_ 2365428478 EngEmergencyShutdownIndication 4;
BA_ "SPN" SG_ 2365428478 EngCtrlledShutdownRq 3606;
BA_ "SigType" SG_ 2365428478 EngCtrlledShutdownRq 4;
BA_ "SPN" SG_ 2365428478 EngCoolantCirculatingPumpCtrl 3605;
BA_ "SigType" SG_ 2365428478 EngCoolantCirculatingPumpCtrl 4;
BA_ "SPN" SG_ 2365428478 EngBlock_CoolantPreheaterCtrl 3604;
BA_ "SigType" SG_ 2365428478 EngBlock_CoolantPreheaterCtrl 4;
BA_ "SPN" SG_ 2365428478 EngElctrclSystmPwrCnsrvtionCtrl 3603;
BA_ "SigType" SG_ 2365428478 EngElctrclSystmPwrCnsrvtionCtrl 4;
BA_ "SPN" SG_ 2365428478 EngOilPreheaterCtrl 3602;
BA_ "SigType" SG_ 2365428478 EngOilPreheaterCtrl 4;
BA_ "SPN" SG_ 2365428478 EngOilPrimingPumpCtrl 3589;
BA_ "SigType" SG_ 2365428478 EngOilPrimingPumpCtrl 4;
BA_ "SPN" SG_ 2365428478 EngFuelShutoffValveLeakTestCtrl 3601;
BA_ "SigType" SG_ 2365428478 EngFuelShutoffValveLeakTestCtrl 4;
BA_ "SPN" SG_ 2365428478 EngFuelShutoff2Ctrl 2807;
BA_ "SigType" SG_ 2365428478 EngFuelShutoff2Ctrl 4;
BA_ "SPN" SG_ 2365428478 EngFuelShutoff1Ctrl 632;
BA_ "SigType" SG_ 2365428478 EngFuelShutoff1Ctrl 4;
BA_ "SPN" SG_ 2365428478 EngFuelShutoffVentCtrl 3608;
BA_ "SigType" SG_ 2365428478 EngFuelShutoffVentCtrl 4;
BA_ "SPN" SG_ 2365428478 TmeRemainingInEngOperatingState 3544;
BA_ "SigType" SG_ 2365428478 TmeRemainingInEngOperatingState 1;
BA_ "SPN" SG_ 2365428478 FuelPumpPrimerCtrl 4082;
BA_ "SigType" SG_ 2365428478 FuelPumpPrimerCtrl 4;
BA_ "SPN" SG_ 2365428478 EngOperatingState 3543;
BA_ "SigType" SG_ 2365428478 EngOperatingState 4;
BA_ "SPN" SG_ 2566743806 EngExhstVlvActtionSystemOilTemp 4288;
BA_ "SigType" SG_ 2566743806 EngExhstVlvActtionSystemOilTemp 1;
BA_ "SPN" SG_ 2566743806 EngExhstGsRcrcltn1MxrIntakeTemp 5020;
BA_ "SigType" SG_ 2566743806 EngExhstGsRcrcltn1MxrIntakeTemp 1;
BA_ "SPN" SG_ 2566743806 EngCoolantThermostatOpening 4194;
BA_ "SigType" SG_ 2566743806 EngCoolantThermostatOpening 1;
BA_ "SPN" SG_ 2566743806 EngCoolantPumpOutletTemp 4193;
BA_ "SigType" SG_ 2566743806 EngCoolantPumpOutletTemp 1;
BA_ "SPN" SG_ 2566743806 EngCoolantTemp2 4076;
BA_ "SigType" SG_ 2566743806 EngCoolantTemp2 1;
BA_ "SPN" SG_ 2499635454 NetVehicleWeightChange 413;
BA_ "SigType" SG_ 2499635454 NetVehicleWeightChange 1;
BA_ "SPN" SG_ 2499635454 GrossCombinationWeight 417;
BA_ "SigType" SG_ 2499635454 GrossCombinationWeight 1;
BA_ "SPN" SG_ 2550660862 ValveAssemblySupplyPress 4089;
BA_ "SigType" SG_ 2550660862 ValveAssemblySupplyPress 1;
BA_ "SPN" SG_ 2550660862 ValveAssemblyLoadSensePress 4088;
BA_ "SigType" SG_ 2550660862 ValveAssemblyLoadSensePress 1;
BA_ "SPN" SG_ 2550660862 ValvePilotPress 4087;
BA_ "SigType" SG_ 2550660862 ValvePilotPress 1;
BA_ "SPN" SG_ 2550660862 ValveLoadSensePress 4086;
BA_ "SigType" SG_ 2550660862 ValveLoadSensePress 1;
BA_ "SPN" SG_ 2566805758 BellowPressRearAxleRight 1728;
BA_ "SigType" SG_ 2566805758 BellowPressRearAxleRight 1;
BA_ "SPN" SG_ 2566805758 BellowPressRearAxleLeft 1727;
BA_ "SigType" SG_ 2566805758 BellowPressRearAxleLeft 1;
BA_ "SPN" SG_ 2566805758 BellowPressFrontAxleRight 1726;
BA_ "SigType" SG_ 2566805758 BellowPressFrontAxleRight 1;
BA_ "SPN" SG_ 2566805758 BellowPressFrontAxleLeft 1725;
BA_ "SigType" SG_ 2566805758 BellowPressFrontAxleLeft 1;
BA_ "SPN" SG_ 2566806014 RelativeLevelRearAxleRight 1723;
BA_ "SigType" SG_ 2566806014 RelativeLevelRearAxleRight 1;
BA_ "SPN" SG_ 2566806014 RelativeLevelRearAxleLeft 1724;
BA_ "SigType" SG_ 2566806014 RelativeLevelRearAxleLeft 1;
BA_ "SPN" SG_ 2566806014 RelativeLevelFrontAxleRight 1722;
BA_ "SigType" SG_ 2566806014 RelativeLevelFrontAxleRight 1;
BA_ "SPN" SG_ 2566806014 RelativeLevelFrontAxleLeft 1721;
BA_ "SigType" SG_ 2566806014 RelativeLevelFrontAxleLeft 1;
BA_ "SPN" SG_ 2362638078 SpeedDependentLevelCtrlRq 5295;
BA_ "SigType" SG_ 2362638078 SpeedDependentLevelCtrlRq 4;
BA_ "SPN" SG_ 2362638078 PrhbtAutomaticAirSuspensionCtrl 5274;
BA_ "SigType" SG_ 2362638078 PrhbtAutomaticAirSuspensionCtrl 4;
BA_ "SPN" SG_ 2362638078 MemoryLevelRq 5433;
BA_ "SigType" SG_ 2362638078 MemoryLevelRq 4;
BA_ "SPN" SG_ 2362638078 AllowLevelCtrlDuringBrakingCmd 5293;
BA_ "SigType" SG_ 2362638078 AllowLevelCtrlDuringBrakingCmd 4;
BA_ "SPN" SG_ 2362638078 ProhibitAirSuspensionCtrl 3215;
BA_ "SigType" SG_ 2362638078 ProhibitAirSuspensionCtrl 4;
BA_ "SPN" SG_ 2362638078 KneelingCmdRearAxle 1829;
BA_ "SigType" SG_ 2362638078 KneelingCmdRearAxle 4;
BA_ "SPN" SG_ 2362638078 KneelingCmdFrontAxle 1830;
BA_ "SigType" SG_ 2362638078 KneelingCmdFrontAxle 4;
BA_ "SPN" SG_ 2362638078 DamperStiffnessRqLift_TagAxle 1720;
BA_ "SigType" SG_ 2362638078 DamperStiffnessRqLift_TagAxle 1;
BA_ "SPN" SG_ 2362638078 DamperStiffnessRqRearAxle 1719;
BA_ "SigType" SG_ 2362638078 DamperStiffnessRqRearAxle 1;
BA_ "SPN" SG_ 2362638078 DamperStiffnessRqFrontAxle 1718;
BA_ "SigType" SG_ 2362638078 DamperStiffnessRqFrontAxle 1;
BA_ "SPN" SG_ 2362638078 LevelCtrlModeRq 1753;
BA_ "SigType" SG_ 2362638078 LevelCtrlModeRq 4;
BA_ "SPN" SG_ 2362638078 NominalLevelRqRearAxle 1750;
BA_ "SigType" SG_ 2362638078 NominalLevelRqRearAxle 4;
BA_ "SPN" SG_ 2362638078 NominalLevelRqFrontAxle 1751;
BA_ "SigType" SG_ 2362638078 NominalLevelRqFrontAxle 4;
BA_ "SPN" SG_ 2362638078 KneelingCtrlModeRq 1747;
BA_ "SigType" SG_ 2362638078 KneelingCtrlModeRq 4;
BA_ "SPN" SG_ 2362638078 KneelingRqRightSide 1748;
BA_ "SigType" SG_ 2362638078 KneelingRqRightSide 4;
BA_ "SPN" SG_ 2362638078 KneelingRqLeftSide 1749;
BA_ "SigType" SG_ 2362638078 KneelingRqLeftSide 4;
BA_ "SPN" SG_ 2362638078 AutomaticTractionHelp 2984;
BA_ "SigType" SG_ 2362638078 AutomaticTractionHelp 4;
BA_ "SPN" SG_ 2362638078 LiftAxle2PosCmd 1828;
BA_ "SigType" SG_ 2362638078 LiftAxle2PosCmd 4;
BA_ "SPN" SG_ 2362638078 LiftAxle1PosCmd 1752;
BA_ "SigType" SG_ 2362638078 LiftAxle1PosCmd 4;
BA_ "SPN" SG_ 2365479678 SpeedDependantLevelCtrlStatus 5296;
BA_ "SigType" SG_ 2365479678 SpeedDependantLevelCtrlStatus 4;
BA_ "SPN" SG_ 2365479678 MemoryLevel 5432;
BA_ "SigType" SG_ 2365479678 MemoryLevel 4;
BA_ "SPN" SG_ 2365479678 AllwLvelCtrlDuringBrakingStatus 5294;
BA_ "SigType" SG_ 2365479678 AllwLvelCtrlDuringBrakingStatus 4;
BA_ "SPN" SG_ 2365479678 SspensionCtrlRefusalInformation 1827;
BA_ "SigType" SG_ 2365479678 SspensionCtrlRefusalInformation 4;
BA_ "SPN" SG_ 2365479678 SuspensionRemoteCtrl2 1825;
BA_ "SigType" SG_ 2365479678 SuspensionRemoteCtrl2 4;
BA_ "SPN" SG_ 2365479678 SuspensionRemoteCtrl1 1826;
BA_ "SigType" SG_ 2365479678 SuspensionRemoteCtrl1 4;
BA_ "SPN" SG_ 2365479678 RearAxleInBumperRange 1823;
BA_ "SigType" SG_ 2365479678 RearAxleInBumperRange 4;
BA_ "SPN" SG_ 2365479678 FrontAxleInBumperRange 1824;
BA_ "SigType" SG_ 2365479678 FrontAxleInBumperRange 4;
BA_ "SPN" SG_ 2365479678 DoorRelease 1744;
BA_ "SigType" SG_ 2365479678 DoorRelease 4;
BA_ "SPN" SG_ 2365479678 VehicleMotionInhibit 1745;
BA_ "SigType" SG_ 2365479678 VehicleMotionInhibit 4;
BA_ "SPN" SG_ 2365479678 SecurityDevice 1746;
BA_ "SigType" SG_ 2365479678 SecurityDevice 4;
BA_ "SPN" SG_ 2365479678 LevelCtrlMode 1741;
BA_ "SigType" SG_ 2365479678 LevelCtrlMode 4;
BA_ "SPN" SG_ 2365479678 KneelingInformation 1742;
BA_ "SigType" SG_ 2365479678 KneelingInformation 4;
BA_ "SPN" SG_ 2365479678 LiftingCtrlModeRearAxle 1756;
BA_ "SigType" SG_ 2365479678 LiftingCtrlModeRearAxle 4;
BA_ "SPN" SG_ 2365479678 LiftingCtrlModeFrontAxle 1739;
BA_ "SigType" SG_ 2365479678 LiftingCtrlModeFrontAxle 4;
BA_ "SPN" SG_ 2365479678 LoweringCtrlModeRearAxle 1755;
BA_ "SigType" SG_ 2365479678 LoweringCtrlModeRearAxle 4;
BA_ "SPN" SG_ 2365479678 LoweringCtrlModeFrontAxle 1740;
BA_ "SigType" SG_ 2365479678 LoweringCtrlModeFrontAxle 4;
BA_ "SPN" SG_ 2365479678 AboveNominalLevelRearAxle 1736;
BA_ "SigType" SG_ 2365479678 AboveNominalLevelRearAxle 4;
BA_ "SPN" SG_ 2365479678 AboveNominalLevelFrontAxle 1737;
BA_ "SigType" SG_ 2365479678 AboveNominalLevelFrontAxle 4;
BA_ "SPN" SG_ 2365479678 BelowNominalLevelRearAxle 1754;
BA_ "SigType" SG_ 2365479678 BelowNominalLevelRearAxle 4;
BA_ "SPN" SG_ 2365479678 BelowNominalLevelFrontAxle 1738;
BA_ "SigType" SG_ 2365479678 BelowNominalLevelFrontAxle 4;
BA_ "SPN" SG_ 2365479678 NominalLevelRearAxle 1733;
BA_ "SigType" SG_ 2365479678 NominalLevelRearAxle 4;
BA_ "SPN" SG_ 2365479678 NominalLevelFrontAxle 1734;
BA_ "SigType" SG_ 2365479678 NominalLevelFrontAxle 4;
BA_ "SPN" SG_ 2365479678 LiftAxle2Pos 1822;
BA_ "SigType" SG_ 2365479678 LiftAxle2Pos 4;
BA_ "SPN" SG_ 2365479678 LiftAxle1Pos 1743;
BA_ "SigType" SG_ 2365479678 LiftAxle1Pos 4;
BA_ "SPN" SG_ 2566837758 Alt4Status 3356;
BA_ "SigType" SG_ 2566837758 Alt4Status 4;
BA_ "SPN" SG_ 2566837758 Alt3Status 3355;
BA_ "SigType" SG_ 2566837758 Alt3Status 4;
BA_ "SPN" SG_ 2566837758 Alt2Status 3354;
BA_ "SigType" SG_ 2566837758 Alt2Status 4;
BA_ "SPN" SG_ 2566837758 Alt1Status 3353;
BA_ "SigType" SG_ 2566837758 Alt1Status 4;
BA_ "SPN" SG_ 2566837758 AltSpeed 589;
BA_ "SigType" SG_ 2566837758 AltSpeed 1;
BA_ "SPN" SG_ 2633922558 AuxAbsPressReading 138;
BA_ "SigType" SG_ 2633922558 AuxAbsPressReading 1;
BA_ "SPN" SG_ 2633922558 AuxGagePressReading1 137;
BA_ "SigType" SG_ 2633922558 AuxGagePressReading1 1;
BA_ "SPN" SG_ 2633922558 AuxVacuumPressReading 136;
BA_ "SigType" SG_ 2633922558 AuxVacuumPressReading 1;
BA_ "SPN" SG_ 2566775038 SpecificHumidity 4490;
BA_ "SigType" SG_ 2566775038 SpecificHumidity 1;
BA_ "SPN" SG_ 2566775038 SolarSensorMax 2611;
BA_ "SigType" SG_ 2566775038 SolarSensorMax 1;
BA_ "SPN" SG_ 2566775038 SolarIntensityPercent 2610;
BA_ "SigType" SG_ 2566775038 SolarIntensityPercent 1;
BA_ "SPN" SG_ 2566836478 TestLimitMinimum 1228;
BA_ "SigType" SG_ 2566836478 TestLimitMinimum 1;
BA_ "SPN" SG_ 2566836478 TestLimitMaximum 1227;
BA_ "SigType" SG_ 2566836478 TestLimitMaximum 1;
BA_ "SPN" SG_ 2566836478 TestValue 1226;
BA_ "SigType" SG_ 2566836478 TestValue 1;
BA_ "SPN" SG_ 2566836478 TestType 1225;
BA_ "GenSigStartValue" SG_ 2566836478 TestType 1;
BA_ "SigType" SG_ 2566836478 TestType 1;
BA_ "SPN" SG_ 2566836478 TestIdentifier 1224;
BA_ "GenSigStartValue" SG_ 2566836478 TestIdentifier 1;
BA_ "SigType" SG_ 2566836478 TestIdentifier 1;
BA_ "SPN" SG_ 2565078782 SPN1High 1214;
BA_ "SPN" SG_ 2565078782 SPN1 1214;
BA_ "SPN" SG_ 2565078782 TestIdentifier 1224;
BA_ "GenSigStartValue" SG_ 2565078782 TestIdentifier 1;
BA_ "SigType" SG_ 2565078782 TestIdentifier 1;
BA_ "SPN" SG_ 2565078782 FailureModeIdentifier1 1215;
BA_ "SPN" SG_ 2566836222 FlashRedStopLamp 3039;
BA_ "SigType" SG_ 2566836222 FlashRedStopLamp 4;
BA_ "SPN" SG_ 2566836222 FlashProtectLamp 3041;
BA_ "SigType" SG_ 2566836222 FlashProtectLamp 4;
BA_ "SPN" SG_ 2566836222 FlashMalfuncIndicatorLamp 3038;
BA_ "SigType" SG_ 2566836222 FlashMalfuncIndicatorLamp 4;
BA_ "SPN" SG_ 2566836222 FlashAmberWarningLamp 3040;
BA_ "SigType" SG_ 2566836222 FlashAmberWarningLamp 4;
BA_ "SPN" SG_ 2566836222 MalfunctionIndicatorLampStatus 1213;
BA_ "SigType" SG_ 2566836222 MalfunctionIndicatorLampStatus 4;
BA_ "SPN" SG_ 2566836222 RedStopLampState 623;
BA_ "SigType" SG_ 2566836222 RedStopLampState 4;
BA_ "SPN" SG_ 2566836222 AmberWarningLampStatus 624;
BA_ "SigType" SG_ 2566836222 AmberWarningLampStatus 4;
BA_ "SPN" SG_ 2566836222 ProtectLampStatus 987;
BA_ "SigType" SG_ 2566836222 ProtectLampStatus 4;
BA_ "SigType" SG_ 2566836222 DTC5 7;
BA_ "SigType" SG_ 2566836222 DTC4 7;
BA_ "SigType" SG_ 2566836222 DTC3 7;
BA_ "SigType" SG_ 2566836222 DTC2 7;
BA_ "SigType" SG_ 2566836222 DTC1 7;
BA_ "SystemSignalLongSymbol" SG_ 2566835966 NOxConvertingCatalystAdsorberSta "NOxConvertingCatalystAdsorberStatus";
BA_ "SystemSignalLongSymbol" SG_ 2566835966 BoostPressureControlSystemSuppor "BoostPressureControlSystemSupport";
BA_ "SystemSignalLongSymbol" SG_ 2566835966 NOxConvertingCatalystAdsorberSup "NOxConvertingCatalystAdsorberSupport";
BA_ "SPN" SG_ 2566835966 MisfireMonitoringSupport 1221;
BA_ "SPN" SG_ 2566835966 OBDCompliance 1220;
BA_ "SigType" SG_ 2566835966 OBDCompliance 1;
BA_ "SPN" SG_ 2566835966 PreviouslyActiveTroubleCodes 1219;
BA_ "SigType" SG_ 2566835966 PreviouslyActiveTroubleCodes 1;
BA_ "SPN" SG_ 2566835966 ActiveTroubleCodes 1218;
BA_ "SigType" SG_ 2566835966 ActiveTroubleCodes 1;
BA_ "SPN" SG_ 2566835966 SecondAirSystemMonStatus 1223;
BA_ "SPN" SG_ 2566835966 EvaporativeSystemMonStatus 1223;
BA_ "SPN" SG_ 2566835966 ACSystemRefrigerantMonStatus 1223;
BA_ "SPN" SG_ 2566835966 OxygenSensorHeaterMonStatus 1223;
BA_ "SPN" SG_ 2566835966 OxygenSensorMonStatus 1223;
BA_ "SPN" SG_ 2566835966 EGRSystemMonitoringStatus 1223;
BA_ "SPN" SG_ 2566835966 CatalystMonStatus 1223;
BA_ "SPN" SG_ 2566835966 ColdStartAidSystemMonStatus 1223;
BA_ "SPN" SG_ 2566835966 HeatedCatalystMonStatus 1223;
BA_ "SPN" SG_ 2566835966 CatalystMonSupp 1222;
BA_ "SPN" SG_ 2566835966 ColdStartAidSystemMonSupp 1222;
BA_ "SPN" SG_ 2566835966 HeatedCatalystMonSupp 1222;
BA_ "SPN" SG_ 2566835966 EvaporativeSystemMonSupp 1222;
BA_ "SPN" SG_ 2566835966 SecondAirSystemMonSupp 1222;
BA_ "SPN" SG_ 2566835966 ACSystemRefrigerantMonSupp 1222;
BA_ "SPN" SG_ 2566835966 OxygenSensorMonSupp 1222;
BA_ "SPN" SG_ 2566835966 OxygenSensorHeaterMonSupp 1222;
BA_ "SPN" SG_ 2566835966 EGRSystemMonitoringSupp 1222;
BA_ "SPN" SG_ 2566835966 MisfireMonitoringStatus 1221;
BA_ "SPN" SG_ 2566835966 ComprehensiveCompMonStatus 1221;
BA_ "SPN" SG_ 2566835966 FuelSystemMonitoringStatus 1221;
BA_ "SPN" SG_ 2566835966 ComprehensiveComponentMonSupp 1221;
BA_ "SPN" SG_ 2566835966 FuelSystemMonitoringSupport 1221;
BA_ "SPN" SG_ 2566835710 EngIntakeManifold1Press 102;
BA_ "SigType" SG_ 2566835710 EngIntakeManifold1Press 1;
BA_ "SPN" SG_ 2566835710 FreezeFrameLength 1217;
BA_ "SPN" SG_ 2566835710 EngSpeed 190;
BA_ "SigType" SG_ 2566835710 EngSpeed 1;
BA_ "SPN" SG_ 2566835710 EngTorqueMode 899;
BA_ "SigType" SG_ 2566835710 EngTorqueMode 4;
BA_ "SPN" SG_ 2566835710 WheelBasedVehicleSpeed 84;
BA_ "SigType" SG_ 2566835710 WheelBasedVehicleSpeed 1;
BA_ "SPN" SG_ 2566835710 EngPercentLoadAtCurrentSpeed 92;
BA_ "SigType" SG_ 2566835710 EngPercentLoadAtCurrentSpeed 1;
BA_ "SPN" SG_ 2566835710 EngineCoolantTemperature 110;
BA_ "SigType" SG_ 2566835710 EngineCoolantTemperature 1;
BA_ "SigType" SG_ 2566835710 DTC1 7;
BA_ "SPN" SG_ 2566764542 ExpandedFreezeFrameLength 3149;
BA_ "SigType" SG_ 2566764542 DTC1 7;
BA_ "SPN" SG_ 2566764286 SPNSupported1High 3146;
BA_ "SPN" SG_ 2566764286 SPNSupported3High 3146;
BA_ "SPN" SG_ 2566764286 SPNSupported2High 3146;
BA_ "SPN" SG_ 2566764286 SPNSupported3 3146;
BA_ "SPN" SG_ 2566764286 SPNSupported2 3146;
BA_ "SPN" SG_ 2566764286 SPNDataLength3 3148;
BA_ "SPN" SG_ 2566764286 SPNDataLength2 3148;
BA_ "SPN" SG_ 2566764286 SPNDataLength1 3148;
BA_ "SPN" SG_ 2566764286 SPNSupported1 3146;
BA_ "SPN" SG_ 2566764030 FlashRedStopLamp 3039;
BA_ "SigType" SG_ 2566764030 FlashRedStopLamp 4;
BA_ "SPN" SG_ 2566764030 FlashProtectLamp 3041;
BA_ "SigType" SG_ 2566764030 FlashProtectLamp 4;
BA_ "SPN" SG_ 2566764030 FlashMalfuncIndicatorLamp 3038;
BA_ "SigType" SG_ 2566764030 FlashMalfuncIndicatorLamp 4;
BA_ "SPN" SG_ 2566764030 FlashAmberWarningLamp 3040;
BA_ "SigType" SG_ 2566764030 FlashAmberWarningLamp 4;
BA_ "SPN" SG_ 2566764030 MalfunctionIndicatorLampStatus 1213;
BA_ "SigType" SG_ 2566764030 MalfunctionIndicatorLampStatus 4;
BA_ "SPN" SG_ 2566764030 RedStopLampState 623;
BA_ "SigType" SG_ 2566764030 RedStopLampState 4;
BA_ "SPN" SG_ 2566764030 AmberWarningLampStatus 624;
BA_ "SigType" SG_ 2566764030 AmberWarningLampStatus 4;
BA_ "SPN" SG_ 2566764030 ProtectLampStatus 987;
BA_ "SigType" SG_ 2566764030 ProtectLampStatus 4;
BA_ "SigType" SG_ 2566764030 DTC5 7;
BA_ "SigType" SG_ 2566764030 DTC4 7;
BA_ "SigType" SG_ 2566764030 DTC3 7;
BA_ "SigType" SG_ 2566764030 DTC2 7;
BA_ "SigType" SG_ 2566764030 DTC1 7;
BA_ "SPN" SG_ 2562981630 IndividualDTCClearControlByte 3034;
BA_ "SPN" SG_ 2562981630 CtrlByteIndicIndividualDTCClear 3035;
BA_ "SPN" SG_ 2562981630 SPN1 1214;
BA_ "SPN" SG_ 2562981630 SPN1High 1214;
BA_ "SPN" SG_ 2562981630 FailureModeIdentifier1 1215;
BA_ "SPN" SG_ 2562850558 TimeSinceDTCsCleared 3145;
BA_ "SigType" SG_ 2562850558 TimeSinceDTCsCleared 1;
BA_ "SPN" SG_ 2562850558 MinutesRunByEngineMILActivated 3144;
BA_ "SigType" SG_ 2562850558 MinutesRunByEngineMILActivated 1;
BA_ "SPN" SG_ 2562850558 DistanceSinceDTCsCleared 3143;
BA_ "SigType" SG_ 2562850558 DistanceSinceDTCsCleared 1;
BA_ "SPN" SG_ 2562850558 DistanceWhileMILisActivated 3069;
BA_ "SigType" SG_ 2562850558 DistanceWhileMILisActivated 1;
BA_ "SPN" SG_ 2562916094 ApplSysMonitorDenominator 3068;
BA_ "SigType" SG_ 2562916094 ApplSysMonitorDenominator 1;
BA_ "SPN" SG_ 2562916094 ApplSysMonitorNumerator 3067;
BA_ "SigType" SG_ 2562916094 ApplSysMonitorNumerator 1;
BA_ "SPN" SG_ 2562916094 SPNofApplSysMonitor 3066;
BA_ "SigType" SG_ 2562916094 SPNofApplSysMonitor 1;
BA_ "SPN" SG_ 2562916094 OBDMonitoringCondEncountered 3049;
BA_ "SigType" SG_ 2562916094 OBDMonitoringCondEncountered 1;
BA_ "SPN" SG_ 2562916094 IgnitionCycleCounter 3048;
BA_ "SigType" SG_ 2562916094 IgnitionCycleCounter 1;
BA_ "SPN" SG_ 2566835198 MalfunctionIndicatorLampStatus 1213;
BA_ "SigType" SG_ 2566835198 MalfunctionIndicatorLampStatus 4;
BA_ "SPN" SG_ 2566835198 RedStopLampState 623;
BA_ "SigType" SG_ 2566835198 RedStopLampState 4;
BA_ "SPN" SG_ 2566835198 AmberWarningLampStatus 624;
BA_ "SigType" SG_ 2566835198 AmberWarningLampStatus 4;
BA_ "SPN" SG_ 2566835198 ProtectLampStatus 987;
BA_ "SigType" SG_ 2566835198 ProtectLampStatus 4;
BA_ "SPN" SG_ 2566835198 FlashRedStopLamp 3039;
BA_ "SigType" SG_ 2566835198 FlashRedStopLamp 4;
BA_ "SPN" SG_ 2566835198 FlashProtectLamp 3041;
BA_ "SigType" SG_ 2566835198 FlashProtectLamp 4;
BA_ "SPN" SG_ 2566835198 FlashMalfuncIndicatorLamp 3038;
BA_ "SigType" SG_ 2566835198 FlashMalfuncIndicatorLamp 4;
BA_ "SPN" SG_ 2566835198 FlashAmberWarningLamp 3040;
BA_ "SigType" SG_ 2566835198 FlashAmberWarningLamp 4;
BA_ "SigType" SG_ 2566835198 DTC5 7;
BA_ "SigType" SG_ 2566835198 DTC4 7;
BA_ "SigType" SG_ 2566835198 DTC3 7;
BA_ "SigType" SG_ 2566835198 DTC2 7;
BA_ "SigType" SG_ 2566835198 DTC1 7;
BA_ "SPN" SG_ 2564030206 CalibrationID4 1635;
BA_ "SPN" SG_ 2564030206 CalibrationID3 1635;
BA_ "SPN" SG_ 2564030206 CalibrationID2 1635;
BA_ "SPN" SG_ 2564030206 CalibrationID1 1635;
BA_ "SPN" SG_ 2564030206 CalibrationVerificationNumber 1634;
BA_ "SigType" SG_ 2564030206 CalibrationVerificationNumber 1;
BA_ "SPN" SG_ 2564423422 KeyOrUserLevel 1645;
BA_ "SPN" SG_ 2564423422 PointerExtension 1643;
BA_ "SPN" SG_ 2564423422 Pointer 1644;
BA_ "SPN" SG_ 2564423422 Command 1642;
BA_ "SPN" SG_ 2564423422 PointerType 1641;
BA_ "SPN" SG_ 2564423422 NumberRequested 1640;
BA_ "SPN" SG_ 2564423422 NumberRequestedHigh 1640;
BA_ "SPN" SG_ 2564816638 HoldSignal 1236;
BA_ "SPN" SG_ 2564816638 J1939Network3 1235;
BA_ "SigType" SG_ 2564816638 J1939Network3 4;
BA_ "SPN" SG_ 2564816638 J1939Network2 1231;
BA_ "SigType" SG_ 2564816638 J1939Network2 4;
BA_ "SPN" SG_ 2564816638 ISO9141 1232;
BA_ "SigType" SG_ 2564816638 ISO9141 4;
BA_ "SPN" SG_ 2564816638 SAE_J1850 1233;
BA_ "SigType" SG_ 2564816638 SAE_J1850 4;
BA_ "SPN" SG_ 2564816638 ManufacturerSpecificPort 1234;
BA_ "SigType" SG_ 2564816638 ManufacturerSpecificPort 4;
BA_ "SPN" SG_ 2564816638 CurrentDataLink 1230;
BA_ "SigType" SG_ 2564816638 CurrentDataLink 4;
BA_ "SPN" SG_ 2564816638 SAE_J1587 608;
BA_ "SigType" SG_ 2564816638 SAE_J1587 4;
BA_ "SPN" SG_ 2564816638 SAE_J1922 622;
BA_ "SigType" SG_ 2564816638 SAE_J1922 4;
BA_ "SPN" SG_ 2564816638 J1939Network1 639;
BA_ "SigType" SG_ 2564816638 J1939Network1 4;
BA_ "SPN" SG_ 2564816638 SuspendSignal 2618;
BA_ "SPN" SG_ 2564816638 SuspendDuration 2619;
BA_ "SPN" SG_ 2566837502 FlashRedStopLamp 3039;
BA_ "SigType" SG_ 2566837502 FlashRedStopLamp 4;
BA_ "SPN" SG_ 2566837502 FlashProtectLamp 3041;
BA_ "SigType" SG_ 2566837502 FlashProtectLamp 4;
BA_ "SPN" SG_ 2566837502 MalfunctionIndicatorLampStatus 1213;
BA_ "SigType" SG_ 2566837502 MalfunctionIndicatorLampStatus 4;
BA_ "SPN" SG_ 2566837502 RedStopLampState 623;
BA_ "SigType" SG_ 2566837502 RedStopLampState 4;
BA_ "SPN" SG_ 2566837502 AmberWarningLampStatus 624;
BA_ "SigType" SG_ 2566837502 AmberWarningLampStatus 4;
BA_ "SPN" SG_ 2566837502 ProtectLampStatus 987;
BA_ "SigType" SG_ 2566837502 ProtectLampStatus 4;
BA_ "SPN" SG_ 2566837502 FlashMalfuncIndicatorLamp 3038;
BA_ "SigType" SG_ 2566837502 FlashMalfuncIndicatorLamp 4;
BA_ "SPN" SG_ 2566837502 FlashAmberWarningLamp 3040;
BA_ "SigType" SG_ 2566837502 FlashAmberWarningLamp 4;
BA_ "SigType" SG_ 2566837502 DTC5 7;
BA_ "SigType" SG_ 2566837502 DTC4 7;
BA_ "SigType" SG_ 2566837502 DTC3 7;
BA_ "SigType" SG_ 2566837502 DTC2 7;
BA_ "SigType" SG_ 2566837502 DTC1 7;
BA_ "SPN" SG_ 2566836990 TestIdentifierSupported 1229;
BA_ "GenSigStartValue" SG_ 2566836990 TestIdentifierSupported 1;
BA_ "SigType" SG_ 2566836990 TestIdentifierSupported 1;
BA_ "SPN" SG_ 2566834942 FlashRedStopLamp 3039;
BA_ "SigType" SG_ 2566834942 FlashRedStopLamp 4;
BA_ "SPN" SG_ 2566834942 FlashProtectLamp 3041;
BA_ "SigType" SG_ 2566834942 FlashProtectLamp 4;
BA_ "SPN" SG_ 2566834942 FlashMalfuncIndicatorLamp 3038;
BA_ "SigType" SG_ 2566834942 FlashMalfuncIndicatorLamp 4;
BA_ "SPN" SG_ 2566834942 FlashAmberWarningLamp 3040;
BA_ "SigType" SG_ 2566834942 FlashAmberWarningLamp 4;
BA_ "SPN" SG_ 2566834942 MalfunctionIndicatorLampStatus 1213;
BA_ "SigType" SG_ 2566834942 MalfunctionIndicatorLampStatus 4;
BA_ "SPN" SG_ 2566834942 AmberWarningLampStatus 624;
BA_ "SigType" SG_ 2566834942 AmberWarningLampStatus 4;
BA_ "SPN" SG_ 2566834942 RedStopLampState 623;
BA_ "SigType" SG_ 2566834942 RedStopLampState 4;
BA_ "SPN" SG_ 2566834942 ProtectLampStatus 987;
BA_ "SigType" SG_ 2566834942 ProtectLampStatus 4;
BA_ "SigType" SG_ 2566834942 DTC5 7;
BA_ "SigType" SG_ 2566834942 DTC4 7;
BA_ "SigType" SG_ 2566834942 DTC3 7;
BA_ "SigType" SG_ 2566834942 DTC2 7;
BA_ "SigType" SG_ 2566834942 DTC1 7;
BA_ "SPN" SG_ 2566780926 UtlityOverallPowerFactorLagging 2522;
BA_ "SigType" SG_ 2566780926 UtlityOverallPowerFactorLagging 4;
BA_ "SPN" SG_ 2566780926 UtilityOverallPowerFactor 2498;
BA_ "SigType" SG_ 2566780926 UtilityOverallPowerFactor 1;
BA_ "SPN" SG_ 2566780926 UtilityTotalReactivePower 2490;
BA_ "SigType" SG_ 2566780926 UtilityTotalReactivePower 1;
BA_ "SPN" SG_ 2566781182 UtilityTotalApparentPower 2494;
BA_ "SigType" SG_ 2566781182 UtilityTotalApparentPower 1;
BA_ "SPN" SG_ 2566781182 UtilityTotalRealPower 2486;
BA_ "SigType" SG_ 2566781182 UtilityTotalRealPower 1;
BA_ "SPN" SG_ 2566778366 UtilityTotalKWHoursImport 2503;
BA_ "SigType" SG_ 2566778366 UtilityTotalKWHoursImport 4;
BA_ "SPN" SG_ 2566778366 UtilityTotalKWHoursExport 2502;
BA_ "SigType" SG_ 2566778366 UtilityTotalKWHoursExport 4;
BA_ "SPN" SG_ 2566778622 UtilityPhaseCPowerFactorLagging 2525;
BA_ "SigType" SG_ 2566778622 UtilityPhaseCPowerFactorLagging 4;
BA_ "SPN" SG_ 2566778622 UtilityPhaseCPowerFactor 2501;
BA_ "SigType" SG_ 2566778622 UtilityPhaseCPowerFactor 1;
BA_ "SPN" SG_ 2566778622 UtilityPhaseCReactivePower 2493;
BA_ "SigType" SG_ 2566778622 UtilityPhaseCReactivePower 1;
BA_ "SPN" SG_ 2566778878 UtilityPhaseCApparentPower 2497;
BA_ "SigType" SG_ 2566778878 UtilityPhaseCApparentPower 1;
BA_ "SPN" SG_ 2566778878 UtilityPhaseCRealPower 2489;
BA_ "SigType" SG_ 2566778878 UtilityPhaseCRealPower 1;
BA_ "SPN" SG_ 2566779134 UtilityPhaseCACRMSCurrent 2485;
BA_ "SigType" SG_ 2566779134 UtilityPhaseCACRMSCurrent 1;
BA_ "SPN" SG_ 2566779134 UtilityPhaseCACFrequency 2473;
BA_ "SigType" SG_ 2566779134 UtilityPhaseCACFrequency 1;
BA_ "SPN" SG_ 2566779134 UtltyPhsCLneNeutralACRMSVoltage 2481;
BA_ "SigType" SG_ 2566779134 UtltyPhsCLneNeutralACRMSVoltage 1;
BA_ "SPN" SG_ 2566779134 UtltyPhseCALineLineACRMSVoltage 2477;
BA_ "SigType" SG_ 2566779134 UtltyPhseCALineLineACRMSVoltage 1;
BA_ "SPN" SG_ 2566779390 UtilityPhaseBPowerFactorLagging 2524;
BA_ "SigType" SG_ 2566779390 UtilityPhaseBPowerFactorLagging 4;
BA_ "SPN" SG_ 2566779390 UtilityPhaseBPowerFactor 2500;
BA_ "SigType" SG_ 2566779390 UtilityPhaseBPowerFactor 1;
BA_ "SPN" SG_ 2566779390 UtilityPhaseBReactivePower 2492;
BA_ "SigType" SG_ 2566779390 UtilityPhaseBReactivePower 1;
BA_ "SPN" SG_ 2566779646 UtilityPhaseBApparentPower 2496;
BA_ "SigType" SG_ 2566779646 UtilityPhaseBApparentPower 1;
BA_ "SPN" SG_ 2566779646 UtilityPhaseBRealPower 2488;
BA_ "SigType" SG_ 2566779646 UtilityPhaseBRealPower 1;
BA_ "SPN" SG_ 2566779902 UtilityPhaseBACRMSCurrent 2484;
BA_ "SigType" SG_ 2566779902 UtilityPhaseBACRMSCurrent 1;
BA_ "SPN" SG_ 2566779902 UtilityPhaseBACFrequency 2472;
BA_ "SigType" SG_ 2566779902 UtilityPhaseBACFrequency 1;
BA_ "SPN" SG_ 2566779902 UtltyPhsBLneNeutralACRMSVoltage 2480;
BA_ "SigType" SG_ 2566779902 UtltyPhsBLneNeutralACRMSVoltage 1;
BA_ "SPN" SG_ 2566779902 UtltyPhseBCLineLineACRMSVoltage 2476;
BA_ "SigType" SG_ 2566779902 UtltyPhseBCLineLineACRMSVoltage 1;
BA_ "SPN" SG_ 2566780158 UtilityPhaseAPowerFactorLagging 2523;
BA_ "SigType" SG_ 2566780158 UtilityPhaseAPowerFactorLagging 4;
BA_ "SPN" SG_ 2566780158 UtilityPhaseAPowerFactor 2499;
BA_ "SigType" SG_ 2566780158 UtilityPhaseAPowerFactor 1;
BA_ "SPN" SG_ 2566780158 UtilityPhaseAReactivePower 2491;
BA_ "SigType" SG_ 2566780158 UtilityPhaseAReactivePower 1;
BA_ "SPN" SG_ 2566780414 UtilityPhaseAApparentPower 2495;
BA_ "SigType" SG_ 2566780414 UtilityPhaseAApparentPower 1;
BA_ "SPN" SG_ 2566780414 UtilityPhaseARealPower 2487;
BA_ "SigType" SG_ 2566780414 UtilityPhaseARealPower 1;
BA_ "SPN" SG_ 2566780670 UtilityPhaseAACRMSCurrent 2483;
BA_ "SigType" SG_ 2566780670 UtilityPhaseAACRMSCurrent 1;
BA_ "SPN" SG_ 2566780670 UtilityPhaseAACFrequency 2471;
BA_ "SigType" SG_ 2566780670 UtilityPhaseAACFrequency 1;
BA_ "SPN" SG_ 2566780670 UtltyPhsALneNeutralACRMSVoltage 2479;
BA_ "SigType" SG_ 2566780670 UtltyPhsALneNeutralACRMSVoltage 1;
BA_ "SPN" SG_ 2566780670 UtltyPhseABLineLineACRMSVoltage 2475;
BA_ "SigType" SG_ 2566780670 UtltyPhseABLineLineACRMSVoltage 1;
BA_ "SPN" SG_ 2566781438 UtilityAverageACRMSCurrent 2482;
BA_ "SigType" SG_ 2566781438 UtilityAverageACRMSCurrent 1;
BA_ "SPN" SG_ 2566781438 UtilityAverageACFrequency 2470;
BA_ "SigType" SG_ 2566781438 UtilityAverageACFrequency 1;
BA_ "SPN" SG_ 2566781438 UtltyAvrgLneNeutralACRMSVoltage 2478;
BA_ "SigType" SG_ 2566781438 UtltyAvrgLneNeutralACRMSVoltage 1;
BA_ "SPN" SG_ 2566781438 UtltyAvrageLineLineACRMSVoltage 2474;
BA_ "SigType" SG_ 2566781438 UtltyAvrageLineLineACRMSVoltage 1;
BA_ "SPN" SG_ 2566784254 GnrtorOverallPowerFactorLagging 2518;
BA_ "SigType" SG_ 2566784254 GnrtorOverallPowerFactorLagging 4;
BA_ "SPN" SG_ 2566784254 GeneratorOverallPowerFactor 2464;
BA_ "SigType" SG_ 2566784254 GeneratorOverallPowerFactor 1;
BA_ "SPN" SG_ 2566784254 GeneratorTotalReactivePower 2456;
BA_ "SigType" SG_ 2566784254 GeneratorTotalReactivePower 1;
BA_ "SPN" SG_ 2566784510 GeneratorTotalApparentPower 2460;
BA_ "SigType" SG_ 2566784510 GeneratorTotalApparentPower 1;
BA_ "SPN" SG_ 2566784510 GeneratorTotalRealPower 2452;
BA_ "SigType" SG_ 2566784510 GeneratorTotalRealPower 1;
BA_ "SPN" SG_ 2566781694 GeneratorTotalKWHoursImport 2469;
BA_ "SigType" SG_ 2566781694 GeneratorTotalKWHoursImport 4;
BA_ "SPN" SG_ 2566781694 GeneratorTotalKWHoursExport 2468;
BA_ "SigType" SG_ 2566781694 GeneratorTotalKWHoursExport 4;
BA_ "SPN" SG_ 2566781950 GnratorPhaseCPowerFactorLagging 2521;
BA_ "SigType" SG_ 2566781950 GnratorPhaseCPowerFactorLagging 4;
BA_ "SPN" SG_ 2566781950 GeneratorPhaseCPowerFactor 2467;
BA_ "SigType" SG_ 2566781950 GeneratorPhaseCPowerFactor 1;
BA_ "SPN" SG_ 2566781950 GeneratorPhaseCReactivePower 2459;
BA_ "SigType" SG_ 2566781950 GeneratorPhaseCReactivePower 1;
BA_ "SPN" SG_ 2566782206 GeneratorPhaseCApparentPower 2463;
BA_ "SigType" SG_ 2566782206 GeneratorPhaseCApparentPower 1;
BA_ "SPN" SG_ 2566782206 GeneratorPhaseCRealPower 2455;
BA_ "SigType" SG_ 2566782206 GeneratorPhaseCRealPower 1;
BA_ "SPN" SG_ 2566782462 GeneratorPhaseCACRMSCurrent 2451;
BA_ "SigType" SG_ 2566782462 GeneratorPhaseCACRMSCurrent 1;
BA_ "SPN" SG_ 2566782462 GeneratorPhaseCACFrequency 2439;
BA_ "SigType" SG_ 2566782462 GeneratorPhaseCACFrequency 1;
BA_ "SPN" SG_ 2566782462 GnrtrPhsCLneNeutralACRMSVoltage 2447;
BA_ "SigType" SG_ 2566782462 GnrtrPhsCLneNeutralACRMSVoltage 1;
BA_ "SPN" SG_ 2566782462 GnrtrPhseCALineLineACRMSVoltage 2443;
BA_ "SigType" SG_ 2566782462 GnrtrPhseCALineLineACRMSVoltage 1;
BA_ "SPN" SG_ 2566782718 GnratorPhaseBPowerFactorLagging 2520;
BA_ "SigType" SG_ 2566782718 GnratorPhaseBPowerFactorLagging 4;
BA_ "SPN" SG_ 2566782718 GeneratorPhaseBPowerFactor 2466;
BA_ "SigType" SG_ 2566782718 GeneratorPhaseBPowerFactor 1;
BA_ "SPN" SG_ 2566782718 GeneratorPhaseBReactivePower 2458;
BA_ "SigType" SG_ 2566782718 GeneratorPhaseBReactivePower 1;
BA_ "SPN" SG_ 2566782974 GeneratorPhaseBApparentPower 2462;
BA_ "SigType" SG_ 2566782974 GeneratorPhaseBApparentPower 1;
BA_ "SPN" SG_ 2566782974 GeneratorPhaseBRealPower 2454;
BA_ "SigType" SG_ 2566782974 GeneratorPhaseBRealPower 1;
BA_ "SPN" SG_ 2566783230 GeneratorPhaseBACRMSCurrent 2450;
BA_ "SigType" SG_ 2566783230 GeneratorPhaseBACRMSCurrent 1;
BA_ "SPN" SG_ 2566783230 GeneratorPhaseBACFrequency 2438;
BA_ "SigType" SG_ 2566783230 GeneratorPhaseBACFrequency 1;
BA_ "SPN" SG_ 2566783230 GnrtrPhsBLneNeutralACRMSVoltage 2446;
BA_ "SigType" SG_ 2566783230 GnrtrPhsBLneNeutralACRMSVoltage 1;
BA_ "SPN" SG_ 2566783230 GnrtrPhseBCLineLineACRMSVoltage 2442;
BA_ "SigType" SG_ 2566783230 GnrtrPhseBCLineLineACRMSVoltage 1;
BA_ "SPN" SG_ 2566783486 GnratorPhaseAPowerFactorLagging 2519;
BA_ "SigType" SG_ 2566783486 GnratorPhaseAPowerFactorLagging 4;
BA_ "SPN" SG_ 2566783486 GeneratorPhaseAPowerFactor 2465;
BA_ "SigType" SG_ 2566783486 GeneratorPhaseAPowerFactor 1;
BA_ "SPN" SG_ 2566783486 GeneratorPhaseAReactivePower 2457;
BA_ "SigType" SG_ 2566783486 GeneratorPhaseAReactivePower 1;
BA_ "SPN" SG_ 2566783742 GeneratorPhaseAApparentPower 2461;
BA_ "SigType" SG_ 2566783742 GeneratorPhaseAApparentPower 1;
BA_ "SPN" SG_ 2566783742 GeneratorPhaseARealPower 2453;
BA_ "SigType" SG_ 2566783742 GeneratorPhaseARealPower 1;
BA_ "SPN" SG_ 2566783998 GeneratorPhaseAACRMSCurrent 2449;
BA_ "SigType" SG_ 2566783998 GeneratorPhaseAACRMSCurrent 1;
BA_ "SPN" SG_ 2566783998 GeneratorPhaseAACFrequency 2437;
BA_ "SigType" SG_ 2566783998 GeneratorPhaseAACFrequency 1;
BA_ "SPN" SG_ 2566783998 GnrtrPhsALneNeutralACRMSVoltage 2445;
BA_ "SigType" SG_ 2566783998 GnrtrPhsALneNeutralACRMSVoltage 1;
BA_ "SPN" SG_ 2566783998 GnrtrPhseABLineLineACRMSVoltage 2441;
BA_ "SigType" SG_ 2566783998 GnrtrPhseABLineLineACRMSVoltage 1;
BA_ "SPN" SG_ 2566784766 GeneratorAverageACRMSCurrent 2448;
BA_ "SigType" SG_ 2566784766 GeneratorAverageACRMSCurrent 1;
BA_ "SPN" SG_ 2566784766 GeneratorAverageACFrequency 2436;
BA_ "SigType" SG_ 2566784766 GeneratorAverageACFrequency 1;
BA_ "SPN" SG_ 2566784766 GnrtrAvrgLneNeutralACRMSVoltage 2444;
BA_ "SigType" SG_ 2566784766 GnrtrAvrgLneNeutralACRMSVoltage 1;
BA_ "SPN" SG_ 2566784766 GnrtrAvrageLineLineACRMSVoltage 2440;
BA_ "SigType" SG_ 2566784766 GnrtrAvrageLineLineACRMSVoltage 1;
BA_ "SPN" SG_ 2566776830 Bus1_UtilityACPhaseDifference 2517;
BA_ "SigType" SG_ 2566776830 Bus1_UtilityACPhaseDifference 1;
BA_ "SPN" SG_ 2566776830 Bus1_UtilityInSync 2534;
BA_ "SigType" SG_ 2566776830 Bus1_UtilityInSync 4;
BA_ "SPN" SG_ 2566776830 Bus1_UtilityVoltageMatch 2532;
BA_ "SigType" SG_ 2566776830 Bus1_UtilityVoltageMatch 4;
BA_ "SPN" SG_ 2566776830 Bus1_UtilityFrequencyMatch 2533;
BA_ "SigType" SG_ 2566776830 Bus1_UtilityFrequencyMatch 4;
BA_ "SPN" SG_ 2566776830 Bus1_UtilityPhaseMatch 2531;
BA_ "SigType" SG_ 2566776830 Bus1_UtilityPhaseMatch 4;
BA_ "SPN" SG_ 2566776830 Bus1_UtilityDeadBus 2535;
BA_ "SigType" SG_ 2566776830 Bus1_UtilityDeadBus 4;
BA_ "SPN" SG_ 2566777342 Bus1PhaseCACFrequency 2507;
BA_ "SigType" SG_ 2566777342 Bus1PhaseCACFrequency 1;
BA_ "SPN" SG_ 2566777342 Bs1PhseCLineNeutralACRMSVoltage 2515;
BA_ "SigType" SG_ 2566777342 Bs1PhseCLineNeutralACRMSVoltage 1;
BA_ "SPN" SG_ 2566777342 Bus1PhaseCALineLineACRMSVoltage 2511;
BA_ "SigType" SG_ 2566777342 Bus1PhaseCALineLineACRMSVoltage 1;
BA_ "SPN" SG_ 2566777598 Bus1PhaseBACFrequency 2506;
BA_ "SigType" SG_ 2566777598 Bus1PhaseBACFrequency 1;
BA_ "SPN" SG_ 2566777598 Bs1PhseBLineNeutralACRMSVoltage 2514;
BA_ "SigType" SG_ 2566777598 Bs1PhseBLineNeutralACRMSVoltage 1;
BA_ "SPN" SG_ 2566777598 Bus1PhaseBCLineLineACRMSVoltage 2510;
BA_ "SigType" SG_ 2566777598 Bus1PhaseBCLineLineACRMSVoltage 1;
BA_ "SPN" SG_ 2566777854 Bus1PhaseAACFrequency 2505;
BA_ "SigType" SG_ 2566777854 Bus1PhaseAACFrequency 1;
BA_ "SPN" SG_ 2566777854 Bs1PhseALineNeutralACRMSVoltage 2513;
BA_ "SigType" SG_ 2566777854 Bs1PhseALineNeutralACRMSVoltage 1;
BA_ "SPN" SG_ 2566777854 Bus1PhaseABLineLineACRMSVoltage 2509;
BA_ "SigType" SG_ 2566777854 Bus1PhaseABLineLineACRMSVoltage 1;
BA_ "SPN" SG_ 2566777086 Bus1_GeneratorACPhaseDifference 2516;
BA_ "SigType" SG_ 2566777086 Bus1_GeneratorACPhaseDifference 1;
BA_ "SPN" SG_ 2566777086 Bus1_GeneratorInSync 2529;
BA_ "SigType" SG_ 2566777086 Bus1_GeneratorInSync 4;
BA_ "SPN" SG_ 2566777086 Bus1_GeneratorVoltageMatch 2527;
BA_ "SigType" SG_ 2566777086 Bus1_GeneratorVoltageMatch 4;
BA_ "SPN" SG_ 2566777086 Bus1_GeneratorFrequencyMatch 2528;
BA_ "SigType" SG_ 2566777086 Bus1_GeneratorFrequencyMatch 4;
BA_ "SPN" SG_ 2566777086 Bus1_GeneratorPhaseMatch 2526;
BA_ "SigType" SG_ 2566777086 Bus1_GeneratorPhaseMatch 4;
BA_ "SPN" SG_ 2566777086 Bus1_GeneratorDeadBus 2530;
BA_ "SigType" SG_ 2566777086 Bus1_GeneratorDeadBus 4;
BA_ "SPN" SG_ 2566778110 Bus1AverageACFrequency 2504;
BA_ "SigType" SG_ 2566778110 Bus1AverageACFrequency 1;
BA_ "SPN" SG_ 2566778110 Bs1AvrgeLineNeutralACRMSVoltage 2512;
BA_ "SigType" SG_ 2566778110 Bs1AvrgeLineNeutralACRMSVoltage 1;
BA_ "SPN" SG_ 2566778110 Bus1AverageLineLineACRMSVoltage 2508;
BA_ "SigType" SG_ 2566778110 Bus1AverageLineLineACRMSVoltage 1;
BA_ "SigType" SG_ 2633895422 NumberOfMembers 3;
BA_ "SPN" SG_ 2566838526 AddressAssignment 2847;
BA_ "SigType" SG_ 2566838526 AddressAssignment 1;
BA_ "SigType" SG_ 2566838526 ManufacturerCode 1;
BA_ "SigType" SG_ 2565799678 ManufacturerCode 1;
BA_ "SPN" SG_ 2563440382 ShrtNameOfActualReportingDevice 2554;
BA_ "SigType" SG_ 2563440382 ShrtNameOfActualReportingDevice 4;
BA_ "SPN" SG_ 2563440382 LengthOfDataForTheReportedPGN 2553;
BA_ "SigType" SG_ 2563440382 LengthOfDataForTheReportedPGN 1;
BA_ "SPN" SG_ 2563440382 PGNofRequstedInformation 2552;
BA_ "SigType" SG_ 2563440382 PGNofRequstedInformation 6;
BA_ "SPN" SG_ 2632711934 SequenceNumber 2572;
BA_ "SPN" SG_ 2632777470 TotalNumberOfPacketsEoMA 2558;
BA_ "SPN" SG_ 2632777470 TotalMessageSizeEoMA 2557;
BA_ "SPN" SG_ 2632777470 TotalMessageSizeBAM 2557;
BA_ "SPN" SG_ 2632777470 TotalNumberOfPacketsBAM 2558;
BA_ "SPN" SG_ 2632777470 ConnectionAbortReason 2570;
BA_ "SPN" SG_ 2632777470 NextPacketNumberToBeSent 2562;
BA_ "SPN" SG_ 2632777470 NumberOfPacketsThatCanBeSent 2561;
BA_ "SPN" SG_ 2632777470 PGNumber 2560;
BA_ "SigType" SG_ 2632777470 PGNumber 6;
BA_ "SPN" SG_ 2632777470 MaximumNumberOfPackets 2559;
BA_ "SPN" SG_ 2632777470 TotalNumberOfPackets 2558;
BA_ "SPN" SG_ 2632777470 TotalMessageSize 2557;
BA_ "SPN" SG_ 2632777470 ControlByte 2556;
BA_ "SPN" SG_ 2563374846 UseTransferMode 2575;
BA_ "SigType" SG_ 2563374846 UseTransferMode 4;
BA_ "SPN" SG_ 2563374846 ParameterGroupNumber 2574;
BA_ "SigType" SG_ 2563374846 ParameterGroupNumber 6;
VAL_ 2566758654 Aftrtrtmnt2FlInjctor1HeaterCtrl 4 "Max" ;
VAL_ 2566758654 Aftrtratment2FuelEnableActuator 3 "notAvailable" 2 "reservedForSAEAssignment" 1 "active" 0 "notActive" ;
VAL_ 2566758654 Aftrtratment2RegenerationStatus 3 "notAvailable" 2 "reservedForSAEAssignment" 1 "active" 0 "notActive" ;
VAL_ 2566758654 Aftertreatment2Ignt 3 "notAvailable" 2 "reservedForSAEAssignment" 1 "active" 0 "notActive" ;
VAL_ 2566758654 Aftrtreatment2FuelDrainActuator 3 "notAvailable" 2 "reservedForSAEAssignment" 1 "active" 0 "notActive" ;
VAL_ 2565869822 Aftrtrtmnt2IntkGsSnsrPwerStatus 3 "NotAvailable" 2 "Error" 1 "InRange" 0 "NotInRange" ;
VAL_ 2565869822 Aftrtrtmnt2IntkGsSnsrHeaterCtrl 3 "HeaterOff" 2 "Preheat1" 1 "Preheat2" 0 "Automatic" ;
VAL_ 2565869822 Aftrtrtmnt2IntkWdRngO2RdngStble 3 "NotAvailable" 2 "Error" 1 "Stable" 0 "NotStable" ;
VAL_ 2565869822 Aftrtrtmnt2IntkNOxReadingStable 3 "NotAvailable" 2 "Error" 1 "Stable" 0 "NotStable" ;
VAL_ 2565869822 Aftrtrtmnt2IntkeGasSensorAtTemp 3 "NotAvailable" 2 "Error" 1 "InRange" 0 "NotInRange" ;
VAL_ 2565870078 Aftrtrtmnt2OtltGsSnsrPwerStatus 3 "NotAvailable" 2 "Error" 1 "InRange" 0 "NotInRange" ;
VAL_ 2565870078 Aftrtrtmnt2OtltGsSnsrHeaterCtrl 3 "HeaterOff" 2 "Preheat1" 1 "Preheat2" 0 "Automatic" ;
VAL_ 2565870078 Aftrtrtmnt2OtltWdRngO2RdngStble 3 "NotAvailable" 2 "Error" 1 "Stable" 0 "NotStable" ;
VAL_ 2565870078 Aftrtrtmnt2OtltNOxReadingStable 3 "NotAvailable" 2 "Error" 1 "Stable" 0 "NotStable" ;
VAL_ 2565870078 Aftrtrtmnt2OtletGasSensorAtTemp 3 "NotAvailable" 2 "Error" 1 "InRange" 0 "NotInRange" ;
VAL_ 2566748926 DslPrtclteFilter2AshLoadPercent 4 "LevelIsTargetAshServiceInterval" ;
VAL_ 2566748926 DslPrtcltFilter2SootLoadPercent 4 "LvlIsActvRgnerationTriggerLevel" ;
VAL_ 2566748926 Aftrtrtmnt2DslPrtcltFltrStLdRgnr 4 "IsLvlAtWhchActvDslPrtcltFltrRgn" ;
VAL_ 2365428478 EngEmergencyShutdownIndication 3 "DontCare_TakeNoAction" 2 "Reserved" 1 "On" 0 "Off" ;
VAL_ 2365428478 EngCtrlledShutdownRq 3 "DontCare_TakeNoAction" 2 "Reserved" 1 "On" 0 "Off" ;
VAL_ 2365428478 EngCoolantCirculatingPumpCtrl 3 "DontCare_TakeNoAction" 2 "Reserved" 1 "On" 0 "Off" ;
VAL_ 2365428478 EngBlock_CoolantPreheaterCtrl 3 "Unavailable" 2 "Reserved" 1 "On" 0 "Off" ;
VAL_ 2365428478 EngElctrclSystmPwrCnsrvtionCtrl 3 "Unavailable" 2 "Reserved" 1 "On" 0 "Off" ;
VAL_ 2365428478 EngOilPreheaterCtrl 3 "DontCare_TakeNoAction" 2 "Reserved" 1 "On" 0 "Off" ;
VAL_ 2365428478 EngOilPrimingPumpCtrl 3 "Unavailable" 2 "Reserved" 1 "On" 0 "Off" ;
VAL_ 2365428478 EngFuelShutoffValveLeakTestCtrl 3 "DontCare_TakeNoAction" 2 "Reserved" 1 "On" 0 "Off" ;
VAL_ 2365428478 EngFuelShutoff2Ctrl 3 "DontCare_TakeNoAction" 2 "Reserved" 1 "Closed" 0 "Open" ;
VAL_ 2365428478 EngFuelShutoff1Ctrl 3 "DontCare_TakeNoAction" 2 "Reserved" 1 "Closed" 0 "Open" ;
VAL_ 2365428478 EngFuelShutoffVentCtrl 3 "DontCare_TakeNoAction" 2 "Reserved" 1 "Open" 0 "Closed" ;
VAL_ 2365428478 FuelPumpPrimerCtrl 3 "Unavailable" 2 "Reserved" 1 "Activate" 0 "Deactivate" ;
VAL_ 2362638078 SpeedDependentLevelCtrlRq 3 "DonTCare_TakeNoAction" 2 "Reserved" 1 "Activate" 0 "Deactivate" ;
VAL_ 2362638078 PrhbtAutomaticAirSuspensionCtrl 3 "NotAvailable" 2 "ErrorIndicator" 1 "RqPrhbtAtmaticAirSuspensionCtrl" 0 "NRq01RqstPrhbtdAtmtcArSspnsnCtr" ;
VAL_ 2362638078 MemoryLevelRq 15 "DontCare" 13 "StoreMemoryLevel5" 12 "StoreMemoryLevel4" 11 "StoreMemoryLevel3" 10 "StoreMemoryLevel2" 9 "StoreMemoryLevel1" 14 "Reserved" 5 "MemoryLevel5Rq" 4 "MemoryLevel4Rq" 3 "MemoryLevel3Rq" 2 "MemoryLevel2Rq" 1 "MemoryLevel1Rq" 0 "NoMemoryLevelRq" ;
VAL_ 2362638078 AllowLevelCtrlDuringBrakingCmd 3 "DonTCare_TakeNoAction" 2 "Reserved" 1 "AllowLevelCtrlDuringBraking" 0 "DisallowLevelCtrlDuringBraking" ;
VAL_ 2362638078 ProhibitAirSuspensionCtrl 3 "NotAvailable" 2 "ErrorIndicator" 1 "RqProhibitAirSuspensionCtrl" 0 "NoRq" ;
VAL_ 2362638078 KneelingCmdRearAxle 3 "DontCare_TakeNoAction" 2 "Reserved" 1 "ActivateKneeling" 0 "DeactivateKneeling" ;
VAL_ 2362638078 KneelingCmdFrontAxle 3 "DontCare_TakeNoAction" 2 "Reserved" 1 "ActivateKneeling" 0 "DeactivateKneeling" ;
VAL_ 2362638078 LevelCtrlModeRq 15 "DontCare_TakeNoAction" 14 "Reserved" 9 "1101NotDefined" 8 "ExhaustBellows" 7 "TractionHelpLoadReduce" 6 "OptmmTrctn2IPrssAtThDrvnAxlIsCt" 5 "OptmmTrctn1IPrssAtThDrvnAxlIsCt" 4 "PrssRt2IRtBtwnThPrssrsAtThDrvnA" 3 "PrssRt1IRtBtwnThPrssrsAtThDrvnA" 2 "LdFxngIDrvnAxlIsLddTAVlDfndByTh" 1 "TrctnHlpIDrvnAxlIsLddTAMxVlGvnB" 0 "NrmlOprtnISystmPrfrmsAPrCtrlOfT" ;
VAL_ 2362638078 NominalLevelRqRearAxle 11 "1101NotDefined" 10 "LowerRq" 15 "DontCare_TakeNoAction" 14 "Reserved" 9 "RaiseRq" 8 "StopLevelChange" 7 "LowerLevel" 6 "UpperLevel" 5 "CustomerLevel" 4 "PresetLevel" 3 "NormalLevel3" 2 "NormalLevel2" 1 "NormalLevel1" 0 "NoLevelRq" ;
VAL_ 2362638078 NominalLevelRqFrontAxle 11 "1101NotDefined" 10 "LowerRq" 15 "DontCare_TakeNoAction" 14 "Reserved" 9 "RaiseRq" 8 "StopLevelChange" 7 "LowerLevel" 6 "UpperLevel" 5 "CustomerLevel" 4 "PresetLevel" 3 "NormalLevel3" 2 "NormalLevel2" 1 "NormalLevel1" 0 "NoLevelRq" ;
VAL_ 2362638078 KneelingCtrlModeRq 3 "DontCare_TakeNoAction" 2 "Reserved" 1 "ManuallyActuated" 0 "AutomaticallyActuated" ;
VAL_ 2362638078 KneelingRqRightSide 3 "DontCare_TakeNoAction" 2 "Reserved" 1 "KneelingRq" 0 "NoKneelingRq" ;
VAL_ 2362638078 KneelingRqLeftSide 3 "DontCare_TakeNoAction" 2 "Reserved" 1 "KneelingRq" 0 "NoKneelingRq" ;
VAL_ 2362638078 AutomaticTractionHelp 3 "DontCare" 2 "Reserved" 1 "EnableAutomaticTractionHelp" 0 "DisableAutomaticTractionHelp" ;
VAL_ 2362638078 LiftAxle2PosCmd 3 "DontCare_TakeNoAction" 2 "Reserved" 1 "LiftAxlePosUp_TagAxleUnladen" 0 "LiftAxlePosDown_TagAxleLaden" ;
VAL_ 2362638078 LiftAxle1PosCmd 3 "DontCare_TakeNoAction" 2 "Reserved" 1 "LiftAxlePosUp_TagAxleUnladen" 0 "LiftAxlePosDown_TagAxleLaden" ;
VAL_ 2365479678 SpeedDependantLevelCtrlStatus 3 "DonTCare_TakeNoAction" 2 "Reserved" 1 "Active" 0 "Inactive" ;
VAL_ 2365479678 MemoryLevel 15 "NotAvailable" 14 "ErrorIndicator" 13 "MemoryLevel5Stored" 12 "MemoryLevel4Stored" 11 "MemoryLevel3Stored" 10 "MemoryLevel2Stored" 9 "MemoryLevel1Stored" 8 "Reserved" 5 "MemoryLevel5Selected" 4 "MemoryLevel4Selected" 3 "MemoryLevel3Selected" 2 "MemoryLevel2Selected" 1 "MemoryLevel1Selected" 0 "NoMemoryLevel" ;
VAL_ 2365479678 AllwLvelCtrlDuringBrakingStatus 3 "DonTCare_TakeNoAction" 2 "Reserved" 1 "Activate" 0 "Deactivate" ;
VAL_ 2365479678 SspensionCtrlRefusalInformation 15 "NotAvailable" 14 "Error" 8 "1101NotDefined" 7 "RqedLevelNotAvailable" 6 "GnrlRjctINSpcifiedReasonApplies" 5 "BelowSpeedLimit" 4 "AboveSpeedLimit" 3 "BogieDiffNotLocked" 2 "WouldExceedAxleLoadLimit" 1 "AxleLoadLimitReached" 0 "ActualRqNotRefused" ;
VAL_ 2365479678 SuspensionRemoteCtrl2 3 "NotAvailable" 2 "Error" 1 "Active" 0 "NotActive" ;
VAL_ 2365479678 SuspensionRemoteCtrl1 3 "NotAvailable" 2 "Error" 1 "Active" 0 "NotActive" ;
VAL_ 2365479678 RearAxleInBumperRange 3 "NotAvailable" 2 "Error" 1 "ActualLevelWithinBumperRange" 0 "ActualLevelOutOfBumperRange" ;
VAL_ 2365479678 FrontAxleInBumperRange 3 "NotAvailable" 2 "Error" 1 "ActualLevelWithinBumperRange" 0 "ActualLevelOutOfBumperRange" ;
VAL_ 2365479678 DoorRelease 3 "NotAvailable" 2 "Error" 1 "DoorsMayBeOpened" 0 "DoorsMayNotBeOpened" ;
VAL_ 2365479678 VehicleMotionInhibit 3 "NotAvailable" 2 "Error" 1 "VehicleMotionIsInhibited" 0 "VehicleMayBeMoved" ;
VAL_ 2365479678 SecurityDevice 3 "NotAvailable" 2 "Error" 1 "Active" 0 "NotActive" ;
VAL_ 2365479678 LevelCtrlMode 11 "1101NotDefined" 10 "AtmtcArSuspensionCtrlProhibited" 15 "NotAvailable" 14 "Error" 9 "AirSuspensionCtrlProhibited" 8 "ExhstngBllwFnctnIBllwsArExhstdT" 7 "TractionHelpLoadReduce" 6 "OptmmTrctn2IPrssAtThDrvnAxlIsCt" 5 "OptmmTrctn1IPrssAtThDrvnAxlIsCt" 4 "PrssRt2IRtBtwnThPrssrsAtThDrvnA" 3 "PrssRt1IRtBtwnThPrssrsAtThDrvnA" 2 "LdFxngIDrvnAxlnIsLddTAVlDfndByT" 1 "TrctnHlpIDrvnAxlIsLddTAMxVlGvnB" 0 "NrmlOprtnISystmPrfrmsAPrCtrlOfT" ;
VAL_ 2365479678 KneelingInformation 15 "NotAvailable" 14 "Error" 5 "1101NotDefined" 4 "KneelingAborted" 3 "LiftingActive" 2 "KneelingLevelReached" 0 "NotActive" ;
VAL_ 2365479678 LiftingCtrlModeRearAxle 3 "NotAvailable" 2 "Error" 1 "LiftingActive" 0 "LiftingNotActive" ;
VAL_ 2365479678 LiftingCtrlModeFrontAxle 3 "NotAvailable" 2 "Error" 1 "LiftingActive" 0 "LiftingNotActive" ;
VAL_ 2365479678 LoweringCtrlModeRearAxle 3 "NotAvailable" 2 "Error" 1 "LoweringActive" 0 "LoweringNotActive" ;
VAL_ 2365479678 LoweringCtrlModeFrontAxle 3 "NotAvailable" 2 "Error" 1 "LoweringActive" 0 "LoweringNotActive" ;
VAL_ 2365479678 AboveNominalLevelRearAxle 3 "NotAvailable" 2 "Error" 1 "Above" 0 "NotAbove" ;
VAL_ 2365479678 AboveNominalLevelFrontAxle 3 "NotAvailable" 2 "Error" 1 "Above" 0 "NotAbove" ;
VAL_ 2365479678 BelowNominalLevelRearAxle 3 "NotAvailable" 2 "Error" 1 "Below" 0 "NotBelow" ;
VAL_ 2365479678 BelowNominalLevelFrontAxle 3 "NotAvailable" 2 "Error" 1 "Below" 0 "NotBelow" ;
VAL_ 2365479678 NominalLevelRearAxle 9 "Raising" 11 "1101NotDefined" 10 "Lowering" 15 "NotAvailable" 14 "Error" 8 "NotDefined" 7 "LowerLevel" 6 "UpperLevel" 5 "CustomerLevel" 4 "PresetLevel" 3 "NormalLevel3" 2 "NormalLevel2" 1 "NormalLevel1" 0 "LevelNotSpecified" ;
VAL_ 2365479678 NominalLevelFrontAxle 9 "Raising" 11 "1101NotDefined" 10 "Lowering" 15 "NotAvailable" 14 "Error" 8 "NotDefined" 7 "LowerLevel" 6 "UpperLevel" 5 "CustomerLevel" 4 "PresetLevel" 3 "NormalLevel3" 2 "NormalLevel2" 1 "NormalLevel1" 0 "LevelNotSpecified" ;
VAL_ 2365479678 LiftAxle2Pos 3 "NotAvailable" 2 "Error" 1 "LiftAxlePosUp_TagAxleUnladen" 0 "LiftAxlePosDown_TagAxleLaden" ;
VAL_ 2365479678 LiftAxle1Pos 3 "NotAvailable" 2 "Error" 1 "LiftAxlePosUp_TagAxleUnladen" 0 "LiftAxlePosDown_TagAxleLaden" ;
VAL_ 2566837758 Alt4Status 3 "notAvailable" 2 "error" 1 "Alt4Charging" 0 "Alt4NotCharging" ;
VAL_ 2566837758 Alt3Status 3 "notAvailable" 2 "error" 1 "Alt3Charging" 0 "Alt3NotCharging" ;
VAL_ 2566837758 Alt2Status 3 "notAvailable" 2 "error" 1 "Alt2Charging" 0 "Alt2NotCharging" ;
VAL_ 2566837758 Alt1Status 3 "notAvailable" 2 "error" 1 "Alt1Charging" 0 "Alt1NotCharging" ;
VAL_ 2566836478 TestIdentifier 250 "Last Measured Scaled Results" 249 "Command Standard Test" 247 "All scaled test results" ;
VAL_ 2565078782 TestIdentifier 250 "Last Measured Scaled Results" 249 "Command Standard Test" 247 "All scaled test results" ;
VAL_ 2565078782 FailureModeIdentifier1 31 "Not available" 19 "Received network data in error" 18 "Below normal (moderately severe)" 17 "Below normal (least severe)" 16 "Above normal (moderately severe)" 15 "Above normal (least severe)" 14 "Special intstructions" 13 "Out of calibration" 12 "Bad intelligent device" 11 "Root cause not known" 10 "Abnormal rate of change" 9 "Abnormal update rate" 8 "Abnormal frequency" 7 "Mechanical system not responding" 6 "Current above normal" 5 "Current below normal" 4 "Voltage below normal" 3 "Voltage above normal" 2 "Data erratic" 1 "Below normal (most severe)" 0 "Above normal (most severe)" ;
VAL_ 2566836222 FlashRedStopLamp 3 "Unavailable / Do Not Flash" 2 "Reserved" 1 "Fast Flash" 0 "Slow Flash" ;
VAL_ 2566836222 FlashProtectLamp 3 "Unavailable / Do Not Flash" 2 "Reserved" 1 "Fast Flash" 0 "Slow Flash" ;
VAL_ 2566836222 FlashMalfuncIndicatorLamp 3 "Unavailable / Do Not Flash" 2 "Reserved" 1 "Fast Flash" 0 "Slow Flash" ;
VAL_ 2566836222 FlashAmberWarningLamp 3 "Unavailable / Do Not Flash" 2 "Reserved" 1 "Fast Flash" 0 "Slow Flash" ;
VAL_ 2566836222 MalfunctionIndicatorLampStatus 3 "Not available" 2 "Reserved" 1 "Lamp on" 0 "Lamp off" ;
VAL_ 2566836222 RedStopLampState 3 "Not available" 2 "Reserved" 1 "Lamp on" 0 "Lamp off" ;
VAL_ 2566836222 AmberWarningLampStatus 3 "Not available" 2 "Reserved" 1 "Lamp on" 0 "Lamp off" ;
VAL_ 2566836222 ProtectLampStatus 3 "Not available" 2 "Reserved" 1 "Lamp on" 0 "Lamp off" ;
VAL_ 2566835966 MisfireMonitoringSupport 3 "Not available" 2 "Reserved" 1 "test supported" 0 "test not supported" ;
VAL_ 2566835966 OBDCompliance 25 "OBD-M (SI-SD/I)" 23 "HD EOBD" 22 "OBD II (California, ARB 07/08)" 21 "WWH OBD" 20 "HD OBD" 19 "HD OBD P" 18 "EMD+" 17 "EMD" 16 "Heavy Duty Vehicles (EURO EEC) C" 15 "Heavy Duty Vehicles (EURO V) B2" 14 "Heavy Duty Vehicles (EURO IV) B1" 13 "JOBD, EOBD and OBD II" 12 "JOBD and EOBD" 11 "JOBD and OBD II" 10 "JOBD" 9 "EOBD, OBD and OBD II" 8 "EOBD and OBD" 7 "EOBD and OBD II" 6 "EOBD" 5 "Not intended to meet OBD II req." 4 "OBD I" 3 "OBD and OBD II" 2 "OBD (Federal, EPA)" 1 "OBD II (California, ARB)" 0 "Reserver for assignment by SAE" ;
VAL_ 2566835966 SecondAirSystemMonStatus 1 "TestNotComplete" 0 "TestComplete" ;
VAL_ 2566835966 EvaporativeSystemMonStatus 1 "TestNotComplete" 0 "TestComplete" ;
VAL_ 2566835966 ACSystemRefrigerantMonStatus 1 "TestNotComplete" 0 "TestComplete" ;
VAL_ 2566835966 OxygenSensorHeaterMonStatus 1 "TestNotComplete" 0 "TestComplete" ;
VAL_ 2566835966 OxygenSensorMonStatus 1 "test not complete" 0 "test complete" ;
VAL_ 2566835966 EGRSystemMonitoringStatus 1 "TestNotComplete" 0 "TestComplete" ;
VAL_ 2566835966 CatalystMonStatus 0 "TestComplete" 1 "TestNotComplete" ;
VAL_ 2566835966 ColdStartAidSystemMonStatus 1 "TestNotComplete" 0 "TestComplete" ;
VAL_ 2566835966 HeatedCatalystMonStatus 1 "TestNotComplete" 0 "TestComplete" ;
VAL_ 2566835966 CatalystMonSupp 1 "TestSupported" 0 "TestNotSupported" ;
VAL_ 2566835966 ColdStartAidSystemMonSupp 1 "TestSupported" 0 "TestNotSupported" ;
VAL_ 2566835966 HeatedCatalystMonSupp 1 "TestSupported" 0 "TestNotSupported" ;
VAL_ 2566835966 EvaporativeSystemMonSupp 1 "TestSupported" 0 "TestNotSupported" ;
VAL_ 2566835966 SecondAirSystemMonSupp 1 "TestSupported" 0 "TestNotSupported" ;
VAL_ 2566835966 ACSystemRefrigerantMonSupp 1 "TestSupported" 0 "TestNotSupported" ;
VAL_ 2566835966 OxygenSensorMonSupp 1 "TestSupported" 0 "TestNotSupported" ;
VAL_ 2566835966 OxygenSensorHeaterMonSupp 1 "TestSupported" 0 "TestNotSupported" ;
VAL_ 2566835966 EGRSystemMonitoringSupp 1 "TestSupported" 0 "TestNotSupported" ;
VAL_ 2566835966 MisfireMonitoringStatus 1 "test not complete" 0 "test complete" ;
VAL_ 2566835966 ComprehensiveCompMonStatus 1 "test not complete" 0 "test complete" ;
VAL_ 2566835966 FuelSystemMonitoringStatus 1 "test not complete" 0 "test complete" ;
VAL_ 2566835966 ComprehensiveComponentMonSupp 3 "Not available" 2 "Reserved" 1 "test supported" 0 "test not supported" ;
VAL_ 2566835966 FuelSystemMonitoringSupport 1 "test supported" 0 "test not supported" ;
VAL_ 2566835710 EngTorqueMode 15 "Not available" 11 "Remote accelerator" 10 "Braking system" 9 "High speed governor" 8 "Torque limiting" 7 "ABS control" 6 "Transmission control" 5 "ASR control" 4 "Road speed governor" 3 "PTO governor" 2 "Cruise control" 1 "Accelerator pedal/operator selec" 0 "Low idle governor/no request (de" ;
VAL_ 2566764286 SPNSupportTypeSTR3 1 "SupportedInScaledTestResults" 0 "NotSupportedInScaledTestResults" ;
VAL_ 2566764286 SPNSupportTypeSTR2 1 "SupportedInScaledTestResults" 0 "NotSupportedInScaledTestResults" ;
VAL_ 2566764286 SPNSupportTypeEFF3 1 "SupportedInExFreezeFrame" 0 "NotSupportedInExFreezeFrame" ;
VAL_ 2566764286 SPNSupportTypeEFF2 1 "SupportedInExFreezeFrame" 0 "NotSupportedInExFreezeFrame" ;
VAL_ 2566764286 SPNSupportTypeDS3 1 "SupportedInDataStream" 0 "NotSupportedInDataStream" ;
VAL_ 2566764286 SPNSupportTypeDS2 1 "SupportedInDataStream" 0 "NotSupportedInDataStream" ;
VAL_ 2566764286 SPNSupportTypeSTR1 1 "SupportedInScaledTestResults" 0 "NotSupportedInScaledTestResults" ;
VAL_ 2566764286 SPNSupportTypeDS1 1 "SupportedInDataStream" 0 "NotSupportedInDataStream" ;
VAL_ 2566764286 SPNSupportTypeEFF1 1 "SupportedInExFreezeFrame" 0 "NotSupportedInExFreezeFrame" ;
VAL_ 2566764030 FlashRedStopLamp 3 "Unavailable / Do Not Flash" 2 "Reserved" 1 "Fast Flash" 0 "Slow Flash" ;
VAL_ 2566764030 FlashProtectLamp 3 "Unavailable / Do Not Flash" 2 "Reserved" 1 "Fast Flash" 0 "Slow Flash" ;
VAL_ 2566764030 FlashMalfuncIndicatorLamp 3 "Unavailable / Do Not Flash" 2 "Reserved" 1 "Fast Flash" 0 "Slow Flash" ;
VAL_ 2566764030 FlashAmberWarningLamp 3 "Unavailable / Do Not Flash" 2 "Reserved" 1 "Fast Flash" 0 "Slow Flash" ;
VAL_ 2566764030 MalfunctionIndicatorLampStatus 3 "Not available" 2 "Reserved" 1 "Lamp on" 0 "Lamp off" ;
VAL_ 2566764030 RedStopLampState 3 "Not available" 2 "Reserved" 1 "Lamp on" 0 "Lamp off" ;
VAL_ 2566764030 AmberWarningLampStatus 3 "Not available" 2 "Reserved" 1 "Lamp on" 0 "Lamp off" ;
VAL_ 2566764030 ProtectLampStatus 3 "Not available" 2 "Reserved" 1 "Lamp on" 0 "Lamp off" ;
VAL_ 2562981630 FailureModeIdentifier1 31 "Not available" 19 "Received network data in error" 18 "Below normal (moderately severe)" 17 "Below normal (least severe)" 16 "Above normal (moderately severe)" 15 "Above normal (least severe)" 14 "Special intstructions" 13 "Out of calibration" 12 "Bad intelligent device" 11 "Root cause not known" 10 "Abnormal rate of change" 9 "Abnormal update rate" 8 "Abnormal frequency" 7 "Mechanical system not responding" 6 "Current above normal" 5 "Current below normal" 4 "Voltage below normal" 3 "Voltage above normal" 2 "Data erratic" 1 "Below normal (most severe)" 0 "Above normal (most severe)" ;
VAL_ 2566835198 MalfunctionIndicatorLampStatus 3 "Not available" 2 "Reserved" 1 "Lamp on" 0 "Lamp off" ;
VAL_ 2566835198 RedStopLampState 3 "Not available" 2 "Reserved" 1 "Lamp on" 0 "Lamp off" ;
VAL_ 2566835198 AmberWarningLampStatus 3 "Not available" 2 "Reserved" 1 "Lamp on" 0 "Lamp off" ;
VAL_ 2566835198 ProtectLampStatus 3 "Not available" 2 "Reserved" 1 "Lamp on" 0 "Lamp off" ;
VAL_ 2566835198 FlashRedStopLamp 3 "Unavailable / Do Not Flash" 2 "Reserved" 1 "Fast Flash" 0 "Slow Flash" ;
VAL_ 2566835198 FlashProtectLamp 3 "Unavailable / Do Not Flash" 2 "Reserved" 1 "Fast Flash" 0 "Slow Flash" ;
VAL_ 2566835198 FlashMalfuncIndicatorLamp 3 "Unavailable / Do Not Flash" 2 "Reserved" 1 "Fast Flash" 0 "Slow Flash" ;
VAL_ 2566835198 FlashAmberWarningLamp 3 "Unavailable / Do Not Flash" 2 "Reserved" 1 "Fast Flash" 0 "Slow Flash" ;
VAL_ 2564357886 Seed 255 "NoFurtherKeyRequiredOfTool" 1 "UseLongSeedOrKeyFromDataSecMsg" 0 "SeedCompleted_BeginSendingKey" ;
VAL_ 2564357886 EDCP_Extension 9 "DataInErrIndAndDataInSeedIsTime" 6 "DataInErrorIndicator" 3 "ConcatenateDataAsLowerEDCParam" 2 "ConcatenateDataAsHigherEDCParam" 0 "Completed" 255 "NoErrIndicator/EDCParamAvailable" ;
VAL_ 2564357886 ErrorIndicator 16777215 "NoErrorIndicatorAvailable" 65540 "TransprtNotComplWithinTimeAllowd" 65539 "TransportNotInitWithinTimeAllowd" 65538 "NoResponseInTheTimeAllowed" 65537 "ModuleExceedingNumberOfRetries" 65536 "AbortFromExtToNormalSoftwareProc" 4103 "VehicleNotInParkOrNotStationary" 4102 "EngineRunning" 4101 "NotInEngineeringOrDevelopmentMode" 4100 "NotInDiagnosticMode" 4099 "InvalidKey" 4098 "InvalidUserLevel" 4097 "InvalidPassword" 4096 "SecurityErrorGeneral" 266 "NameDoesNotConformToExpectdValue" 265 "DataDoesNotConformToValueRanges" 264 "AddrForBootLoadExeInvalidBoundary" 263 "AddrForBootLoadExeOutsideExeMem" 262 "OpReqExeTransfAndEraseOfProgMem" 261 "OpRequiresPriorEraseOfProgramMem" 260 "OpRequiresPriorEraseOfDataMem" 259 "ReqMemoryExceededAvailableMemory" 258 "LengthNotValidForMemStructAndOp" 257 "AddressNotOnValidBoundary" 256 "AddressingOrDataGeneralError" 36 "InternalFailurePreventingReq" 35 "PROMDidNotVerifyOnWrite" 34 "FLASHDidNotVerifyOnWrite" 33 "RAMDidNotVerifyOnWrite" 32 "EDCParaNotCorrectForDataStream" 31 "ProcessUnspecReqFromThisAddress" 23 "ProcessingEDCPGenerationReq" 22 "ProcessingBootLoadReq" 19 "ProcessingStatusReq" 18 "ProcessingWriteReq" 17 "ProcessingReadReq" 16 "ProcessingEraseReq" 2 "ProcessingForSomeoneElse" 1 "ErrorNotIdentified" 0 "NoError" ;
VAL_ 2564357886 Status 7 "Reserved" 6 "Reserved" 5 "OperationFailed" 4 "OperationCompleted" 3 "Reserved" 2 "Reserved" 1 "Busy" 0 "Proceed" ;
VAL_ 2564423422 KeyOrUserLevel 65535 "NoKeyAvailable" 0 "UseLongSeedOrKey" ;
VAL_ 2564423422 PointerExtension 0 "SPN_SPACE" ;
VAL_ 2564423422 Command 7 "EDCP_Generation" 6 "BootLoad" 5 "OperationFailed" 4 "OperationCompleted" 3 "StatusRequest" 2 "Write" 1 "Read" 0 "Erase" ;
VAL_ 2564423422 PointerType 1 "DirectedSpatialAddressing" 0 "DirectMemoryAddressing" ;
VAL_ 2564816638 HoldSignal 15 "Not available" 1 "Devices whose broadcast state ha" 0 "All devices" ;
VAL_ 2564816638 J1939Network3 3 "Don't care" 2 "Reserved" 1 "Start broadcast" 0 "Stop broadcast" ;
VAL_ 2564816638 J1939Network2 3 "Don't care" 2 "Reserved" 1 "Start broadcast" 0 "Stop broadcast" ;
VAL_ 2564816638 ISO9141 3 "Don't care" 2 "Reserved" 1 "Start broadcast" 0 "Stop broadcast" ;
VAL_ 2564816638 SAE_J1850 3 "Don't care" 2 "Reserved" 1 "Start broadcast" 0 "Stop broadcast" ;
VAL_ 2564816638 ManufacturerSpecificPort 3 "Don't care" 2 "Reserved" 1 "Start broadcast" 0 "Stop broadcast" ;
VAL_ 2564816638 CurrentDataLink 3 "Don't care" 2 "Reserved" 1 "Start broadcast" 0 "Stop broadcast" ;
VAL_ 2564816638 SAE_J1587 3 "Don't care" 2 "Reserved" 1 "Start broadcast" 0 "Stop broadcast" ;
VAL_ 2564816638 SAE_J1922 3 "Don't care" 2 "Reserved" 1 "Start broadcast" 0 "Stop broadcast" ;
VAL_ 2564816638 J1939Network1 3 "Don't care" 2 "Reserved" 1 "Start broadcast" 0 "Stop broadcast" ;
VAL_ 2564816638 SuspendSignal 15 "NotAvailable" 14 "ResumingNormalBroadcastPattern" 3 "TemporarySuspensionOfSomeMessages" 2 "TemporarySuspensionOfAllBroadcasts" 1 "IndefiniteSuspensionOfSomeMessages" 0 "IndefiniteSuspensionOfAllBroadcasts" ;
VAL_ 2566837502 FlashRedStopLamp 3 "Unavailable / Do Not Flash" 2 "Reserved" 1 "Fast Flash" 0 "Slow Flash" ;
VAL_ 2566837502 FlashProtectLamp 3 "Unavailable / Do Not Flash" 2 "Reserved" 1 "Fast Flash" 0 "Slow Flash" ;
VAL_ 2566837502 MalfunctionIndicatorLampStatus 3 "Not available" 2 "Reserved" 1 "Lamp on" 0 "Lamp off" ;
VAL_ 2566837502 RedStopLampState 3 "Not available" 2 "Reserved" 1 "Lamp on" 0 "Lamp off" ;
VAL_ 2566837502 AmberWarningLampStatus 3 "Not available" 2 "Reserved" 1 "Lamp on" 0 "Lamp off" ;
VAL_ 2566837502 ProtectLampStatus 3 "Not available" 2 "Reserved" 1 "Lamp on" 0 "Lamp off" ;
VAL_ 2566837502 FlashMalfuncIndicatorLamp 3 "Unavailable / Do Not Flash" 2 "Reserved" 1 "Fast Flash" 0 "Slow Flash" ;
VAL_ 2566837502 FlashAmberWarningLamp 3 "Unavailable / Do Not Flash" 2 "Reserved" 1 "Fast Flash" 0 "Slow Flash" ;
VAL_ 2566834942 FlashRedStopLamp 3 "Unavailable / Do Not Flash" 2 "Reserved" 1 "Fast Flash" 0 "Slow Flash" ;
VAL_ 2566834942 FlashProtectLamp 3 "Unavailable / Do Not Flash" 2 "Reserved" 1 "Fast Flash" 0 "Slow Flash" ;
VAL_ 2566834942 FlashMalfuncIndicatorLamp 3 "Unavailable / Do Not Flash" 2 "Reserved" 1 "Fast Flash" 0 "Slow Flash" ;
VAL_ 2566834942 FlashAmberWarningLamp 3 "Unavailable / Do Not Flash" 2 "Reserved" 1 "Fast Flash" 0 "Slow Flash" ;
VAL_ 2566834942 MalfunctionIndicatorLampStatus 3 "Not available" 2 "Reserved" 1 "Lamp on" 0 "Lamp off" ;
VAL_ 2566834942 AmberWarningLampStatus 3 "Not available" 2 "Reserved" 1 "Lamp on" 0 "Lamp off" ;
VAL_ 2566834942 RedStopLampState 3 "Not available" 2 "Reserved" 1 "Lamp on" 0 "Lamp off" ;
VAL_ 2566834942 ProtectLampStatus 3 "Not available" 2 "Reserved" 1 "Lamp on" 0 "Lamp off" ;
VAL_ 2566784254 GnrtorOverallPowerFactorLagging 3 "NotAvailable_NotInstalled" 2 "Error" 1 "Lagging" 0 "Leading" ;
VAL_ 2566781950 GnratorPhaseCPowerFactorLagging 3 "NotAvailable_NotInstalled" 2 "Error" 1 "Lagging" 0 "Leading" ;
VAL_ 2566782718 GnratorPhaseBPowerFactorLagging 3 "NotAvailable_NotInstalled" 2 "Error" 1 "Lagging" 0 "Leading" ;
VAL_ 2566783486 GnratorPhaseAPowerFactorLagging 3 "NotAvailable_NotInstalled" 2 "Error" 1 "Lagging" 0 "Leading" ;
VAL_ 2566776830 Bus1_UtilityInSync 3 "NotAvailable" 2 "Error" 1 "Sycnchronized" 0 "NotSynchronized" ;
VAL_ 2566776830 Bus1_UtilityVoltageMatch 3 "NotAvailable" 2 "Error" 1 "VoltagesMatch" 0 "VolatagesDoNotMatch" ;
VAL_ 2566776830 Bus1_UtilityFrequencyMatch 3 "NotAvailable" 2 "Error" 1 "FrequenciesMatch" 0 "FrequenciesDoNotMatch" ;
VAL_ 2566776830 Bus1_UtilityPhaseMatch 3 "NotAvailable" 2 "Error" 1 "PhasesMatch" 0 "PhasesDoNotMatch" ;
VAL_ 2566776830 Bus1_UtilityDeadBus 3 "NotAvailable" 2 "Error" 1 "BusIsDead" 0 "BusIsNotDead" ;
VAL_ 2566777086 Bus1_GeneratorInSync 3 "NotAvailable" 2 "Error" 1 "Sycnchronized" 0 "NotSynchronized" ;
VAL_ 2566777086 Bus1_GeneratorVoltageMatch 3 "NotAvailable" 2 "Error" 1 "VoltagesMatch" 0 "VolatagesDoNotMatch" ;
VAL_ 2566777086 Bus1_GeneratorFrequencyMatch 3 "NotAvailable" 2 "Error" 1 "FrequenciesMatch" 0 "FrequenciesDoNotMatch" ;
VAL_ 2566777086 Bus1_GeneratorPhaseMatch 3 "NotAvailable" 2 "Error" 1 "PhasesMatch" 0 "PhasesDoNotMatch" ;
VAL_ 2566777086 Bus1_GeneratorDeadBus 3 "NotAvailable" 2 "Error" 1 "BusIsDead" 0 "BusIsNotDead" ;
VAL_ 2566838526 IndustryGroup 6 "Reserved for SAE" 7 "Reserved for SAE" 5 "IndustrialProcessCtrlStationary" 4 "Marine" 3 "Construction" 2 "Agricultural and Forestry" 1 "On-Highway" 0 "Global" ;
VAL_ 2566838526 Function 127 "Reserved" 126 "Reserved" 125 "Reserved" 124 "Reserved" 123 "Reserved" 122 "Reserved" 121 "Reserved" 120 "Reserved" 119 "Reserved" 118 "Reserved" 117 "Reserved" 116 "Reserved" 115 "Reserved" 114 "Reserved" 113 "Reserved" 112 "Reserved" 111 "Reserved" 110 "Reserved" 109 "Reserved" 108 "Reserved" 107 "Reserved" 106 "Reserved" 105 "Reserved" 104 "Reserved" 103 "Reserved" 102 "Reserved" 101 "Reserved" 42 "Water Pump Control" 41 "Lighting - Operator Controls" 40 "Seat Control" 39 "Ignition Control Module" 38 "Tire Pressure Control" 37 "Cab Controller" 36 "Pneumatic - System Controller" 35 "Suspension - System Controller" 34 "Hydraulic Pump Controller" 33 "System Monitor" 32 "Headway Controller" 31 "Propulsion Battery Charger" 30 "Management Computer" 29 "Virtual Terminal (In Cab)" 28 "Off Vehicle Gateway" 27 "Power TakeOff (Secondary or Front)" 26 "Body Controller" 25 "Network Interconnect ECU" 24 "Vehicle Security" 23 "Vehicle Navigation" 22 "Aerodynamic Control" 21 "Cab Climate Control" 20 "Trip Recorder" 19 "Instrument Cluster" 18 "Suspension - Drive Axle" 17 "Suspension - Steer Axle" 16 "Steering Controller" 15 "Fuel System" 14 "Cruise Control" 13 "Retarder - Driveline" 12 "Retarder - Engine" 11 "Brakes - Drive Axle" 10 "Brakes - Steer Axle" 9 "Brakes - System Controller" 8 "Axle - Drive" 7 "Axle - Steering" 6 "Power TakeOff - (Main or Rear)" 5 "Shift Control/Console" 4 "Battery Pack Monitor" 3 "Transmission" 2 "Electric Propulsion Control" 1 "Auxiliary Power Unit (APU)" 0 "Engine" 100 "Reserved" 99 "Reserved" 98 "Reserved" 97 "Reserved" 96 "Reserved" 95 "Reserved" 94 "Reserved" 93 "Reserved" 92 "Reserved" 91 "Reserved" 90 "Reserved" 89 "Reserved" 88 "Reserved" 87 "Reserved" 86 "Reserved" 85 "Reserved" 84 "Reserved" 83 "Reserved" 82 "Reserved" 81 "Reserved" 80 "Reserved" 79 "Reserved" 78 "Reserved" 77 "Reserved" 76 "Reserved" 75 "Reserved" 74 "Reserved" 73 "Reserved" 72 "Coolant Valve Controller" 71 "Transfer Case Control" 70 "Auxiliary Regeneration Device" 69 "Engine Emission Aftertreatement System" 68 "Aftertreatment system gas measurement" 67 "Electrical System Controller" 66 "I/O Controller" 65 "Gas Flow Measurement" 64 "Endurance Braking" 63 "Engine Valve Controller" 62 "On-Board Diagnostic Unit" 61 "File Server/Printer" 60 "Cab Display" 59 "Starter" 58 "Fan Drive Control" 57 "Steering Column Unit" 56 "Communications Unit, Radio" 55 "Communications Unit, Satellite" 54 "Communications Unit, Cellular" 53 "Alternator/Charging System" 52 "Chassis Controller" 51 "Forward-Looking Collision Warning System" 50 "Auxiliary Heater" 49 "Clutch/Converter Control" 48 "Ramp Control" 47 "Information System Controller" 46 "Oil Sensor Unit" 45 "Vehicle Dynamic Stability Control" 44 "Exhaust Emission Control" 43 "Transmission Display" ;
VAL_ 2566838526 VehicleSystem 0 "Non-specific System" 127 "Not Available" ;
VAL_ 2566838526 ManufacturerCode 252 "Sensor-Technik Wiedemann GmbH" 251 "German Agricultural Society" 250 "Kuhn Group" 249 "Schaltbau GmbH" 233 "Yacht Monitoring Solutions Inc." 232 "TSD Integrated Controls" 1863 "Thomas G. Faria Co." 1862 "Sanshin" 1861 "Vector CANtech" 1860 "MMP" 1859 "Kvasar AB" 1858 "Litton" 1857 "Simrad" 1856 "Trimble" 1855 "Furuno USA" 1854 "Northstar Technologies" 1853 "Japan Radio Co." 1852 "Navionics" 1851 "Raymarine" 1850 "Teleflex" 222 "Generac Power Systems, Inc." 221 "SiE" 220 "Beede Electrical Instrument Company, Inc." 219 "Cat OEM Solutions" 218 "Gits Manufacturing Company" 217 "RM Michaelides Software & Elektronik GmbH" 216 "Paneltronics Inc." 215 "Aetna Engineering/Fireboy-Xintex" 214 "MC elettronica Srl" 213 "CNH Belgium N.V." 212 "Sure Power Industries, Inc." 211 "DNA Group" 210 "Iteris, Inc." 209 "Bell Equip. Co. SA (PTY) LTD" 208 "Drew Technologies, Inc." 207 "Otto Engineering" 206 "port GmbH" 205 "SmarTire Systems Inc" 204 "The Morey Corporation" 203 "MILtronik GmbH" 202 "Curtis Instruments, Inc." 201 "Disenos y Tecnologia S.A." 200 "MGM Brakes" 199 "Actia Corp." 198 "Mystic Valley Communications" 197 "Mechron Power Systems" 196 "LEMKEN GmbH & Co. KG" 195 "General Engine Products" 194 "TriMark Corporation" 193 "Jeppesen Marine" 192 "Floscan" 191 "XATA Corporation" 190 "Hella KGaA Hueck & Co." 189 "QUALCOMM" 188 "EMP Corp." 187 "Air-Weigh" 186 "Altronic, Inc." 185 "Beede Electrical Instrument Company" 184 "EIA Electronics" 183 "KDS Controls, Inc." 182 "Vehicle Systems Engineering B.V." 181 "Coretronics, Inc." 180 "Smart Power Systems" 179 "TeeJet Technologies Denmark" 178 "Siemens VDO Automotive AG" 177 "Diagnostic System Associates" 176 "Moritz Aerospace" 175 "Veris Technologies, Inc." 174 "AB Volvo Penta" 173 "Ryeso, Inc." 172 "Yanmar Marine USA" 171 "Wachendorff Elektronik GmbH & Co. KG" 170 "Computronics Corporation Ltd." 169 "Marlin Technologies Inc." 168 "Xantrex" 167 "JLG Industries Inc." 166 "Phoenix International" 165 "CPAC Systems AB" 164 "DaimlerChrysler Off-Highway" 163 "BRP Inc." 162 "Axiomatic Technologies" 161 "Offshore Systems (UK) Limited" 160 "Nido" 159 "NTech Industries Inc." 158 "Firestone Industrial Products Company" 157 "ISSPRO Inc." 156 "ITT Industries - Cannon" 155 "Vetronix Corporation" 154 "Westerbeke Corporation" 153 "Woodward, Industrial Controls Division" 152 "Elobau Elektrobauelemente GmbH & Co. KG" 151 "Raven Industries Inc. - Flow Controls Division" 150 "Fleetguard" 149 "Holset" 148 "Blue Water Data, Inc." 147 "Nautibus Electronic GmbH" 146 "Maxima Technologies" 145 "MurCal Controls" 144 "Mercury Marine" 143 "W. Gmeiner GmbH & Co." 142 "TRW Automotive (Commercial Steering Systems)" 141 "Thales Navigation Ltd." 140 "Lowrance Electronics, Inc." 139 "Caterpillar Trimble Control Technologies (CTCT), LLC" 138 "Georg Fritzmeier GmbH & Co. KG" 137 "Maretron" 136 "Komatsu Ltd." 135 "Airmar Technology Corporation" 134 "Iris Technology Ltd." 133 "Bucher Schoerling GmbH" 132 "Mulag-Fahrzeugwerk" 131 "ITT Industries" 130 "Nido - Universal Machines B.V." 129 "OMNEX Control Systems, Inc." 128 "Gerhard Duecker GmbH & Co. KG" 127 "Holland USA" 126 "Driver Tech" 125 "Nevada Automotive Test Center" 124 "Hydac Electronic" 123 "Basler Electric" 122 "FG Wilson (Engineering) Limited" 121 "HED (Hydro Electronic Devices, Inc.)" 120 "RDS Technology Ltd." 119 "IntegriNautics" 118 "Intron GmbH" 117 "HUSCO International" 116 "BEELINE Technologies" 115 "NACCO Materials Handling Group, Inc." 114 "EControls, Inc." 113 "Stress-Tek, Inc." 112 "MECALAC" 111 "Maschinenfabrik Bernhard Krone GmbH" 110 "EPIQ Sensor-Nite" 109 "TeeJet Technologies Denmark" 108 "WTK-Elecktronik GmbH" 107 "Grimme Landmaschinen GmbH & Co. KG" 106 "BAE Systems Controls, Inc." 105 "Kiepe Elektrik GmbH & Co. KG" 104 "Claas Selbstfahrende Erntemaschinen GmbH" 103 "Agrocom GmbH & Co. Agrarsystem KG" 102 "AGCO GmbH & Co." 101 "Sensoria" 100 "VDO Technik AG" 99 "International Transmissions Ltd (ITL)" 98 "Mueller-Elektronik GmbH & Co." 97 "Ag Leader Technology, Inc." 96 "Mech@tronic IT GmbH" 95 "Pacific Insight Electronics Corp." 94 "CNH Global N.V." 93 "Perkins Engines Company Ltd." 92 "Ag-Chem Equipment Co., Inc." 91 "BSG Bodensee Steuergeraete GmbH" 90 "Knorr-Bremse SfN GmbH" 89 "Kverneland Group, Electronics Division" 88 "Satloc Precision GPS" 87 "J.C. Bamford Excavators Ltd (JCB)" 86 "C.E. Niehoff & Company" 85 "Kohler Co." 84 "New Holland UK Limited" 83 "Eaton VORAD Technologies" 82 "Bobcat/Ingersoll-Rand" 81 "Fire Research Corp" 80 "Twin Disc, Inc." 79 "Daimler Benz AG - Engine Division (PBM)" 78 "Frank W. Murphy Manufacturing, Inc." 77 "Deere Power Systems Group" 76 "unused" 75 "Deere & Co. Agricultural Division" 74 "Eaton Axle-Brake Division" 73 "LeTourneau, Inc." 72 "Sisu Corporation" 71 "Vansco Electronics Ltd." 70 "Flex-Coil Limited" 69 "Trimble Navigation" 68 "Scania" 67 "Funk Manufacturing Company" 66 "John Deere Construction Equipment Division" 65 "MAN Nutzfahrzeuge AG" 64 "unused" 63 "ZF Industries Inc." 62 "Wabco" 61 "Volvo Truck Corp." 60 "Volvo Trucks North America Inc." 59 "VES Inc." 58 "SPX Corporation, OTC Division" 57 "Sauer-Danfoss Co." 56 "SAIC" 55 "Ryder System Inc." 54 "Meritor Wabco" 53 "Continental Automotive Systems US, Inc." 52 "Meritor Automotive, Inc." 51 "Robert Bosch GmbH" 50 "Robert Bosch Corp" 49 "RE America Inc." 48 "Pollak Alphabet" 47 "Phillips Semiconductor" 46 "Parasoft Computing Solutions" 45 "PACCAR" 44 "Nippondenso Co. Ltd." 43 "International Truck and Engine Corp. Vehicle Electronics" 42 "International Truck and Engine Corp. Engine Electronics" 41 "Motorola Inc." 40 "Motorola AIEG Inc." 39 "Microfirm Inc." 38 "Micro Processor Systems Inc." 37 "Mack Trucks Inc." 36 "Lucas Ltd." 35 "Kenworth Truck Co." 34 "Kelsey Hayes Co." 33 "John Deere" 32 "Jacobs Vehicle Systems" 31 "J Pollak Corp." 30 "Isuzu Motors Ltd." 29 "Hino Motors Ltd." 28 "Grote Ind. Inc." 27 "GMC" 26 "General Motors Corp., Service Technology Group" 25 "Daimler Trucks North America LLC" 24 "Ford Motor Co., Vehicle Controls" 23 "Ford Motor Co., Heavy Truck" 22 "Ford Motor Co., Electronic Concepts $ Systems" 21 "Echilin Inc., Midland Brake Inc." 20 "Eaton Ltd" 19 "Eaton Corp. Trucking Info Services" 18 "Eaton Corp, Transmission Division" 17 "Eaton Corp. Res & Dev" 16 "Eaton Corp." 15 "Dickey-John Corp." 14 "Detroit Diesel Corporation" 13 "Delco Electronics" 12 "Deere & Company, Precision Farming" 11 "Dearborn Group Inc." 10 "Cummins Engine Co." 9 "Chrysler Corp." 8 "Caterpillar Inc." 7 "Case Corp." 6 "Berifors Electronics AB" 5 "AMP Inc." 4 "Ametek-Dixson" 3 "Ametek, US Gauge Division" 2 "Allison Transmission, GMC" 1 "Allied Signal Inc." 0 "Reserved" 231 "Topcon Positioning Systems, Inc." 230 "Saucon Technologies" 229 "Garmin International Inc." 228 "ZF Marine Electronics" 227 "Lykketronic A/S" 226 "Monaco Coach Corporation" 225 "SKF" 224 "EMMI Network, S.L." 223 "Vaueo Retarder Co., Ltd." 263 "IMMI" 262 "HydraForce, Inc" 261 "Red Dot Corporation" 260 "Reichhardt GmbH" 259 "Jetter AG" 258 "ARAG" 257 "Honda Motor Co., Ltd" 256 "Tyco Electronics AMP" 255 "MEAS France" 254 "GE Sensing" 253 "Mobile Control Systems" 298 "Holley Performance" 297 "Zonar Systems Inc" 296 "micro dynamics GmbH" 295 "BEP Marine" 294 "Grayhill Inc." 293 "Spyder Controls Corp." 292 "IKUSI - Angel Iglesias S.A." 291 "Groeneveld Transport Efficiency BV" 290 "Kuebler GmbH" 289 "Watlow" 288 "Mitsubishi FUSO Truck & Bus Corp." 287 "NTech Industries, Inc" 286 "Coelmo srl" 285 "Sea Recovery Corp" 284 "Mobile Tech Chile" 283 "CWF Hamilton & Co Ltd" 282 "Medallion Instrumentation Systems" 281 "Precision Governors LLC" 311 "Patrick Power Products" 310 "TECNORD srl" 309 "Krauss-Maffei Wegmann GmbH & Co. KG" 308 "Cyntrx" 307 "MAS Technologies" 306 "Sleipner Motor AB" 305 "NovAtel Inc" 304 "EmpirBus AB" 303 "CTS Corporation" 302 "Nissin Kogyo Co., LTD" 301 "Parker Hannifin (UK) Ltd FDE group" 300 "Systron Donner Automotive" 299 "Rauch Landmaschinen GmbH" 280 "Leica Geosystems Pty Ltd" 279 "Geometris LP" 278 "Takata Electronics" 277 "LHP Telematics" 276 "Aqua-Hot Heating Systems" 275 "Navico Egersund AS" 274 "LTW Technology Co., LTD" 273 "Active Research Limited" 272 "Gross Mechanical Laboratories, Inc" 327 "Sonceboz SA" 326 "Akron Brass Company" 325 "ASM Automation Sensorik Messtechnik GmbH" 324 "Snap-on Diagnostics" 323 "Mobileye Vision Technologies Ltd." 322 "MICHENKA s.r.o." 321 "Ultra Electronics, Electrics" 320 "Miedema Landbouwwerktuigenfabriek B.V." 319 "Cadec Global" 318 "SAT Plan" 317 "Navtronics Bvba" 316 "ITT Flow Control" 315 "Icom Incorporated" 314 "CSM GmbH" 313 "Ilmor Engineering, Inc" 312 "Lectronix, Inc." 271 "Cole Hersee" 270 "Tennant" 269 "Saft America Inc.,  Space & Defense Division" 268 "Accurate Technologies" 267 "Red Lion Controls, Inc" 266 "International Thermal Research Ltd" 265 "MTS Sensor Technologie GmbH" 264 "Autolync" 248 "Cooper Standard Automotive Active Systems Group" 247 "ePULSE" 246 "Class 1, Inc" 245 "Capstan Ag Systems, Inc." 244 "Techno-Matic" 243 "eRide, Inc." 242 "Kokusandenki Co. Ltd" 241 "Schneider Automation SAS " 240 "Vanair Mfg" 239 "May & Scofield Ltd" 238 "ZF Friedrichshafen AG" 237 "Agtron Enterprises Inc" 236 "Norac Systems International Inc" 235 "SailorMade Marine Telemetry - Tetra Technology Ltd." 234 "Mondial electronic GmbH" ;
VAL_ 2566838526 VehicleSystem5 127 "Not Available" 0 "Ind. Process Control Stationary" ;
VAL_ 2566838526 VehicleSystem4 100 "Deck/Cargo/Fishing equip. sys" 90 "Environmental (HVAC) Systems" 80 "Instrumentation/General Systems" 70 "Communications Systems" 60 "Navigation Systems" 50 "Propulsion Systems" 40 "Steering Systems" 30 "Power Mgmt and lighting systems" 25 "Gateway" 20 "Safety Systems" 10 "System Tools" 127 "Not Available" 0 "Non-specific System" ;
VAL_ 2566838526 VehicleSystem3 8 "Grader" 7 "Four Wheel Drive Loader" 6 "Forklift" 5 "Excavator" 4 "Crawler" 3 "Backhoe" 2 "Articulated Dump Truck" 1 "Skid Steer Loader" 127 "Not Available" 0 "Non-specific System" ;
VAL_ 2566838526 VehicleSystem2 16 "Skidder" 15 "Earth Work" 14 "Special Crops" 13 "Powered Auxiliary Device" 12 "Farm Yard Operations" 11 "Transport/Trailer" 10 "Irrigation" 9 "Forage" 8 "Root Harvesters" 7 "Harvesters" 6 "Sprayers" 5 "Fertilizers" 4 "Planters/Seeders" 3 "Secondary Tillage" 2 "Tillage" 1 "Tractor" 127 "Not Available" 0 "Non-specific System" ;
VAL_ 2566838526 VehicleSystem1 2 "Trailer" 1 "Tractor" 127 "Not Available" 0 "Non-specific System" ;
VAL_ 2565799678 IndustryGroup 6 "Reserved for SAE" 7 "Reserved for SAE" 5 "IndustrialProcessCtrlStationary" 4 "Marine" 3 "Construction" 2 "Agricultural and Forestry" 1 "On-Highway" 0 "Global" ;
VAL_ 2565799678 Function 127 "Reserved" 126 "Reserved" 125 "Reserved" 124 "Reserved" 123 "Reserved" 122 "Reserved" 121 "Reserved" 120 "Reserved" 119 "Reserved" 118 "Reserved" 117 "Reserved" 116 "Reserved" 115 "Reserved" 114 "Reserved" 113 "Reserved" 112 "Reserved" 111 "Reserved" 110 "Reserved" 109 "Reserved" 108 "Reserved" 107 "Reserved" 106 "Reserved" 105 "Reserved" 104 "Reserved" 103 "Reserved" 102 "Reserved" 101 "Reserved" 42 "Water Pump Control" 41 "Lighting - Operator Controls" 40 "Seat Control" 39 "Ignition Control Module" 38 "Tire Pressure Control" 37 "Cab Controller" 36 "Pneumatic - System Controller" 35 "Suspension - System Controller" 34 "Hydraulic Pump Controller" 33 "System Monitor" 32 "Headway Controller" 31 "Propulsion Battery Charger" 30 "Management Computer" 29 "Virtual Terminal (In Cab)" 28 "Off Vehicle Gateway" 27 "Power TakeOff (Secondary or Front)" 26 "Body Controller" 25 "Network Interconnect ECU" 24 "Vehicle Security" 23 "Vehicle Navigation" 22 "Aerodynamic Control" 21 "Cab Climate Control" 20 "Trip Recorder" 19 "Instrument Cluster" 18 "Suspension - Drive Axle" 17 "Suspension - Steer Axle" 16 "Steering Controller" 15 "Fuel System" 14 "Cruise Control" 13 "Retarder - Driveline" 12 "Retarder - Engine" 11 "Brakes - Drive Axle" 10 "Brakes - Steer Axle" 9 "Brakes - System Controller" 8 "Axle - Drive" 7 "Axle - Steering" 6 "Power TakeOff - (Main or Rear)" 5 "Shift Control/Console" 4 "Battery Pack Monitor" 3 "Transmission" 2 "Electric Propulsion Control" 1 "Auxiliary Power Unit (APU)" 0 "Engine" 100 "Reserved" 99 "Reserved" 98 "Reserved" 97 "Reserved" 96 "Reserved" 95 "Reserved" 94 "Reserved" 93 "Reserved" 92 "Reserved" 91 "Reserved" 90 "Reserved" 89 "Reserved" 88 "Reserved" 87 "Reserved" 86 "Reserved" 85 "Reserved" 84 "Reserved" 83 "Reserved" 82 "Reserved" 81 "Reserved" 80 "Reserved" 79 "Reserved" 78 "Reserved" 77 "Reserved" 76 "Reserved" 75 "Reserved" 74 "Reserved" 73 "Reserved" 72 "Coolant Valve Controller" 71 "Transfer Case Control" 70 "Auxiliary Regeneration Device" 69 "Engine Emission Aftertreatement System" 68 "Aftertreatment system gas measurement" 67 "Electrical System Controller" 66 "I/O Controller" 65 "Gas Flow Measurement" 64 "Endurance Braking" 63 "Engine Valve Controller" 62 "On-Board Diagnostic Unit" 61 "File Server/Printer" 60 "Cab Display" 59 "Starter" 58 "Fan Drive Control" 57 "Steering Column Unit" 56 "Communications Unit, Radio" 55 "Communications Unit, Satellite" 54 "Communications Unit, Cellular" 53 "Alternator/Charging System" 52 "Chassis Controller" 51 "Forward-Looking Collision Warning System" 50 "Auxiliary Heater" 49 "Clutch/Converter Control" 48 "Ramp Control" 47 "Information System Controller" 46 "Oil Sensor Unit" 45 "Vehicle Dynamic Stability Control" 44 "Exhaust Emission Control" 43 "Transmission Display" ;
VAL_ 2565799678 ManufacturerCode 252 "Sensor-Technik Wiedemann GmbH" 251 "German Agricultural Society" 250 "Kuhn Group" 249 "Schaltbau GmbH" 233 "Yacht Monitoring Solutions Inc." 232 "TSD Integrated Controls" 1863 "Thomas G. Faria Co." 1862 "Sanshin" 1861 "Vector CANtech" 1860 "MMP" 1859 "Kvasar AB" 1858 "Litton" 1857 "Simrad" 1856 "Trimble" 1855 "Furuno USA" 1854 "Northstar Technologies" 1853 "Japan Radio Co." 1852 "Navionics" 1851 "Raymarine" 1850 "Teleflex" 222 "Generac Power Systems, Inc." 221 "SiE" 220 "Beede Electrical Instrument Company, Inc." 219 "Cat OEM Solutions" 218 "Gits Manufacturing Company" 217 "RM Michaelides Software & Elektronik GmbH" 216 "Paneltronics Inc." 215 "Aetna Engineering/Fireboy-Xintex" 214 "MC elettronica Srl" 213 "CNH Belgium N.V." 212 "Sure Power Industries, Inc." 211 "DNA Group" 210 "Iteris, Inc." 209 "Bell Equip. Co. SA (PTY) LTD" 208 "Drew Technologies, Inc." 207 "Otto Engineering" 206 "port GmbH" 205 "SmarTire Systems Inc" 204 "The Morey Corporation" 203 "MILtronik GmbH" 202 "Curtis Instruments, Inc." 201 "Disenos y Tecnologia S.A." 200 "MGM Brakes" 199 "Actia Corp." 198 "Mystic Valley Communications" 197 "Mechron Power Systems" 196 "LEMKEN GmbH & Co. KG" 195 "General Engine Products" 194 "TriMark Corporation" 193 "Jeppesen Marine" 192 "Floscan" 191 "XATA Corporation" 190 "Hella KGaA Hueck & Co." 189 "QUALCOMM" 188 "EMP Corp." 187 "Air-Weigh" 186 "Altronic, Inc." 185 "Beede Electrical Instrument Company" 184 "EIA Electronics" 183 "KDS Controls, Inc." 182 "Vehicle Systems Engineering B.V." 181 "Coretronics, Inc." 180 "Smart Power Systems" 179 "TeeJet Technologies Denmark" 178 "Siemens VDO Automotive AG" 177 "Diagnostic System Associates" 176 "Moritz Aerospace" 175 "Veris Technologies, Inc." 174 "AB Volvo Penta" 173 "Ryeso, Inc." 172 "Yanmar Marine USA" 171 "Wachendorff Elektronik GmbH & Co. KG" 170 "Computronics Corporation Ltd." 169 "Marlin Technologies Inc." 168 "Xantrex" 167 "JLG Industries Inc." 166 "Phoenix International" 165 "CPAC Systems AB" 164 "DaimlerChrysler Off-Highway" 163 "BRP Inc." 162 "Axiomatic Technologies" 161 "Offshore Systems (UK) Limited" 160 "Nido" 159 "NTech Industries Inc." 158 "Firestone Industrial Products Company" 157 "ISSPRO Inc." 156 "ITT Industries - Cannon" 155 "Vetronix Corporation" 154 "Westerbeke Corporation" 153 "Woodward, Industrial Controls Division" 152 "Elobau Elektrobauelemente GmbH & Co. KG" 151 "Raven Industries Inc. - Flow Controls Division" 150 "Fleetguard" 149 "Holset" 148 "Blue Water Data, Inc." 147 "Nautibus Electronic GmbH" 146 "Maxima Technologies" 145 "MurCal Controls" 144 "Mercury Marine" 143 "W. Gmeiner GmbH & Co." 142 "TRW Automotive (Commercial Steering Systems)" 141 "Thales Navigation Ltd." 140 "Lowrance Electronics, Inc." 139 "Caterpillar Trimble Control Technologies (CTCT), LLC" 138 "Georg Fritzmeier GmbH & Co. KG" 137 "Maretron" 136 "Komatsu Ltd." 135 "Airmar Technology Corporation" 134 "Iris Technology Ltd." 133 "Bucher Schoerling GmbH" 132 "Mulag-Fahrzeugwerk" 131 "ITT Industries" 130 "Nido - Universal Machines B.V." 129 "OMNEX Control Systems, Inc." 128 "Gerhard Duecker GmbH & Co. KG" 127 "Holland USA" 126 "Driver Tech" 125 "Nevada Automotive Test Center" 124 "Hydac Electronic" 123 "Basler Electric" 122 "FG Wilson (Engineering) Limited" 121 "HED (Hydro Electronic Devices, Inc.)" 120 "RDS Technology Ltd." 119 "IntegriNautics" 118 "Intron GmbH" 117 "HUSCO International" 116 "BEELINE Technologies" 115 "NACCO Materials Handling Group, Inc." 114 "EControls, Inc." 113 "Stress-Tek, Inc." 112 "MECALAC" 111 "Maschinenfabrik Bernhard Krone GmbH" 110 "EPIQ Sensor-Nite" 109 "TeeJet Technologies Denmark" 108 "WTK-Elecktronik GmbH" 107 "Grimme Landmaschinen GmbH & Co. KG" 106 "BAE Systems Controls, Inc." 105 "Kiepe Elektrik GmbH & Co. KG" 104 "Claas Selbstfahrende Erntemaschinen GmbH" 103 "Agrocom GmbH & Co. Agrarsystem KG" 102 "AGCO GmbH & Co." 101 "Sensoria" 100 "VDO Technik AG" 99 "International Transmissions Ltd (ITL)" 98 "Mueller-Elektronik GmbH & Co." 97 "Ag Leader Technology, Inc." 96 "Mech@tronic IT GmbH" 95 "Pacific Insight Electronics Corp." 94 "CNH Global N.V." 93 "Perkins Engines Company Ltd." 92 "Ag-Chem Equipment Co., Inc." 91 "BSG Bodensee Steuergeraete GmbH" 90 "Knorr-Bremse SfN GmbH" 89 "Kverneland Group, Electronics Division" 88 "Satloc Precision GPS" 87 "J.C. Bamford Excavators Ltd (JCB)" 86 "C.E. Niehoff & Company" 85 "Kohler Co." 84 "New Holland UK Limited" 83 "Eaton VORAD Technologies" 82 "Bobcat/Ingersoll-Rand" 81 "Fire Research Corp" 80 "Twin Disc, Inc." 79 "Daimler Benz AG - Engine Division (PBM)" 78 "Frank W. Murphy Manufacturing, Inc." 77 "Deere Power Systems Group" 76 "unused" 75 "Deere & Co. Agricultural Division" 74 "Eaton Axle-Brake Division" 73 "LeTourneau, Inc." 72 "Sisu Corporation" 71 "Vansco Electronics Ltd." 70 "Flex-Coil Limited" 69 "Trimble Navigation" 68 "Scania" 67 "Funk Manufacturing Company" 66 "John Deere Construction Equipment Division" 65 "MAN Nutzfahrzeuge AG" 64 "unused" 63 "ZF Industries Inc." 62 "Wabco" 61 "Volvo Truck Corp." 60 "Volvo Trucks North America Inc." 59 "VES Inc." 58 "SPX Corporation, OTC Division" 57 "Sauer-Danfoss Co." 56 "SAIC" 55 "Ryder System Inc." 54 "Meritor Wabco" 53 "Continental Automotive Systems US, Inc." 52 "Meritor Automotive, Inc." 51 "Robert Bosch GmbH" 50 "Robert Bosch Corp" 49 "RE America Inc." 48 "Pollak Alphabet" 47 "Phillips Semiconductor" 46 "Parasoft Computing Solutions" 45 "PACCAR" 44 "Nippondenso Co. Ltd." 43 "International Truck and Engine Corp. Vehicle Electronics" 42 "International Truck and Engine Corp. Engine Electronics" 41 "Motorola Inc." 40 "Motorola AIEG Inc." 39 "Microfirm Inc." 38 "Micro Processor Systems Inc." 37 "Mack Trucks Inc." 36 "Lucas Ltd." 35 "Kenworth Truck Co." 34 "Kelsey Hayes Co." 33 "John Deere" 32 "Jacobs Vehicle Systems" 31 "J Pollak Corp." 30 "Isuzu Motors Ltd." 29 "Hino Motors Ltd." 28 "Grote Ind. Inc." 27 "GMC" 26 "General Motors Corp., Service Technology Group" 25 "Daimler Trucks North America LLC" 24 "Ford Motor Co., Vehicle Controls" 23 "Ford Motor Co., Heavy Truck" 22 "Ford Motor Co., Electronic Concepts $ Systems" 21 "Echilin Inc., Midland Brake Inc." 20 "Eaton Ltd" 19 "Eaton Corp. Trucking Info Services" 18 "Eaton Corp, Transmission Division" 17 "Eaton Corp. Res & Dev" 16 "Eaton Corp." 15 "Dickey-John Corp." 14 "Detroit Diesel Corporation" 13 "Delco Electronics" 12 "Deere & Company, Precision Farming" 11 "Dearborn Group Inc." 10 "Cummins Engine Co." 9 "Chrysler Corp." 8 "Caterpillar Inc." 7 "Case Corp." 6 "Berifors Electronics AB" 5 "AMP Inc." 4 "Ametek-Dixson" 3 "Ametek, US Gauge Division" 2 "Allison Transmission, GMC" 1 "Allied Signal Inc." 0 "Reserved" 231 "Topcon Positioning Systems, Inc." 230 "Saucon Technologies" 229 "Garmin International Inc." 228 "ZF Marine Electronics" 227 "Lykketronic A/S" 226 "Monaco Coach Corporation" 225 "SKF" 224 "EMMI Network, S.L." 223 "Vaueo Retarder Co., Ltd." 263 "IMMI" 262 "HydraForce, Inc" 261 "Red Dot Corporation" 260 "Reichhardt GmbH" 259 "Jetter AG" 258 "ARAG" 257 "Honda Motor Co., Ltd" 256 "Tyco Electronics AMP" 255 "MEAS France" 254 "GE Sensing" 253 "Mobile Control Systems" 298 "Holley Performance" 297 "Zonar Systems Inc" 296 "micro dynamics GmbH" 295 "BEP Marine" 294 "Grayhill Inc." 293 "Spyder Controls Corp." 292 "IKUSI - Angel Iglesias S.A." 291 "Groeneveld Transport Efficiency BV" 290 "Kuebler GmbH" 289 "Watlow" 288 "Mitsubishi FUSO Truck & Bus Corp." 287 "NTech Industries, Inc" 286 "Coelmo srl" 285 "Sea Recovery Corp" 284 "Mobile Tech Chile" 283 "CWF Hamilton & Co Ltd" 282 "Medallion Instrumentation Systems" 281 "Precision Governors LLC" 311 "Patrick Power Products" 310 "TECNORD srl" 309 "Krauss-Maffei Wegmann GmbH & Co. KG" 308 "Cyntrx" 307 "MAS Technologies" 306 "Sleipner Motor AB" 305 "NovAtel Inc" 304 "EmpirBus AB" 303 "CTS Corporation" 302 "Nissin Kogyo Co., LTD" 301 "Parker Hannifin (UK) Ltd FDE group" 300 "Systron Donner Automotive" 299 "Rauch Landmaschinen GmbH" 280 "Leica Geosystems Pty Ltd" 279 "Geometris LP" 278 "Takata Electronics" 277 "LHP Telematics" 276 "Aqua-Hot Heating Systems" 275 "Navico Egersund AS" 274 "LTW Technology Co., LTD" 273 "Active Research Limited" 272 "Gross Mechanical Laboratories, Inc" 327 "Sonceboz SA" 326 "Akron Brass Company" 325 "ASM Automation Sensorik Messtechnik GmbH" 324 "Snap-on Diagnostics" 323 "Mobileye Vision Technologies Ltd." 322 "MICHENKA s.r.o." 321 "Ultra Electronics, Electrics" 320 "Miedema Landbouwwerktuigenfabriek B.V." 319 "Cadec Global" 318 "SAT Plan" 317 "Navtronics Bvba" 316 "ITT Flow Control" 315 "Icom Incorporated" 314 "CSM GmbH" 313 "Ilmor Engineering, Inc" 312 "Lectronix, Inc." 271 "Cole Hersee" 270 "Tennant" 269 "Saft America Inc.,  Space & Defense Division" 268 "Accurate Technologies" 267 "Red Lion Controls, Inc" 266 "International Thermal Research Ltd" 265 "MTS Sensor Technologie GmbH" 264 "Autolync" 248 "Cooper Standard Automotive Active Systems Group" 247 "ePULSE" 246 "Class 1, Inc" 245 "Capstan Ag Systems, Inc." 244 "Techno-Matic" 243 "eRide, Inc." 242 "Kokusandenki Co. Ltd" 241 "Schneider Automation SAS " 240 "Vanair Mfg" 239 "May & Scofield Ltd" 238 "ZF Friedrichshafen AG" 237 "Agtron Enterprises Inc" 236 "Norac Systems International Inc" 235 "SailorMade Marine Telemetry - Tetra Technology Ltd." 234 "Mondial electronic GmbH" ;
VAL_ 2565799678 VehicleSystem 0 "Non-specific System" 127 "Not Available" ;
VAL_ 2565799678 VehicleSystem5 127 "Not Available" 0 "Ind. Process Control Stationary" ;
VAL_ 2565799678 VehicleSystem4 100 "Deck/Cargo/Fishing equip. sys" 90 "Environmental (HVAC) Systems" 80 "Instrumentation/General Systems" 70 "Communications Systems" 60 "Navigation Systems" 50 "Propulsion Systems" 40 "Steering Systems" 30 "Power Mgmt and lighting systems" 25 "Gateway" 20 "Safety Systems" 10 "System Tools" 127 "Not Available" 0 "Non-specific System" ;
VAL_ 2565799678 VehicleSystem3 8 "Grader" 7 "Four Wheel Drive Loader" 6 "Forklift" 5 "Excavator" 4 "Crawler" 3 "Backhoe" 2 "Articulated Dump Truck" 1 "Skid Steer Loader" 127 "Not Available" 0 "Non-specific System" ;
VAL_ 2565799678 VehicleSystem2 16 "Skidder" 15 "Earth Work" 14 "Special Crops" 13 "Powered Auxiliary Device" 12 "Farm Yard Operations" 11 "Transport/Trailer" 10 "Irrigation" 9 "Forage" 8 "Root Harvesters" 7 "Harvesters" 6 "Sprayers" 5 "Fertilizers" 4 "Planters/Seeders" 3 "Secondary Tillage" 2 "Tillage" 1 "Tractor" 127 "Not Available" 0 "Non-specific System" ;
VAL_ 2565799678 VehicleSystem1 2 "Trailer" 1 "Tractor" 127 "Not Available" 0 "Non-specific System" ;
VAL_ 2632777470 PGNumber 255 "NotAvailable" ;
VAL_ 2632777470 ControlByte 24 "EAbort" 23 "EEoMACK" 22 "EDPO" 21 "ECTS" 20 "ERTS" 255 "Abort" 32 "BAM" 19 "EoMA" 17 "CTS" 16 "RTS" ;
VAL_ 2563374846 UseTransferMode 3 "NA" 2 "Undefined" 1 "Yes" 0 "No" ;
